VERSION ""

NS_ :

BS_:

BU_: PowertrainControlModule AtmosphericSensor SafetyRestraintSystem2 Aftertreatment_2_GasOutlet Aftertreatment_2_GasIntake DieselParticulateFilterControl Turbocharger SafetyRestraintSystem1 CabDisplay2 Aftertreatment_1_GasOutlet Aftertreatment_1_GasIntake OnBoardDataLogger OffBoardDiagnosticTool2 OffBoardDiagnosticTool1 FileServer ParkingBrakeController SeatController2 FanDriveController SteeringColumnUnit CommunicationUnitRadio CommunicationUnitSatellite CommunicationUnitCellular PropulsionBatteryCharger ChassisController2 ChassisController1 EngineValveControl AuxiliaryHeater2 AuxiliaryHeater1 ClutchUnit RampControl InformationSystem1 SuspensionSystemController2 OilSensor VehicleDynamicStability ExhaustEmissionController TransmissionDisplay2 TransmissionDisplay1 ClimateControl2 WaterPumpController RearAxleSteeringController LightingOperatorControl SeatController1 IgnitionController2 IgnitionController1 TirePressureController CabController2 CabController1 PneumaticSystemController SuspensionSystemController1 HydraulicPumpController EnduranceBrakingSystem RetarderExhaustEngine2 OnBoardDiagnosticUnit HeadwayController RetarderExhaustEngine1 CabDisplay1 ManagementComputer VirtualTerminal OffVehicleGateway PowerTakeOffFront HitchControl AuxiliaryValveControl BodyController TractorTrailerBridge1 StarterSystem ElectricalSystem VehicleSecurity VehicleNavigation AerodynamicControl ElectricalChargingSystem ClimateControl1 TripRecorder InstrumentCluster SuspensionDriveAxle2 SuspensionDriveAxle1 SuspensionSteerAxle SteeringController FuelSystem CruiseControl RetarderDriveline RetarderEngine BrakesDriveAxle2 BrakesDriveAxle1 BrakesSystemController BrakesSteerAxle AxleDrive2 AxleDrive1 AxleSteering PowerTakeOff ShiftConsoleSecondary ShiftConsolePrimary Transmission2 Transmission1 Engine2 Engine1

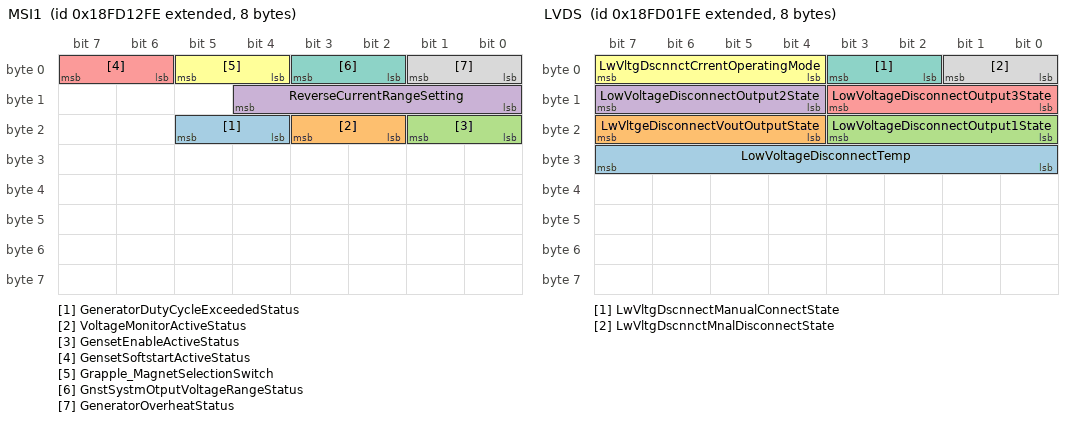
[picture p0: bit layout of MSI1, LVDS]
BO_ 2566722302 MSI1: 8 Vector__XXX
 SG_ GeneratorDutyCycleExceededStatus : 20|2@1+ (1,0) [0|3] "" Vector__XXX
 SG_ VoltageMonitorActiveStatus : 18|2@1+ (1,0) [0|3] "" Vector__XXX
 SG_ GensetEnableActiveStatus : 16|2@1+ (1,0) [0|3] "" Vector__XXX
 SG_ ReverseCurrentRangeSetting : 8|5@1+ (1,0) [0|31] "" Vector__XXX
 SG_ GensetSoftstartActiveStatus : 6|2@1+ (1,0) [0|3] "" Vector__XXX
 SG_ Grapple_MagnetSelectionSwitch : 4|2@1+ (1,0) [0|3] "" Vector__XXX
 SG_ GnstSystmOtputVoltageRangeStatus : 2|2@1+ (1,0) [0|3] "" Vector__XXX
 SG_ GeneratorOverheatStatus : 0|2@1+ (1,0) [0|3] "" Vector__XXX

BO_ 2566722558 MSCI: 8 Vector__XXX
 SG_ MagnetRatedPower : 8|16@1+ (0.5,0) [0|32127.5] "kW" Vector__XXX
 SG_ MagnetBoostTime : 0|8@1+ (0.25,0) [0|62.5] "s" Vector__XXX

BO_ 2560032510 LVDSOM: 8 Vector__XXX
 SG_ LwVltgDscnnctDsiredOperatingMode : 0|4@1+ (1,0) [0|15] "" Vector__XXX

BO_ 2566717950 LVDS: 8 Vector__XXX
 SG_ LowVoltageDisconnectTemp : 24|8@1+ (1,-40) [-40|210] "°C" Vector__XXX
 SG_ LwVltgeDisconnectVoutOutputState : 20|4@1+ (1,0) [0|15] "" Vector__XXX
 SG_ LowVoltageDisconnectOutput1State : 16|4@1+ (1,0) [0|15] "" Vector__XXX
 SG_ LowVoltageDisconnectOutput2State : 12|4@1+ (1,0) [0|15] "" Vector__XXX
 SG_ LowVoltageDisconnectOutput3State : 8|4@1+ (1,0) [0|15] "" Vector__XXX
 SG_ LwVltgDscnnctCrrentOperatingMode : 4|4@1+ (1,0) [0|15] "" Vector__XXX
 SG_ LwVltgDscnnectManualConnectState : 2|2@1+ (1,0) [0|3] "" Vector__XXX
 SG_ LwVltgDscnnctMnalDisconnectState : 0|2@1+ (1,0) [0|3] "" Vector__XXX

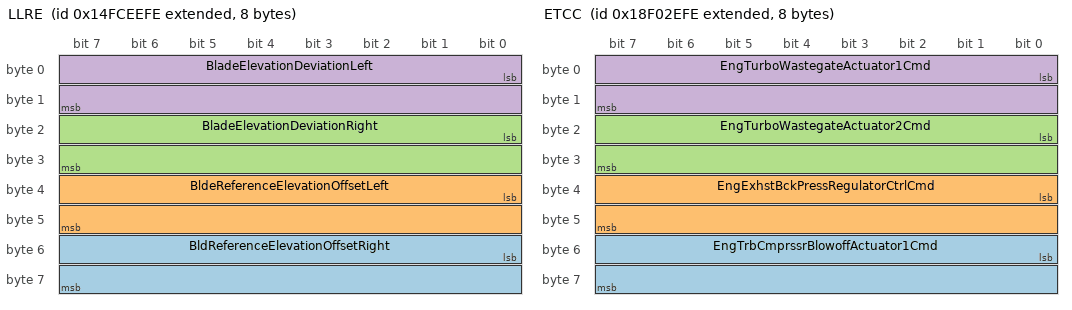
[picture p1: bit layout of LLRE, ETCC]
BO_ 2499604222 LLRE: 8 Vector__XXX
 SG_ BldReferenceElevationOffsetRight : 48|16@1+ (1,-32000) [-32000|32255] "mm" Vector__XXX
 SG_ BldeReferenceElevationOffsetLeft : 32|16@1+ (1,-32000) [-32000|32255] "mm" Vector__XXX
 SG_ BladeElevationDeviationRight : 16|16@1+ (1,-32000) [-32000|32255] "mm" Vector__XXX
 SG_ BladeElevationDeviationLeft : 0|16@1+ (1,-32000) [-32000|32255] "mm" Vector__XXX

BO_ 2358902526 JLCM: 8 Vector__XXX
 SG_ Joystick3Lamp10Cmd : 58|2@1+ (1,0) [0|3] "" Vector__XXX
 SG_ Joystick3Lamp9Cmd : 56|2@1+ (1,0) [0|3] "" Vector__XXX
 SG_ Joystick3Lamp8Cmd : 54|2@1+ (1,0) [0|3] "" Vector__XXX
 SG_ Joystick3Lamp7Cmd : 52|2@1+ (1,0) [0|3] "" Vector__XXX
 SG_ Joystick3Lamp6Cmd : 50|2@1+ (1,0) [0|3] "" Vector__XXX
 SG_ Joystick3Lamp5Cmd : 48|2@1+ (1,0) [0|3] "" Vector__XXX
 SG_ Joystick3Lamp4Cmd : 46|2@1+ (1,0) [0|3] "" Vector__XXX
 SG_ Joystick3Lamp3Cmd : 44|2@1+ (1,0) [0|3] "" Vector__XXX
 SG_ Joystick3Lamp2Cmd : 42|2@1+ (1,0) [0|3] "" Vector__XXX
 SG_ Joystick3Lamp1Cmd : 40|2@1+ (1,0) [0|3] "" Vector__XXX
 SG_ Joystick2Lamp10Cmd : 38|2@1+ (1,0) [0|3] "" Vector__XXX
 SG_ Joystick2Lamp9Cmd : 36|2@1+ (1,0) [0|3] "" Vector__XXX
 SG_ Joystick2Lamp8Cmd : 34|2@1+ (1,0) [0|3] "" Vector__XXX
 SG_ Joystick2Lamp7Cmd : 32|2@1+ (1,0) [0|3] "" Vector__XXX
 SG_ Joystick2Lamp6Cmd : 30|2@1+ (1,0) [0|3] "" Vector__XXX
 SG_ Joystick2Lamp5Cmd : 28|2@1+ (1,0) [0|3] "" Vector__XXX
 SG_ Joystick2Lamp4Cmd : 26|2@1+ (1,0) [0|3] "" Vector__XXX
 SG_ Joystick2Lamp3Cmd : 24|2@1+ (1,0) [0|3] "" Vector__XXX
 SG_ Joystick2Lamp2Cmd : 22|2@1+ (1,0) [0|3] "" Vector__XXX
 SG_ Joystick2Lamp1Cmd : 20|2@1+ (1,0) [0|3] "" Vector__XXX
 SG_ Joystick1Lamp10Cmd : 18|2@1+ (1,0) [0|3] "" Vector__XXX
 SG_ Joystick1Lamp9Cmd : 16|2@1+ (1,0) [0|3] "" Vector__XXX
 SG_ Joystick1Lamp8Cmd : 14|2@1+ (1,0) [0|3] "" Vector__XXX
 SG_ Joystick1Lamp7Cmd : 12|2@1+ (1,0) [0|3] "" Vector__XXX
 SG_ Joystick1Lamp6Cmd : 10|2@1+ (1,0) [0|3] "" Vector__XXX
 SG_ Joystick1Lamp5Cmd : 8|2@1+ (1,0) [0|3] "" Vector__XXX
 SG_ Joystick1Lamp4Cmd : 6|2@1+ (1,0) [0|3] "" Vector__XXX
 SG_ Joystick1Lamp3Cmd : 4|2@1+ (1,0) [0|3] "" Vector__XXX
 SG_ Joystick1Lamp2Cmd : 2|2@1+ (1,0) [0|3] "" Vector__XXX
 SG_ Joystick1Lamp1Cmd : 0|2@1+ (1,0) [0|3] "" Vector__XXX

BO_ 2566711550 IVAC: 8 Vector__XXX
 SG_ IntkVlvActtnSystmOlPrss2SlndCtrl : 2|2@1+ (1,0) [0|3] "" Vector__XXX
 SG_ IntkVlvActtnSystmOlPrss1SlndCtrl : 0|2@1+ (1,0) [0|3] "" Vector__XXX

BO_ 2566719998 HRLFC: 8 Vector__XXX
 SG_ HighResolutionEngTotalFuelUsed : 32|32@1+ (0.001,0) [0|4211081.215] "L" Vector__XXX
 SG_ HighResolutionEngTripFuel : 0|32@1+ (0.001,0) [0|4211081.215] "L" Vector__XXX

BO_ 2565877502 ETCC: 8 Vector__XXX
 SG_ EngTrbCmprssrBlowoffActuator1Cmd : 48|16@1+ (0.0025,0) [0|100] "%" Vector__XXX
 SG_ EngExhstBckPressRegulatorCtrlCmd : 32|16@1+ (0.0025,0) [0|100] "%" Vector__XXX
 SG_ EngTurboWastegateActuator2Cmd : 16|16@1+ (0.0025,0) [0|160.6375] "%" Vector__XXX
 SG_ EngTurboWastegateActuator1Cmd : 0|16@1+ (0.0025,0) [0|160.6375] "%" Vector__XXX

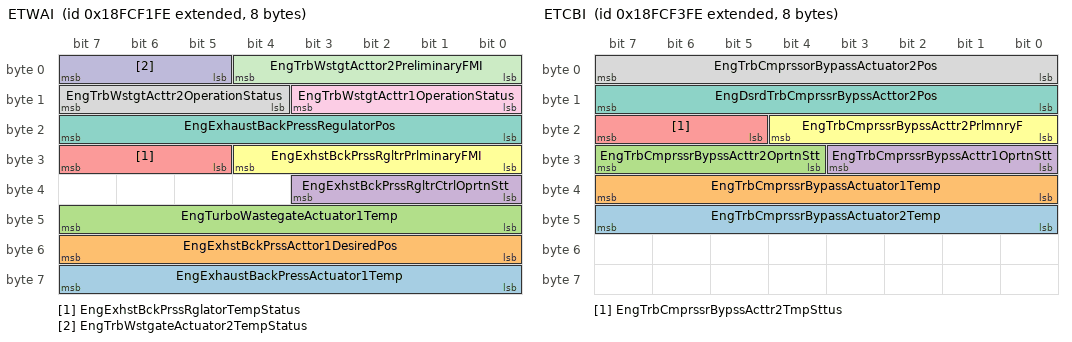
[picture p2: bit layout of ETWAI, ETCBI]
BO_ 2566713854 ETWAI: 8 Vector__XXX
 SG_ EngExhaustBackPressActuator1Temp : 56|8@1+ (1,-40) [-40|210] "°C" Vector__XXX
 SG_ EngExhstBckPrssActtor1DesiredPos : 48|8@1+ (0.4,0) [0|100] "%" Vector__XXX
 SG_ EngTurboWastegateActuator1Temp : 40|8@1+ (1,-40) [-40|210] "°C" Vector__XXX
 SG_ EngExhstBckPrssRgltrCtrlOprtnStt : 32|4@1+ (1,0) [0|15] "" Vector__XXX
 SG_ EngExhstBckPrssRglatorTempStatus : 29|3@1+ (1,0) [0|7] "" Vector__XXX
 SG_ EngExhstBckPrssRgltrPrlminaryFMI : 24|5@1+ (1,0) [0|31] "" Vector__XXX
 SG_ EngExhaustBackPressRegulatorPos : 16|8@1+ (0.4,0) [0|100] "%" Vector__XXX
 SG_ EngTrbWstgtActtr2OperationStatus : 12|4@1+ (1,0) [0|15] "" Vector__XXX
 SG_ EngTrbWstgtActtr1OperationStatus : 8|4@1+ (1,0) [0|15] "" Vector__XXX
 SG_ EngTrbWstgateActuator2TempStatus : 5|3@1+ (1,0) [0|7] "" Vector__XXX
 SG_ EngTrbWstgtActtor2PreliminaryFMI : 0|5@1+ (1,0) [0|31] "" Vector__XXX

BO_ 2566714366 ETCBI: 8 Vector__XXX
 SG_ EngTrbCmprssrBypassActuator2Temp : 40|8@1+ (1,-40) [-40|210] "°C" Vector__XXX
 SG_ EngTrbCmprssrBypassActuator1Temp : 32|8@1+ (1,-40) [-40|210] "°C" Vector__XXX
 SG_ EngTrbCmprssrBypssActtr2OprtnStt : 28|4@1+ (1,0) [0|15] "" Vector__XXX
 SG_ EngTrbCmprssrBypssActtr1OprtnStt : 24|4@1+ (1,0) [0|15] "" Vector__XXX
 SG_ EngTrbCmprssrBypssActtr2TmpSttus : 21|3@1+ (1,0) [0|7] "" Vector__XXX
 SG_ EngTrbCmprssrBypssActtr2PrlmnryF : 16|5@1+ (1,0) [0|31] "" Vector__XXX
 SG_ EngDsrdTrbCmprssrBypssActtor2Pos : 8|8@1+ (0.4,0) [0|100] "%" Vector__XXX
 SG_ EngTrbCmprssorBypassActuator2Pos : 0|8@1+ (0.4,0) [0|100] "%" Vector__XXX

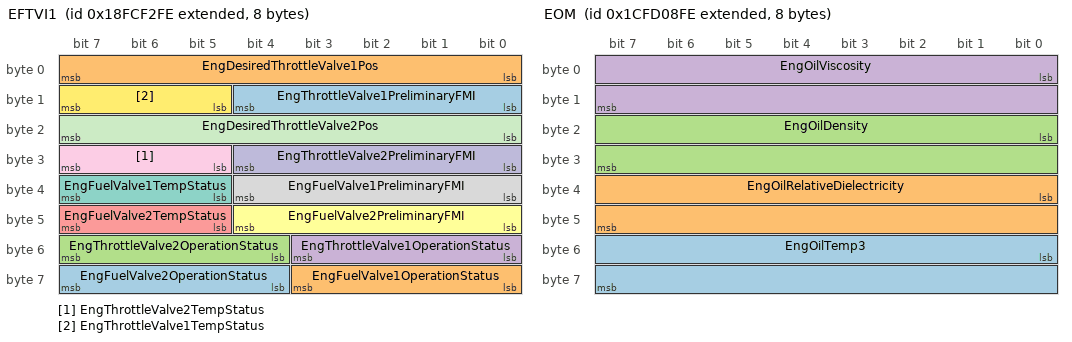
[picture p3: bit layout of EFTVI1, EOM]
BO_ 2566714110 EFTVI1: 8 Vector__XXX
 SG_ EngFuelValve2OperationStatus : 60|4@1+ (1,0) [0|15] "" Vector__XXX
 SG_ EngFuelValve1OperationStatus : 56|4@1+ (1,0) [0|15] "" Vector__XXX
 SG_ EngThrottleValve2OperationStatus : 52|4@1+ (1,0) [0|15] "" Vector__XXX
 SG_ EngThrottleValve1OperationStatus : 48|4@1+ (1,0) [0|15] "" Vector__XXX
 SG_ EngFuelValve2TempStatus : 45|3@1+ (1,0) [0|7] "" Vector__XXX
 SG_ EngFuelValve2PreliminaryFMI : 40|5@1+ (1,0) [0|31] "" Vector__XXX
 SG_ EngFuelValve1TempStatus : 37|3@1+ (1,0) [0|7] "" Vector__XXX
 SG_ EngFuelValve1PreliminaryFMI : 32|5@1+ (1,0) [0|31] "" Vector__XXX
 SG_ EngThrottleValve2TempStatus : 29|3@1+ (1,0) [0|7] "" Vector__XXX
 SG_ EngThrottleValve2PreliminaryFMI : 24|5@1+ (1,0) [0|31] "" Vector__XXX
 SG_ EngDesiredThrottleValve2Pos : 16|8@1+ (0.4,0) [0|100] "%" Vector__XXX
 SG_ EngThrottleValve1TempStatus : 13|3@1+ (1,0) [0|7] "" Vector__XXX
 SG_ EngThrottleValve1PreliminaryFMI : 8|5@1+ (1,0) [0|31] "" Vector__XXX
 SG_ EngDesiredThrottleValve1Pos : 0|8@1+ (0.4,0) [0|100] "%" Vector__XXX

BO_ 2566717438 ET5: 8 Vector__XXX
 SG_ EngExhstGsRcrcltn2MxerIntakeTemp : 16|16@1+ (0.03125,-273) [-273|1734.96875] "°C" Vector__XXX
 SG_ EngExhaustGasRecirculation2Temp : 0|16@1+ (0.03125,-273) [-273|1734.96875] "°C" Vector__XXX

BO_ 2633828606 EOM: 8 Vector__XXX
 SG_ EngOilTemp3 : 48|16@1+ (0.03125,-273) [-273|1734.96875] "°C" Vector__XXX
 SG_ EngOilRelativeDielectricity : 32|16@1+ (0.0001220703125,0) [0|7.844] "" Vector__XXX
 SG_ EngOilDensity : 16|16@1+ (3.052E-005,0) [0|1.961] "g/cc" Vector__XXX
 SG_ EngOilViscosity : 0|16@1+ (0.015625,0) [0|1003.984375] "Cp" Vector__XXX

BO_ 2499607550 EMAP: 8 Vector__XXX
 SG_ EngExhstMnfldBnk2FlwBlncVlvActtr : 16|16@1+ (0.0025,0) [0|160.6375] "%" Vector__XXX
 SG_ EngExhstMnfldBnk1FlwBlncVlvActtr : 0|16@1+ (0.0025,0) [0|160.6375] "%" Vector__XXX

BO_ 2633825534 EMAC: 8 Vector__XXX
 SG_ EngExhstMnfldBnk2FlwBlncVlvActtr : 16|16@1+ (0.0025,0) [0|160.6375] "%" Vector__XXX
 SG_ EngExhstMnfldBnk1FlwBlncVlvActtr : 0|16@1+ (0.0025,0) [0|160.6375] "%" Vector__XXX

BO_ 2365400574 EJM9: 8 Vector__XXX
 SG_ Joystick9Button13PressedStatus : 62|2@1+ (1,0) [0|3] "" Vector__XXX
 SG_ Joystick9Button14PressedStatus : 60|2@1+ (1,0) [0|3] "" Vector__XXX
 SG_ Joystick9Button15PressedStatus : 58|2@1+ (1,0) [0|3] "" Vector__XXX
 SG_ Joystick9Button16PressedStatus : 56|2@1+ (1,0) [0|3] "" Vector__XXX
 SG_ Jystick9GripXAxisDetentPosStatus : 54|2@1+ (1,0) [0|3] "" Vector__XXX
 SG_ Jystick9GripYAxisDetentPosStatus : 52|2@1+ (1,0) [0|3] "" Vector__XXX
 SG_ Jystick9ThetaAxisDetentPosStatus : 50|2@1+ (1,0) [0|3] "" Vector__XXX
 SG_ Joystick9ThetaAxisPos : 38|10@1+ (0.1,0) [0|102] "%" Vector__XXX
 SG_ Jystck9ThtAxsClckwsPstvPosStatus : 36|2@1+ (1,0) [0|3] "" Vector__XXX
 SG_ Jystck9ThtAxsCntrClckwsNgtvPsStt : 34|2@1+ (1,0) [0|3] "" Vector__XXX
 SG_ Jystck9ThetaAxisNeutralPosStatus : 32|2@1+ (1,0) [0|3] "" Vector__XXX
 SG_ Joystick9GripYAxisPos : 22|10@1+ (0.1,0) [0|102] "%" Vector__XXX
 SG_ Jystck9GrpYAxsLvrFrwrdPstvPsStts : 20|2@1+ (1,0) [0|3] "" Vector__XXX
 SG_ Jystck9GrpYAxsLvrBckNgtvPsStatus : 18|2@1+ (1,0) [0|3] "" Vector__XXX
 SG_ Jystck9GripYAxisNeutralPosStatus : 16|2@1+ (1,0) [0|3] "" Vector__XXX
 SG_ Joystick9GripXAxisPos : 6|10@1+ (0.1,0) [0|102] "%" Vector__XXX
 SG_ Jystck9GrpXAxsLvrRghtPstvPsSttus : 4|2@1+ (1,0) [0|3] "" Vector__XXX
 SG_ Jystck9GrpXAxsLvrLftNgtvPsStatus : 2|2@1+ (1,0) [0|3] "" Vector__XXX
 SG_ Jystck9GripXAxisNeutralPosStatus : 0|2@1+ (1,0) [0|3] "" Vector__XXX

BO_ 2365401086 EJM8: 8 Vector__XXX
 SG_ Joystick8Button13PressedStatus : 62|2@1+ (1,0) [0|3] "" Vector__XXX
 SG_ Joystick8Button14PressedStatus : 60|2@1+ (1,0) [0|3] "" Vector__XXX
 SG_ Joystick8Button15PressedStatus : 58|2@1+ (1,0) [0|3] "" Vector__XXX
 SG_ Joystick8Button16PressedStatus : 56|2@1+ (1,0) [0|3] "" Vector__XXX
 SG_ Jystick8GripXAxisDetentPosStatus : 54|2@1+ (1,0) [0|3] "" Vector__XXX
 SG_ Jystick8GripYAxisDetentPosStatus : 52|2@1+ (1,0) [0|3] "" Vector__XXX
 SG_ Jystick8ThetaAxisDetentPosStatus : 50|2@1+ (1,0) [0|3] "" Vector__XXX
 SG_ Joystick8ThetaAxisPos : 38|10@1+ (0.1,0) [0|102] "%" Vector__XXX
 SG_ Jystck8ThtAxsClckwsPstvPosStatus : 36|2@1+ (1,0) [0|3] "" Vector__XXX
 SG_ Jystck8ThtAxsCntrClckwsNgtvPsStt : 34|2@1+ (1,0) [0|3] "" Vector__XXX
 SG_ Jystck8ThetaAxisNeutralPosStatus : 32|2@1+ (1,0) [0|3] "" Vector__XXX
 SG_ Joystick8GripYAxisPos : 22|10@1+ (0.1,0) [0|102] "%" Vector__XXX
 SG_ Jystck8GrpYAxsLvrFrwrdPstvPsStts : 20|2@1+ (1,0) [0|3] "" Vector__XXX
 SG_ Jystck8GrpYAxsLvrBckNgtvPsStatus : 18|2@1+ (1,0) [0|3] "" Vector__XXX
 SG_ Jystck8GripYAxisNeutralPosStatus : 16|2@1+ (1,0) [0|3] "" Vector__XXX
 SG_ Joystick8GripXAxisPos : 6|10@1+ (0.1,0) [0|102] "%" Vector__XXX
 SG_ Jystck8GrpXAxsLvrRghtPstvPsSttus : 4|2@1+ (1,0) [0|3] "" Vector__XXX
 SG_ Jystck8GrpXAxsLvrLftNgtvPsStatus : 2|2@1+ (1,0) [0|3] "" Vector__XXX
 SG_ Jystck8GripXAxisNeutralPosStatus : 0|2@1+ (1,0) [0|3] "" Vector__XXX

BO_ 2365401598 EJM7: 8 Vector__XXX
 SG_ Joystick7Button13PressedStatus : 62|2@1+ (1,0) [0|3] "" Vector__XXX
 SG_ Joystick7Button14PressedStatus : 60|2@1+ (1,0) [0|3] "" Vector__XXX
 SG_ Joystick7Button15PressedStatus : 58|2@1+ (1,0) [0|3] "" Vector__XXX
 SG_ Joystick7Button16PressedStatus : 56|2@1+ (1,0) [0|3] "" Vector__XXX
 SG_ Jystick7GripXAxisDetentPosStatus : 54|2@1+ (1,0) [0|3] "" Vector__XXX
 SG_ Jystick7GripYAxisDetentPosStatus : 52|2@1+ (1,0) [0|3] "" Vector__XXX
 SG_ Jystick7ThetaAxisDetentPosStatus : 50|2@1+ (1,0) [0|3] "" Vector__XXX
 SG_ Joystick7ThetaAxisPos : 38|10@1+ (0.1,0) [0|102] "%" Vector__XXX
 SG_ Jystck7ThtAxsClckwsPstvPosStatus : 36|2@1+ (1,0) [0|3] "" Vector__XXX
 SG_ Jystck7ThtAxsCntrClckwsNgtvPsStt : 34|2@1+ (1,0) [0|3] "" Vector__XXX
 SG_ Jystck7ThetaAxisNeutralPosStatus : 32|2@1+ (1,0) [0|3] "" Vector__XXX
 SG_ Joystick7GripYAxisPos : 22|10@1+ (0.1,0) [0|102] "%" Vector__XXX
 SG_ Jystck7GrpYAxsLvrFrwrdPstvPsStts : 20|2@1+ (1,0) [0|3] "" Vector__XXX
 SG_ Jystck7GrpYAxsLvrBckNgtvPsStatus : 18|2@1+ (1,0) [0|3] "" Vector__XXX
 SG_ Jystck7GripYAxisNeutralPosStatus : 16|2@1+ (1,0) [0|3] "" Vector__XXX
 SG_ Joystick7GripXAxisPos : 6|10@1+ (0.1,0) [0|102] "%" Vector__XXX
 SG_ Jystck7GrpXAxsLvrRghtPstvPsSttus : 4|2@1+ (1,0) [0|3] "" Vector__XXX
 SG_ Jystck7GrpXAxsLvrLftNgtvPsStatus : 2|2@1+ (1,0) [0|3] "" Vector__XXX
 SG_ Jystck7GripXAxisNeutralPosStatus : 0|2@1+ (1,0) [0|3] "" Vector__XXX

BO_ 2365402110 EJM6: 8 Vector__XXX
 SG_ Joystick6Button13PressedStatus : 62|2@1+ (1,0) [0|3] "" Vector__XXX
 SG_ Joystick6Button14PressedStatus : 60|2@1+ (1,0) [0|3] "" Vector__XXX
 SG_ Joystick6Button15PressedStatus : 58|2@1+ (1,0) [0|3] "" Vector__XXX
 SG_ Joystick6Button16PressedStatus : 56|2@1+ (1,0) [0|3] "" Vector__XXX
 SG_ Jystick6GripXAxisDetentPosStatus : 54|2@1+ (1,0) [0|3] "" Vector__XXX
 SG_ Jystick6GripYAxisDetentPosStatus : 52|2@1+ (1,0) [0|3] "" Vector__XXX
 SG_ Jystick6ThetaAxisDetentPosStatus : 50|2@1+ (1,0) [0|3] "" Vector__XXX
 SG_ Joystick6ThetaAxisPos : 38|10@1+ (0.1,0) [0|102] "%" Vector__XXX
 SG_ Jystck6ThtAxsClckwsPstvPosStatus : 36|2@1+ (1,0) [0|3] "" Vector__XXX
 SG_ Jystck6ThtAxsCntrClckwsNgtvPsStt : 34|2@1+ (1,0) [0|3] "" Vector__XXX
 SG_ Jystck6ThetaAxisNeutralPosStatus : 32|2@1+ (1,0) [0|3] "" Vector__XXX
 SG_ Joystick6GripYAxisPos : 22|10@1+ (0.1,0) [0|102] "%" Vector__XXX
 SG_ Jystck6GrpYAxsLvrFrwrdPstvPsStts : 20|2@1+ (1,0) [0|3] "" Vector__XXX
 SG_ Jystck6GrpYAxsLvrBckNgtvPsStatus : 18|2@1+ (1,0) [0|3] "" Vector__XXX
 SG_ Jystck6GripYAxisNeutralPosStatus : 16|2@1+ (1,0) [0|3] "" Vector__XXX
 SG_ Joystick6GripXAxisPos : 6|10@1+ (0.1,0) [0|102] "%" Vector__XXX
 SG_ Jystck6GrpXAxsLvrRghtPstvPsSttus : 4|2@1+ (1,0) [0|3] "" Vector__XXX
 SG_ Jystck6GrpXAxsLvrLftNgtvPsStatus : 2|2@1+ (1,0) [0|3] "" Vector__XXX
 SG_ Jystck6GripXAxisNeutralPosStatus : 0|2@1+ (1,0) [0|3] "" Vector__XXX

BO_ 2365402622 EJM5: 8 Vector__XXX
 SG_ Joystick5Button13PressedStatus : 62|2@1+ (1,0) [0|3] "" Vector__XXX
 SG_ Joystick5Button14PressedStatus : 60|2@1+ (1,0) [0|3] "" Vector__XXX
 SG_ Joystick5Button15PressedStatus : 58|2@1+ (1,0) [0|3] "" Vector__XXX
 SG_ Joystick5Button16PressedStatus : 56|2@1+ (1,0) [0|3] "" Vector__XXX
 SG_ Jystick5GripXAxisDetentPosStatus : 54|2@1+ (1,0) [0|3] "" Vector__XXX
 SG_ Jystick5GripYAxisDetentPosStatus : 52|2@1+ (1,0) [0|3] "" Vector__XXX
 SG_ Jystick5ThetaAxisDetentPosStatus : 50|2@1+ (1,0) [0|3] "" Vector__XXX
 SG_ Joystick5ThetaAxisPos : 38|10@1+ (0.1,0) [0|102] "%" Vector__XXX
 SG_ Jystck5ThtAxsClckwsPstvPosStatus : 36|2@1+ (1,0) [0|3] "" Vector__XXX
 SG_ Jystck5ThtAxsCntrClckwsNgtvPsStt : 34|2@1+ (1,0) [0|3] "" Vector__XXX
 SG_ Jystck5ThetaAxisNeutralPosStatus : 32|2@1+ (1,0) [0|3] "" Vector__XXX
 SG_ Joystick5GripYAxisPos : 22|10@1+ (0.1,0) [0|102] "%" Vector__XXX
 SG_ Jystck5GrpYAxsLvrFrwrdPstvPsStts : 20|2@1+ (1,0) [0|3] "" Vector__XXX
 SG_ Jystck5GrpYAxsLvrBckNgtvPsStatus : 18|2@1+ (1,0) [0|3] "" Vector__XXX
 SG_ Jystck5GripYAxisNeutralPosStatus : 16|2@1+ (1,0) [0|3] "" Vector__XXX
 SG_ Joystick5GripXAxisPos : 6|10@1+ (0.1,0) [0|102] "%" Vector__XXX
 SG_ Jystck5GrpXAxsLvrRghtPstvPsSttus : 4|2@1+ (1,0) [0|3] "" Vector__XXX
 SG_ Jystck5GrpXAxsLvrLftNgtvPsStatus : 2|2@1+ (1,0) [0|3] "" Vector__XXX
 SG_ Jystck5GripXAxisNeutralPosStatus : 0|2@1+ (1,0) [0|3] "" Vector__XXX

BO_ 2365403134 EJM4: 8 Vector__XXX
 SG_ Joystick4Button13PressedStatus : 62|2@1+ (1,0) [0|3] "" Vector__XXX
 SG_ Joystick4Button14PressedStatus : 60|2@1+ (1,0) [0|3] "" Vector__XXX
 SG_ Joystick4Button15PressedStatus : 58|2@1+ (1,0) [0|3] "" Vector__XXX
 SG_ Joystick4Button16PressedStatus : 56|2@1+ (1,0) [0|3] "" Vector__XXX
 SG_ Jystick4GripXAxisDetentPosStatus : 54|2@1+ (1,0) [0|3] "" Vector__XXX
 SG_ Jystick4GripYAxisDetentPosStatus : 52|2@1+ (1,0) [0|3] "" Vector__XXX
 SG_ Jystick4ThetaAxisDetentPosStatus : 50|2@1+ (1,0) [0|3] "" Vector__XXX
 SG_ Joystick4ThetaAxisPos : 38|10@1+ (0.1,0) [0|102] "%" Vector__XXX
 SG_ Jystck4ThtAxsClckwsPstvPosStatus : 36|2@1+ (1,0) [0|3] "" Vector__XXX
 SG_ Jystck4ThtAxsCntrClckwsNgtvPsStt : 34|2@1+ (1,0) [0|3] "" Vector__XXX
 SG_ Jystck4ThetaAxisNeutralPosStatus : 32|2@1+ (1,0) [0|3] "" Vector__XXX
 SG_ Joystick4GripYAxisPos : 22|10@1+ (0.1,0) [0|102] "%" Vector__XXX
 SG_ Jystck4GrpYAxsLvrFrwrdPstvPsStts : 20|2@1+ (1,0) [0|3] "" Vector__XXX
 SG_ Jystck4GrpYAxsLvrBckNgtvPsStatus : 18|2@1+ (1,0) [0|3] "" Vector__XXX
 SG_ Jystck4GripYAxisNeutralPosStatus : 16|2@1+ (1,0) [0|3] "" Vector__XXX
 SG_ Joystick4GripXAxisPos : 6|10@1+ (0.1,0) [0|102] "%" Vector__XXX
 SG_ Jystck4GrpXAxsLvrRghtPstvPsSttus : 4|2@1+ (1,0) [0|3] "" Vector__XXX
 SG_ Jystck4GrpXAxsLvrLftNgtvPsStatus : 2|2@1+ (1,0) [0|3] "" Vector__XXX
 SG_ Jystck4GripXAxisNeutralPosStatus : 0|2@1+ (1,0) [0|3] "" Vector__XXX

BO_ 2365400062 EJM10: 8 Vector__XXX
 SG_ Joystick10Button13PressedStatus : 62|2@1+ (1,0) [0|3] "" Vector__XXX
 SG_ Joystick10Button14PressedStatus : 60|2@1+ (1,0) [0|3] "" Vector__XXX
 SG_ Joystick10Button15PressedStatus : 58|2@1+ (1,0) [0|3] "" Vector__XXX
 SG_ Joystick10Button16PressedStatus : 56|2@1+ (1,0) [0|3] "" Vector__XXX
 SG_ Jystck10GripXAxisDetentPosStatus : 54|2@1+ (1,0) [0|3] "" Vector__XXX
 SG_ Jystck10GripYAxisDetentPosStatus : 52|2@1+ (1,0) [0|3] "" Vector__XXX
 SG_ Jystck10ThetaAxisDetentPosStatus : 50|2@1+ (1,0) [0|3] "" Vector__XXX
 SG_ Joystick10ThetaAxisPos : 38|10@1+ (0.1,0) [0|102] "%" Vector__XXX
 SG_ Jystck10ThtAxsClckwsPstvPsStatus : 36|2@1+ (1,0) [0|3] "" Vector__XXX
 SG_ Jystck10ThtAxsCntrClckwsNgtvPsSt : 34|2@1+ (1,0) [0|3] "" Vector__XXX
 SG_ Jystck10ThtaAxisNeutralPosStatus : 32|2@1+ (1,0) [0|3] "" Vector__XXX
 SG_ Joystick10GripYAxisPos : 22|10@1+ (0.1,0) [0|102] "%" Vector__XXX
 SG_ Jystck10GrpYAxsLvrFrwrdPstvPsStt : 20|2@1+ (1,0) [0|3] "" Vector__XXX
 SG_ Jystck10GrpYAxsLvrBckNgtvPsSttus : 18|2@1+ (1,0) [0|3] "" Vector__XXX
 SG_ Jystck10GrpYAxisNeutralPosStatus : 16|2@1+ (1,0) [0|3] "" Vector__XXX
 SG_ Joystick10GripXAxisPos : 6|10@1+ (0.1,0) [0|102] "%" Vector__XXX
 SG_ Jystck10GrpXAxsLvrRghtPstvPsStts : 4|2@1+ (1,0) [0|3] "" Vector__XXX
 SG_ Jystck10GrpXAxsLvrLftNgtvPsSttus : 2|2@1+ (1,0) [0|3] "" Vector__XXX
 SG_ Jystck10GrpXAxisNeutralPosStatus : 0|2@1+ (1,0) [0|3] "" Vector__XXX

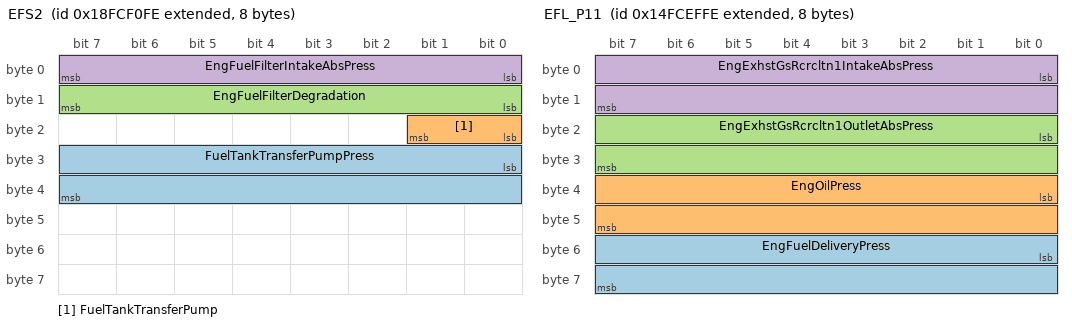
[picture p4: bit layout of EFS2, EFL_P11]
BO_ 2566713598 EFS2: 8 Vector__XXX
 SG_ FuelTankTransferPumpPress : 24|16@1+ (0.1,0) [0|6425.5] "kPa" Vector__XXX
 SG_ FuelTankTransferPump : 16|2@1+ (1,0) [0|3] "" Vector__XXX
 SG_ EngFuelFilterDegradation : 8|8@1+ (1,0) [0|250] "%" Vector__XXX
 SG_ EngFuelFilterIntakeAbsPress : 0|8@1+ (2,0) [0|500] "kPa" Vector__XXX

BO_ 2499604478 EFL_P11: 8 Vector__XXX
 SG_ EngFuelDeliveryPress : 48|16@1+ (0.1,0) [0|6425.5] "kPa" Vector__XXX
 SG_ EngOilPress : 32|16@1+ (0.1,0) [0|6425.5] "kPa" Vector__XXX
 SG_ EngExhstGsRcrcltn1OutletAbsPress : 16|16@1+ (0.1,0) [0|6425.5] "kPa" Vector__XXX
 SG_ EngExhstGsRcrcltn1IntakeAbsPress : 0|16@1+ (0.1,0) [0|6425.5] "kPa" Vector__XXX

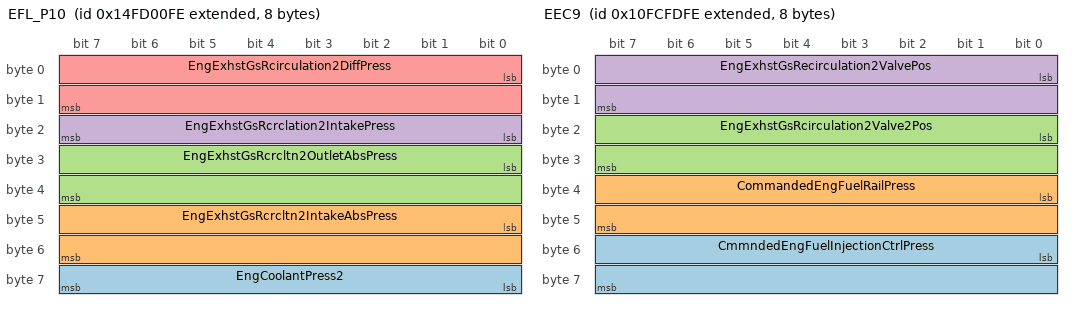
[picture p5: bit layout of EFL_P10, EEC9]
BO_ 2499608830 EFL_P10: 8 Vector__XXX
 SG_ EngCoolantPress2 : 56|8@1+ (2,0) [0|500] "kPa" Vector__XXX
 SG_ EngExhstGsRcrcltn2IntakeAbsPress : 40|16@1+ (0.1,0) [0|6425.5] "kPa" Vector__XXX
 SG_ EngExhstGsRcrcltn2OutletAbsPress : 24|16@1+ (0.1,0) [0|6425.5] "kPa" Vector__XXX
 SG_ EngExhstGsRcrclation2IntakePress : 16|8@1+ (2,0) [0|500] "kPa" Vector__XXX
 SG_ EngExhstGsRcirculation2DiffPress : 0|16@1+ (0.0078125,-250) [-250|251.99] "kPa" Vector__XXX

BO_ 2432499198 EEC9: 8 Vector__XXX
 SG_ CmmndedEngFuelInjectionCtrlPress : 48|16@1+ (0.00390625,0) [0|250.996] "MPa" Vector__XXX
 SG_ CommandedEngFuelRailPress : 32|16@1+ (0.00390625,0) [0|250.996] "MPa" Vector__XXX
 SG_ EngExhstGsRcirculation2Valve2Pos : 16|16@1+ (0.0025,0) [0|160.6375] "%" Vector__XXX
 SG_ EngExhstGsRecirculation2ValvePos : 0|16@1+ (0.0025,0) [0|160.6375] "%" Vector__XXX

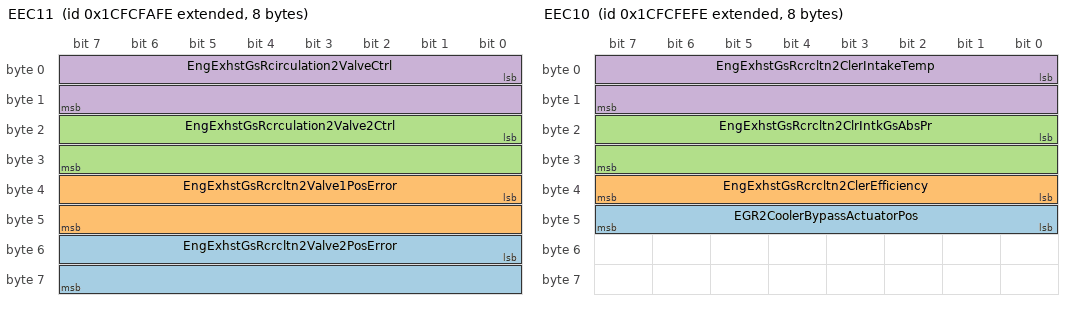
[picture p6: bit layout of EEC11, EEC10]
BO_ 2633825022 EEC11: 8 Vector__XXX
 SG_ EngExhstGsRcrcltn2Valve2PosError : 48|16@1+ (0.004,-125) [-125|132.02] "%" Vector__XXX
 SG_ EngExhstGsRcrcltn2Valve1PosError : 32|16@1+ (0.004,-125) [-125|132.02] "%" Vector__XXX
 SG_ EngExhstGsRcrculation2Valve2Ctrl : 16|16@1+ (0.0025,0) [0|160.6375] "%" Vector__XXX
 SG_ EngExhstGsRcirculation2ValveCtrl : 0|16@1+ (0.0025,0) [0|160.6375] "%" Vector__XXX

BO_ 2633826046 EEC10: 8 Vector__XXX
 SG_ EGR2CoolerBypassActuatorPos : 40|8@1+ (0.4,0) [0|100] "%" Vector__XXX
 SG_ EngExhstGsRcrcltn2ClerEfficiency : 32|8@1+ (0.4,0) [0|100] "%" Vector__XXX
 SG_ EngExhstGsRcrcltn2ClrIntkGsAbsPr : 16|16@1+ (0.5,0) [0|32127.5] "kPa" Vector__XXX
 SG_ EngExhstGsRcrcltn2ClerIntakeTemp : 0|16@1+ (0.03125,-273) [-273|1734.96875] "°C" Vector__XXX

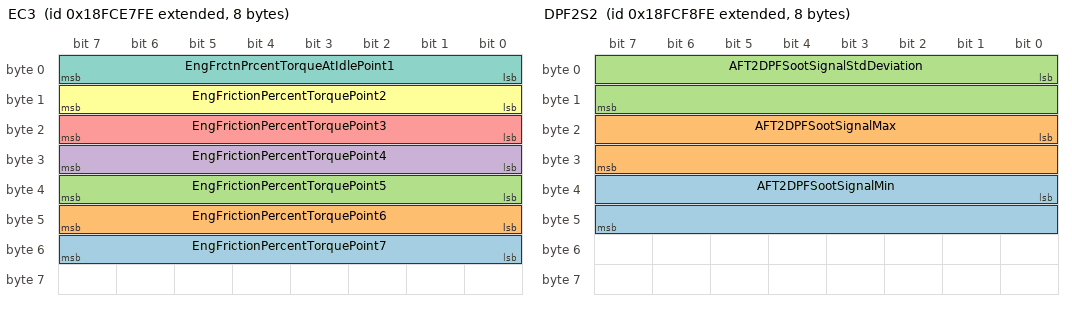
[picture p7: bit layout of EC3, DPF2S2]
BO_ 2566711294 EC3: 8 Vector__XXX
 SG_ EngFrictionPercentTorquePoint7 : 48|8@1+ (1,-125) [0|125] "%" Vector__XXX
 SG_ EngFrictionPercentTorquePoint6 : 40|8@1+ (1,-125) [0|125] "%" Vector__XXX
 SG_ EngFrictionPercentTorquePoint5 : 32|8@1+ (1,-125) [0|125] "%" Vector__XXX
 SG_ EngFrictionPercentTorquePoint4 : 24|8@1+ (1,-125) [0|125] "%" Vector__XXX
 SG_ EngFrictionPercentTorquePoint3 : 16|8@1+ (1,-125) [0|125] "%" Vector__XXX
 SG_ EngFrictionPercentTorquePoint2 : 8|8@1+ (1,-125) [0|125] "%" Vector__XXX
 SG_ EngFrctnPrcentTorqueAtIdlePoint1 : 0|8@1+ (1,-125) [0|125] "%" Vector__XXX

BO_ 2566749438 DPFC1: 8 Vector__XXX
 SG_ DslPrtcltFltrActvRgnrtnInhbt5629 : 58|2@1+ (1,0) [0|3] "" Vector__XXX
 SG_ AFT1DPFCondNotMetForActiveRegen : 60|2@1+ (1,0) [0|3] "" Vector__XXX
 SG_ HydrocarbonDoserPurgingEnable : 56|2@1+ (1,0) [0|3] "" Vector__XXX
 SG_ DslPrtcltFltrActvRgnrtnFrcdSttus : 53|3@1+ (1,0) [0|7] "" Vector__XXX
 SG_ ExhaustSystemHighTempLampCmd : 50|3@1+ (1,0) [0|7] "" Vector__XXX
 SG_ DslPrtcltFltrAtmtcActvRgnrtnIntt : 48|2@1+ (1,0) [0|3] "" Vector__XXX
 SG_ DslPrtcltFltrActvRgnrtnInhbt3717 : 46|2@1+ (1,0) [0|3] "" Vector__XXX
 SG_ DslPrtcltFltrActvRgnrtnInhbtdDTE : 44|2@1+ (1,0) [0|3] "" Vector__XXX
 SG_ DslPrtcltFltrActvRgnrtnInhbt3715 : 42|2@1+ (1,0) [0|3] "" Vector__XXX
 SG_ DslPrtcltFltrActvRgnrtnInhbtdDTT : 40|2@1+ (1,0) [0|3] "" Vector__XXX
 SG_ DslPrtcltFltrActvRgnrtnInhbt3713 : 38|2@1+ (1,0) [0|3] "" Vector__XXX
 SG_ DslPrtcltFltrActvRgnrtnInhbt3712 : 36|2@1+ (1,0) [0|3] "" Vector__XXX
 SG_ DslPrtcltFltrActvRgnrtnInhbtdDTL : 34|2@1+ (1,0) [0|3] "" Vector__XXX
 SG_ DslPrtcltFltrActvRgnrtnInhbt3710 : 32|2@1+ (1,0) [0|3] "" Vector__XXX
 SG_ DslPrtcltFltrActvRgnrtnInhbtdDTV : 30|2@1+ (1,0) [0|3] "" Vector__XXX
 SG_ DslPrtcltFltrActvRgnrtnInhbtdDTO : 28|2@1+ (1,0) [0|3] "" Vector__XXX
 SG_ DslPrtcltFltrActvRgnrtnInhbtdDTA : 26|2@1+ (1,0) [0|3] "" Vector__XXX
 SG_ DslPrtcltFltrActvRgnrtnInhbtdDTP : 24|2@1+ (1,0) [0|3] "" Vector__XXX
 SG_ DslPrtcltFltrActvRgnrtnInhbtdDTS : 22|2@1+ (1,0) [0|3] "" Vector__XXX
 SG_ DslPrtcltFltrActvRgnrtnInhbtdDTC : 20|2@1+ (1,0) [0|3] "" Vector__XXX
 SG_ DslPrtcltFltrActvRgnrtnInhbtdDTI : 18|2@1+ (1,0) [0|3] "" Vector__XXX
 SG_ DslPrtcltFltrActvRgnrtnInhbtdStt : 16|2@1+ (1,0) [0|3] "" Vector__XXX
 SG_ AFTDPFStatus : 12|3@1+ (1,0) [0|7] "" Vector__XXX
 SG_ AFTDPFActiveRegenStatus : 10|2@1+ (1,0) [0|3] "" Vector__XXX
 SG_ AFTDPFPassiveRegenStatus : 8|2@1+ (1,0) [0|3] "" Vector__XXX
 SG_ DieselParticulateFilterLampCmd : 0|3@1+ (1,0) [0|7] "" Vector__XXX

BO_ 2566715646 DPF2S2: 8 Vector__XXX
 SG_ AFT2DPFSootSignalMin : 32|16@1+ (0.0025,0) [0|160.6375] "%" Vector__XXX
 SG_ AFT2DPFSootSignalMax : 16|16@1+ (0.0025,0) [0|160.6375] "%" Vector__XXX
 SG_ AFT2DPFSootSignalStdDeviation : 0|16@1+ (0.0025,0) [0|160.6375] "%" Vector__XXX

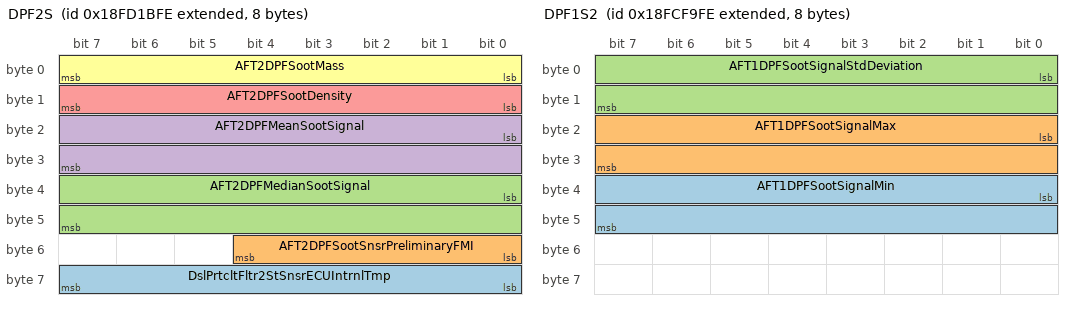
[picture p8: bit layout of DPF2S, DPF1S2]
BO_ 2566724606 DPF2S: 8 Vector__XXX
 SG_ DslPrtcltFltr2StSnsrECUIntrnlTmp : 56|8@1+ (1,-40) [-40|210] "°C" Vector__XXX
 SG_ AFT2DPFSootSnsrPreliminaryFMI : 48|5@1+ (1,0) [0|31] "" Vector__XXX
 SG_ AFT2DPFMedianSootSignal : 32|16@1+ (0.0025,0) [0|160.6375] "%" Vector__XXX
 SG_ AFT2DPFMeanSootSignal : 16|16@1+ (0.0025,0) [0|160.6375] "%" Vector__XXX
 SG_ AFT2DPFSootDensity : 8|8@1+ (0.08,0) [0|20] "g/L" Vector__XXX
 SG_ AFT2DPFSootMass : 0|8@1+ (4,0) [0|1000] "g" Vector__XXX

BO_ 2566715902 DPF1S2: 8 Vector__XXX
 SG_ AFT1DPFSootSignalMin : 32|16@1+ (0.0025,0) [0|160.6375] "%" Vector__XXX
 SG_ AFT1DPFSootSignalMax : 16|16@1+ (0.0025,0) [0|160.6375] "%" Vector__XXX
 SG_ AFT1DPFSootSignalStdDeviation : 0|16@1+ (0.0025,0) [0|160.6375] "%" Vector__XXX

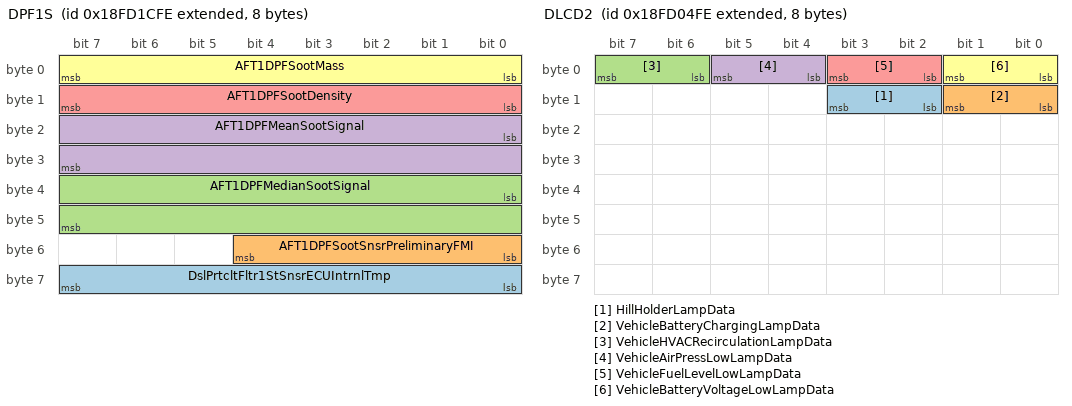
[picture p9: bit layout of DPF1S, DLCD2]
BO_ 2566724862 DPF1S: 8 Vector__XXX
 SG_ DslPrtcltFltr1StSnsrECUIntrnlTmp : 56|8@1+ (1,-40) [-40|210] "°C" Vector__XXX
 SG_ AFT1DPFSootSnsrPreliminaryFMI : 48|5@1+ (1,0) [0|31] "" Vector__XXX
 SG_ AFT1DPFMedianSootSignal : 32|16@1+ (0.0025,0) [0|160.6375] "%" Vector__XXX
 SG_ AFT1DPFMeanSootSignal : 16|16@1+ (0.0025,0) [0|160.6375] "%" Vector__XXX
 SG_ AFT1DPFSootDensity : 8|8@1+ (0.08,0) [0|20] "g/L" Vector__XXX
 SG_ AFT1DPFSootMass : 0|8@1+ (4,0) [0|1000] "g" Vector__XXX

BO_ 2566718718 DLCD2: 8 Vector__XXX
 SG_ HillHolderLampData : 10|2@1+ (1,0) [0|3] "" Vector__XXX
 SG_ VehicleBatteryChargingLampData : 8|2@1+ (1,0) [0|3] "" Vector__XXX
 SG_ VehicleHVACRecirculationLampData : 6|2@1+ (1,0) [0|3] "" Vector__XXX
 SG_ VehicleAirPressLowLampData : 4|2@1+ (1,0) [0|3] "" Vector__XXX
 SG_ VehicleFuelLevelLowLampData : 2|2@1+ (1,0) [0|3] "" Vector__XXX
 SG_ VehicleBatteryVoltageLowLampData : 0|2@1+ (1,0) [0|3] "" Vector__XXX

BO_ 2566718974 DLCD1: 8 Vector__XXX
 SG_ VhclAcclerationRateLimitLampData : 34|2@1+ (1,0) [0|3] "" Vector__XXX
 SG_ EngSpeedVeryHighLampData : 32|2@1+ (1,0) [0|3] "" Vector__XXX
 SG_ EngSpeedHighLampData : 30|2@1+ (1,0) [0|3] "" Vector__XXX
 SG_ EngCtrlMdule3ReadyForUseLampData : 28|2@1+ (1,0) [0|3] "" Vector__XXX
 SG_ EngCtrlMdule2ReadyForUseLampData : 26|2@1+ (1,0) [0|3] "" Vector__XXX
 SG_ EngCtrlMdule1ReadyForUseLampData : 24|2@1+ (1,0) [0|3] "" Vector__XXX
 SG_ EngWaitToStartLampData : 62|2@1+ (1,0) [0|3] "" Vector__XXX
 SG_ EngFuelFilterRestrictedLampData : 22|2@1+ (1,0) [0|3] "" Vector__XXX
 SG_ EngAirFilterRestrictionLampData : 20|2@1+ (1,0) [0|3] "" Vector__XXX
 SG_ EngIdleManagementActiveLampData : 18|2@1+ (1,0) [0|3] "" Vector__XXX
 SG_ EngCoolantLevelLowLampData : 16|2@1+ (1,0) [0|3] "" Vector__XXX
 SG_ EngCoolantTempHighLampData : 14|2@1+ (1,0) [0|3] "" Vector__XXX
 SG_ EngOilPressLowLampData : 12|2@1+ (1,0) [0|3] "" Vector__XXX
 SG_ CmprssnBrkEnblSwtchIndctrLmpData : 10|2@1+ (1,0) [0|3] "" Vector__XXX
 SG_ EngBrakeActiveLampData : 8|2@1+ (1,0) [0|3] "" Vector__XXX
 SG_ OBDMalfunctionIndicatorLampData : 6|2@1+ (1,0) [0|3] "" Vector__XXX
 SG_ EngRedStopLampData : 4|2@1+ (1,0) [0|3] "" Vector__XXX
 SG_ EngAmberWarningLampData : 2|2@1+ (1,0) [0|3] "" Vector__XXX
 SG_ EngProtectLampData : 0|2@1+ (1,0) [0|3] "" Vector__XXX

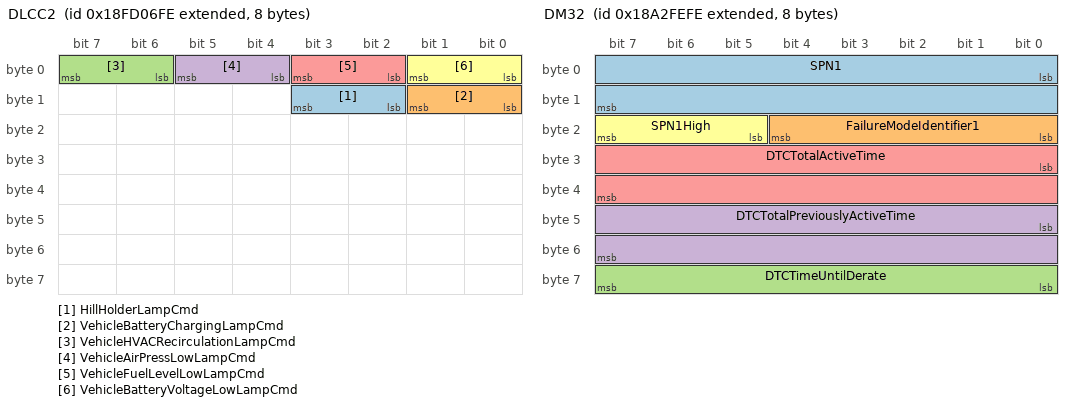
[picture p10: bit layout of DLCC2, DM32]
BO_ 2566719230 DLCC2: 8 Vector__XXX
 SG_ HillHolderLampCmd : 10|2@1+ (1,0) [0|3] "" Vector__XXX
 SG_ VehicleBatteryChargingLampCmd : 8|2@1+ (1,0) [0|3] "" Vector__XXX
 SG_ VehicleHVACRecirculationLampCmd : 6|2@1+ (1,0) [0|3] "" Vector__XXX
 SG_ VehicleAirPressLowLampCmd : 4|2@1+ (1,0) [0|3] "" Vector__XXX
 SG_ VehicleFuelLevelLowLampCmd : 2|2@1+ (1,0) [0|3] "" Vector__XXX
 SG_ VehicleBatteryVoltageLowLampCmd : 0|2@1+ (1,0) [0|3] "" Vector__XXX

BO_ 2560818942 DM32: 8 Vector__XXX
 SG_ SPN1 : 0|16@1+ (1,0) [0|65536] "" Vector__XXX
 SG_ FailureModeIdentifier1 : 16|5@1+ (1,0) [0|0] "" Vector__XXX
 SG_ DTCTimeUntilDerate : 56|8@1+ (0.25,0) [0|62.5] "hr" Vector__XXX
 SG_ DTCTotalPreviouslyActiveTime : 40|16@1+ (0.2,0) [0|12851] "hr" Vector__XXX
 SG_ DTCTotalActiveTime : 24|16@1+ (0.2,0) [0|12851] "hr" Vector__XXX
 SG_ SPN1High : 21|3@1+ (1,0) [0|7] "" Vector__XXX

CM_ BO_ 2566722302 "Magnet Status Information 1
This message carries data related to the status of the magnetic material handling system, possibly including the generator that provides power to the magnet.";
CM_ SG_ 2566722302 GeneratorDutyCycleExceededStatus "The status of the duty cycle of the generator usage, indicating if the generator has been on for too much time within a defined time window.  The duty cycle is the ratio of the time the generator is on and the time the generator is off within a time ...";
CM_ SG_ 2566722302 VoltageMonitorActiveStatus "Status of Voltage Monitor Relay. When it is activated, the Generator Voltage Monitor is connected to the generator output line so that the generator output voltage range could be monitored.
00 = Monitor is Off
01 = Monitor is On
10 = Error
11 = ...";
CM_ SG_ 2566722302 GensetEnableActiveStatus "Status of the Genset Enable Relay that enables or disables the Genset.

00 = Not Enabled
01 = Enabled
10 = Error
11 = Not Avaialble";
CM_ SG_ 2566722302 ReverseCurrentRangeSetting "The operator setting for the Reverse Current. The setting defines the maximum reverse current. The actual current limits are specific to the application.
00000 = 1
00001 = 2
00010 = 3
00011 = 4
00100 = 5
00101 = 6
00110 = 7
00111 = 8
01000 ...";
CM_ SG_ 2566722302 GensetSoftstartActiveStatus "The Genset Softstart Active Status refers to the status of the genset softstart relay. The moment the Genset System is started, this relay is activated. As a result, the hydraulic power is hold on for a short period of time, and this relay will be ...";
CM_ SG_ 2566722302 Grapple_MagnetSelectionSwitch "This is a switch that can be used to select either the Grapple or Magnet function of the material handler machine.

00 = Grapple Selected
01 = Magnet Selected
10 = Error
11 = Not Available";
CM_ SG_ 2566722302 GnstSystmOtputVoltageRangeStatus "Status of generator voltage in or out of desired operating range.

00 = Out of Range 
01 = In Range
10 = Error
11 = Not Available";
CM_ SG_ 2566722302 GeneratorOverheatStatus "The Status of Generator being Overheated.

00 = Not Overheat
01 = Overheat
10 = Error
11 = Not Available";
CM_ BO_ 2566722558 "Magnet System Configuration Information
This message carries data related to the configuration of the magnetic material handling system, possibly including the generator that provides power to the magnet.";
CM_ SG_ 2566722558 MagnetRatedPower "The rated power that the magnet can accept during material holding operations.  Note that the magnet may experience more power over short intervals, such as during initial activation of the magnet circuit to pick up material.";
CM_ SG_ 2566722558 MagnetBoostTime "The duration of time after the activation of the magnet circuit that a relatively high current is sent to the magnet for material pick up operations. This time is called boost time. After the boost time expires, a lower operation current is sent to ...";
CM_ BO_ 2560032510 "Low Voltage Disconnect Set Operating Mode
Low Voltage Disconnect (LVD) Set Operating Mode is sent to the LVD to either manuallly override the normal LVD function and force the outputs to be disconnected or connected, or to put the LVD back into ...";
CM_ SG_ 2560032510 LwVltgDscnnctDsiredOperatingMode "Desired Operating Mode of the LVD.  Used to issue a J1939 request to the LVD to change modes.

0000 - Automatic
0001-0011 - Reserved
0100 - Manual Disconnect
0101 - Manual Connect
0110-1110 - Reserved
1111 - No change";
CM_ BO_ 2566717950 "Low Voltage Disconnect  Status
Status of the Low-Voltage Disconnect (LVD) device.";
CM_ SG_ 2566717950 LowVoltageDisconnectTemp "Internal temperature of the LVD.";
CM_ SG_ 2566717950 LwVltgeDisconnectVoutOutputState "State of the Vout Output from the LVD.  Vout is the LVD's main internal, controllable, high-current output.  If the LVD supports prioritization, this circuit will be the last to disconnect and the first to reconnect.
0000 - Output off or ...";
CM_ SG_ 2566717950 LowVoltageDisconnectOutput1State "State of the Output #1 from the LVD.  Output #1 controls an external load or relay.  This external load could be independent of the main output, and may apply to an application specific circuit or zone.  If the LVD supports prioritization, this ...";
CM_ SG_ 2566717950 LowVoltageDisconnectOutput2State "State of the Output #2 from the LVD.  Output #2 controls an external load or relay.  This external load could be independent of the main output, and may apply to an application specific circuit or zone.  If the LVD supports prioritization, this ...";
CM_ SG_ 2566717950 LowVoltageDisconnectOutput3State "State of the Output #3 from the LVD.  Output #3 controls an external load or relay.  This external load could be independent of the main output, and may apply to an application specific circuit or zone.  If the LVD supports prioritization, this ...";
CM_ SG_ 2566717950 LwVltgDscnnctCrrentOperatingMode "Current operating mode of the LVD.  The current mode is dependent on the state of the Manual Disconnect/Connect hardwired inputs and on the most-recent received LVD Set Desired Operating Mode message.  The hardwired inputs have priority over the LVD ...";
CM_ SG_ 2566717950 LwVltgDscnnectManualConnectState "State of the Manual Connect hardwired input to the LVD.  Manual Connect is used to override the LVD's normal activlty and connect all of the LVD outputs.  Manual Connect has priority over the Manual Dicsonnect hardwired input and all LVD Set ...";
CM_ SG_ 2566717950 LwVltgDscnnctMnalDisconnectState "State of the Manual Disconnect hardwired input to the LVD.  Manual Disconnect is used to override the LVD's normal activlty and dicconnect all of the LVD outputs.  Manual Disconnect is lower in priority than the Manual Connect hardwired input, but ...";
CM_ BO_ 2499604222 "Land Leveling System Reference Elevation Data
This PGN will be used to communicate the reference elvation information for the land leveling system.  It will communicate the left and right blade offset data and left and right elevation deviation ...";
CM_ SG_ 2499604222 BldReferenceElevationOffsetRight "Indicates the blade's right elevation offset with respect to the reference elevation.  An offset of 0 m represents no offset from the reference elevation.  A positive number indicates that the offset elevation is above the original reference ...";
CM_ SG_ 2499604222 BldeReferenceElevationOffsetLeft "Indicates the blade's left elevation offset with respect to the reference elevation.  An offset of 0 m represents no offset from the reference elevation.  A positive number indicates that the offset elevation is above the original reference ...";
CM_ SG_ 2499604222 BladeElevationDeviationRight "Indicate the blade's right elevation deviation with respect to the reference elevation.  Serves as an indication of how far the left end of the blade is above or below grade.  A positive number indicates that the blade is above the desired grade.  A ...";
CM_ SG_ 2499604222 BladeElevationDeviationLeft "Indicate the blade's left elevation deviation with respect to the reference elevation.  Serves as an indication of how far the left end of the blade is above or below grade.  A positive number indicates that the blade is above the desired grade.  A ...";
CM_ BO_ 2358902526 "Joystick Lamp Command Message
Used to transfer joystick lamp command informations which are used to switch on/off/blinking joystick 1...3 lamps 1...10.";
CM_ SG_ 2358902526 Joystick3Lamp10Cmd "Tells joystick 3 to switch on/off/blinking lamp 10.

00 - Off
01 - On
10 - Blinking
11 - Don't care / Take no action";
CM_ SG_ 2358902526 Joystick3Lamp9Cmd "Tells joystick 3 to switch on/off/blinking lamp 9.

00 - Off
01 - On
10 - Blinking
11 - Don't care / Take no action";
CM_ SG_ 2358902526 Joystick3Lamp8Cmd "Tells joystick 3 to switch on/off/blinking lamp 8.

00 - Off
01 - On
10 - Blinking
11 - Don't care / Take no action";
CM_ SG_ 2358902526 Joystick3Lamp7Cmd "Tells joystick 3 to switch on/off/blinking lamp 7.

00 - Off
01 - On
10 - Blinking
11 - Don't care / Take no action";
CM_ SG_ 2358902526 Joystick3Lamp6Cmd "Tells joystick 3 to switch on/off/blinking lamp 6.

00 - Off
01 - On
10 - Blinking
11 - Don't care / Take no action";
CM_ SG_ 2358902526 Joystick3Lamp5Cmd "Tells joystick 3 to switch on/off/blinking lamp 5.

00 - Off
01 - On
10 - Blinking
11 - Don't care / Take no action";
CM_ SG_ 2358902526 Joystick3Lamp4Cmd "Tells joystick 3 to switch on/off/blinking lamp 4.

00 - Off
01 - On
10 - Blinking
11 - Don't care / Take no action";
CM_ SG_ 2358902526 Joystick3Lamp3Cmd "Tells joystick 3 to switch on/off/blinking lamp 3.

00 - Off
01 - On
10 - Blinking
11 - Don't care / Take no action";
CM_ SG_ 2358902526 Joystick3Lamp2Cmd "Tells joystick 3 to switch on/off/blinking lamp 2.

00 - Off
01 - On
10 - Blinking
11 - Don't care / Take no action";
CM_ SG_ 2358902526 Joystick3Lamp1Cmd "Tells joystick 3 to switch on/off/blinking lamp 1.

00 - Off
01 - On
10 - Blinking
11 - Don't care / Take no action";
CM_ SG_ 2358902526 Joystick2Lamp10Cmd "Tells joystick 2 to switch on/off/blinking lamp 10.

00 - Off
01 - On
10 - Blinking
11 - Don't care / Take no action";
CM_ SG_ 2358902526 Joystick2Lamp9Cmd "Tells joystick 2 to switch on/off/blinking lamp 9.

00 - Off
01 - On
10 - Blinking
11 - Don't care / Take no action";
CM_ SG_ 2358902526 Joystick2Lamp8Cmd "Tells joystick 2 to switch on/off/blinking lamp 8.

00 - Off
01 - On
10 - Blinking
11 - Don't care / Take no action";
CM_ SG_ 2358902526 Joystick2Lamp7Cmd "Tells joystick 2 to switch on/off/blinking lamp 7.

00 - Off
01 - On
10 - Blinking
11 - Don't care / Take no action";
CM_ SG_ 2358902526 Joystick2Lamp6Cmd "Tells joystick 2 to switch on/off/blinking lamp 6.

00 - Off
01 - On
10 - Blinking
11 - Don't care / Take no action";
CM_ SG_ 2358902526 Joystick2Lamp5Cmd "Tells joystick 2 to switch on/off/blinking lamp 5.

00 - Off
01 - On
10 - Blinking
11 - Don't care / Take no action";
CM_ SG_ 2358902526 Joystick2Lamp4Cmd "Tells joystick 2 to switch on/off/blinking lamp 4.

00 - Off
01 - On
10 - Blinking
11 - Don't care / Take no action";
CM_ SG_ 2358902526 Joystick2Lamp3Cmd "Tells joystick 2 to switch on/off/blinking lamp 3.

00 - Off
01 - On
10 - Blinking
11 - Don't care / Take no action";
CM_ SG_ 2358902526 Joystick2Lamp2Cmd "Tells joystick 2 to switch on/off/blinking lamp 2.

00 - Off
01 - On
10 - Blinking
11 - Don't care / Take no action";
CM_ SG_ 2358902526 Joystick2Lamp1Cmd "Tells joystick 2 to switch on/off/blinking lamp 1.

00 - Off
01 - On
10 - Blinking
11 - Don't care / Take no action";
CM_ SG_ 2358902526 Joystick1Lamp10Cmd "Tells joystick 1 to switch on/off/blinking lamp 10.

00 - Off
01 - On
10 - Blinking
11 - Don't care / Take no action";
CM_ SG_ 2358902526 Joystick1Lamp9Cmd "Tells joystick 1 to switch on/off/blinking lamp 9.

00 - Off
01 - On
10 - Blinking
11 - Don't care / Take no action";
CM_ SG_ 2358902526 Joystick1Lamp8Cmd "Tells joystick 1 to switch on/off/blinking lamp 8.

00 - Off
01 - On
10 - Blinking
11 - Don't care / Take no action";
CM_ SG_ 2358902526 Joystick1Lamp7Cmd "Tells joystick 1 to switch on/off/blinking lamp 7.

00 - Off
01 - On
10 - Blinking
11 - Don't care / Take no action";
CM_ SG_ 2358902526 Joystick1Lamp6Cmd "Tells joystick 1 to switch on/off/blinking lamp 6.

00 - Off
01 - On
10 - Blinking
11 - Don't care / Take no action";
CM_ SG_ 2358902526 Joystick1Lamp5Cmd "Tells joystick 1 to switch on/off/blinking lamp 5.

00 - Off
01 - On
10 - Blinking
11 - Don't care / Take no action";
CM_ SG_ 2358902526 Joystick1Lamp4Cmd "Tells joystick 1 to switch on/off/blinking lamp 4.

00 - Off
01 - On
10 - Blinking
11 - Don't care / Take no action";
CM_ SG_ 2358902526 Joystick1Lamp3Cmd "Tells joystick 1 to switch on/off/blinking lamp 3.

00 - Off
01 - On
10 - Blinking
11 - Don't care / Take no action";
CM_ SG_ 2358902526 Joystick1Lamp2Cmd "Tells joystick 1 to switch on/off/blinking lamp 2.

00 - Off
01 - On
10 - Blinking
11 - Don't care / Take no action";
CM_ SG_ 2358902526 Joystick1Lamp1Cmd "Tells joystick 1 to switch on/off/blinking lamp 1.

00 - Off
01 - On
10 - Blinking
11 - Don't care / Take no action";
CM_ BO_ 2566711550 "Intake Valve Actuation Control
Contains information about the intake valve actuation system control.";
CM_ SG_ 2566711550 IntkVlvActtnSystmOlPrss2SlndCtrl "Indicates the current command to the solenoid that controls the intake valve actuation system oil pressure 2 valve. This valve opens or closes a connection from the intake valve actuation oil rail to tank.
00 off
01 on
10 reserved for SAE ...";
CM_ SG_ 2566711550 IntkVlvActtnSystmOlPrss1SlndCtrl "Indicates the current command to the solenoid that controls the intake valve actuation system oil pressure 1 valve. This valve opens or closes a connection from the intake valve actuation oil rail to tank.
00 off
01 on
10 reserved for SAE ...";
CM_ BO_ 2566719998 "High Resolution Fuel Consumption (Liquid)
Engine fuel consumption accumulators.  See PGN 65257 for alternate resolution.";
CM_ SG_ 2566719998 HighResolutionEngTotalFuelUsed "Accumulated amount of fuel used during vehicle operation.  High resolution used for calculations and fleet management systems.  See SPN 250 for alternate resolution.";
CM_ SG_ 2566719998 HighResolutionEngTripFuel "Fuel consumed during all or part of a journey.   High resolution used for calculations and fleet management systems.  See SPN 182 for alternate resolution.";
CM_ BO_ 2565877502 "Engine Turbocharger Control
This PGN contains the Engine Turbocharger Wastegate Actuator 1 & 2 control, Exhaust Back Pressure Regulator and Blowoff Actuator commands.";
CM_ SG_ 2565877502 EngTrbCmprssrBlowoffActuator1Cmd "The command to blow off actuator 1, normalized to percent, where 0% nominally represents fully closed (No Flow) and 100% represents fully open (Max Flow). The purpose of Blow-off value is similar to that of Compressor bypass valve, however the ...";
CM_ SG_ 2565877502 EngExhstBckPressRegulatorCtrlCmd "The control command to the Engine Exhaust Pressure Regulator, normalized to percent.  100 percent means the regulator is fully closed, providing the maximum restriction to exhaust gas flow from the engine.  Zero percent means the regulator is fully ...";
CM_ SG_ 2565877502 EngTurboWastegateActuator2Cmd "The command to a Turbocharger Wastegate actuator 2, normalized to percent, where 0% nominally represents fully closed (No Flow) and 100% represents fully open (Max Flow).";
CM_ SG_ 2565877502 EngTurboWastegateActuator1Cmd "The command to a Turbocharger Wastegate actuator 1, normalized to percent, where 0% nominally represents fully closed (No Flow) and 100% represents fully open (Max Flow).
0xFB00 - 0xFB64 is sent to calibrate to a specific position.  The LSB ...";
CM_ BO_ 2566713854 "Engine Turbocharger Wastegate Actuator and Exhaust Back Pressure Regulator Information
This PGN will be used to transmit  the Engine Turbocharger Wastegate and Exhaust Back Pressure Regulator Information.";
CM_ SG_ 2566713854 EngExhaustBackPressActuator1Temp "Temperature of the Engine Exhaust Pressure Actuator 1 drive circuitry.  Temperature excursions may affect the torque output.";
CM_ SG_ 2566713854 EngExhstBckPrssActtor1DesiredPos "The requested position of the Engine Exhaust Pressure Actuator 1 by the engine ECU, where 0% represents fully closed and 100% represents fully open.

This is the position that the device is attempting to achieve.";
CM_ SG_ 2566713854 EngTurboWastegateActuator1Temp "Temperature of the Engine Turbocharger Wastegate Actuator 1 drive circuitry.  Temperature excursions may affect the torque output.";
CM_ SG_ 2566713854 EngExhstBckPrssRgltrCtrlOprtnStt "Used to identify the status of Engine Exhaust Pressure Regulator.
0000 - Normal
0001 - Alarm (fully operational but needs service)
0010 - Alarm High Severity (functional but transient performance may be reduced)
0011 - Derate Active (torque ...";
CM_ SG_ 2566713854 EngExhstBckPrssRglatorTempStatus "Used to identify the status of the Engine Exhaust Pressure Regulator (EPR) drive circuitry temperature. Temperature excursions may affect the torque output.
000 - High most severe
001 - High Least severe
010 - In Range
011 - Low Least severe
 ...";
CM_ SG_ 2566713854 EngExhstBckPrssRgltrPrlminaryFMI "Used to identify the applicable J1939-73 FMI detected in the Engine Exhaust Pressure Regulator (EPR) by the manufacturers software. When there is no failure, FMI 31 is transmitted. When there are multiple failures, the most severe is transmitted.";
CM_ SG_ 2566713854 EngExhaustBackPressRegulatorPos "The position of the Exhaust Pressure Regulator (EPR) expressed as a percentage of full travel.  One hundred percent means the regulator is fully closed, providing the maximum restriction to exhaust gas flow from the engine.  Zero percent means the ...";
CM_ SG_ 2566713854 EngTrbWstgtActtr2OperationStatus "Used to identify the status of Engine Turbocharger Wastegate Actuator 2.
0000 - Normal
0001 - Alarm (fully operational but needs service)
0010 - Alarm High Severity (functional but transient performance may be reduced)
0011 - Derate Active ...";
CM_ SG_ 2566713854 EngTrbWstgtActtr1OperationStatus "Used to identify the status of Engine Turbocharger Wastegate Actuator 1.
0000 - Normal
0001 - Alarm (fully operational but needs service)
0010 - Alarm High Severity (functional but transient performance may be reduced)
0011 - Derate Active ...";
CM_ SG_ 2566713854 EngTrbWstgateActuator2TempStatus "Used to identify the status of the Engine Turbocharger Wastegate Actuator 2 drive circuitry temperature.  Temperature excursions may affect the torque output.
000 - High most severe
001 - High Least severe
010 - In Range
011 - Low Least severe
 ...";
CM_ SG_ 2566713854 EngTrbWstgtActtor2PreliminaryFMI "Used to identify the applicable J1939-73 FMI detected in the Engine Turbocharger Wastegate Actuator 2 by the manufacturers software. When there is no failure FMI 31 is transmitted. When there is multiple failures, the most severe is transmitted";
CM_ BO_ 2566714366 "Engine Turbocharger Compressor Bypass Information
This PGN will contain the Engine Turbocharger Compressor Bypass information";
CM_ SG_ 2566714366 EngTrbCmprssrBypassActuator2Temp "Temperature of the Engine Turbocharger Compressor Bypass Actuator 2 drive circuitry.    Temperature excursions may affect the torque output.";
CM_ SG_ 2566714366 EngTrbCmprssrBypassActuator1Temp "Temperature of the Engine Turbocharger Compressor Bypass Actuator 1 drive circuitry.    Temperature excursions may affect the torque output.";
CM_ SG_ 2566714366 EngTrbCmprssrBypssActtr2OprtnStt "Used to identify the status of Engine Turbocharger Compressor Bypass Actuator 2.
0000 - Normal
0001 - Alarm (fully operational but needs service)
0010 - Alarm High Severity (functional but transient performance may be reduced)
0011 - Derate ...";
CM_ SG_ 2566714366 EngTrbCmprssrBypssActtr1OprtnStt "Used to identify the status of Engine Turbocharger Compressor Bypass Actuator 1.
0000 - Normal
0001 - Alarm (fully operational but needs service)
0010 - Alarm High Severity (functional but transient performance may be reduced)
0011 - Derate ...";
CM_ SG_ 2566714366 EngTrbCmprssrBypssActtr2TmpSttus "Used to identify the status of the Engine Turbocharger Compresssor Bypass Actuator 2 drive circuitry temperature.  Temperature excursions may affect the torque output.
000 - High most severe
001 - High Least severe
010 - In Range
011 - Low Least ...";
CM_ SG_ 2566714366 EngTrbCmprssrBypssActtr2PrlmnryF "Used to identify the applicable J1939-73 FMI detected in the Engine Turbocharger Compressor Bypass Actuator 1 by the manufacturers software. When there is no failure FMI 31 is transmitted. When there is multiple failures, the most severe is ...";
CM_ SG_ 2566714366 EngDsrdTrbCmprssrBypssActtor2Pos "The desired position of the Engine Turbocharger Compressor Bypass actuator 2 by the engine ECU, where 0% represents bypass fully closed and 100% represents bypass fully open.

This is the position that the device is attempting to achieve.";
CM_ SG_ 2566714366 EngTrbCmprssorBypassActuator2Pos "Measures the position of the turbocharger compressor bypass actuator 2, where 0% represents bypass fully closed and 100% represents bypass fully open. Typically, the compressor bypass is used to lower the compressor outlet pressure and/or intake ...";
CM_ BO_ 2566714110 "Engine Fuel/Throttle Valve Information 1
This PGN will be used to transmit the Feedback information from the Engine Throttle and Fuel Actuator.";
CM_ SG_ 2566714110 EngFuelValve2OperationStatus "Used to identify the status of Engine Fuel Valve 2.
0000 - Normal
0001 - Alarm (fully operational but needs service)
0010 - Alarm High Severity (functional but transient performance may be reduced)
0011 - Derate Active (torque output reduced due ...";
CM_ SG_ 2566714110 EngFuelValve1OperationStatus "Used to identify the status of Engine Fuel Valve 1.
0000 - Normal
0001 - Alarm (fully operational but needs service)
0010 - Alarm High Severity (functional but transient performance may be reduced)
0011 - Derate Active (torque output reduced due ...";
CM_ SG_ 2566714110 EngThrottleValve2OperationStatus "Used to identify the status of engine throttle valve 2 (SPN 3673).
0000 - Normal
0001 - Alarm (fully operational but needs service)
0010 - Alarm High Severity (functional but transient performance may be reduced)
0011 - Derate Active (torque ...";
CM_ SG_ 2566714110 EngThrottleValve1OperationStatus "Used to identify the status of engine throttle valve 1 (SPN 51).
0000 - Normal
0001 - Alarm (fully operational but needs service)
0010 - Alarm High Severity (functional but transient performance may be reduced)
0011 - Derate Active (torque ...";
CM_ SG_ 2566714110 EngFuelValve2TempStatus "Used to identify the status of the Engine Fuel valve 2 drive circuitry temperature.  Temperature excursions may affect the torque output.
000 - High most severe
001 - High Least severe
010 - In Range
011 - Low Least severe
100 - Low Most severe
 ...";
CM_ SG_ 2566714110 EngFuelValve2PreliminaryFMI "Used to identify the applicable J1939-73 FMI detected in the Engine Fuel Valve 2 by the manufacturers software. When there is no failure FMI 31 is transmitted. When there is multiple failures, the most severe is transmitted.";
CM_ SG_ 2566714110 EngFuelValve1TempStatus "Used to identify the status of the Engine Fuel valve 1 drive circuitry temperature.  Temperature excursions may affect the torque output.
000 - High Most severe
001 - High Least severe
010 - In Range
011 - Low Least severe
100 - Low Most severe
 ...";
CM_ SG_ 2566714110 EngFuelValve1PreliminaryFMI "Used to identify the applicable J1939-73 FMI detected in the Engine Fuel Valve 1 by the manufacturers software. When there is no failure FMI 31 is transmitted. When there is multiple failures, the most severe is transmitted.";
CM_ SG_ 2566714110 EngThrottleValve2TempStatus "Used to identify the status of the Engine throttle valve 2 (SPN 3673) drive circuitry temperature.  Temperature excursions may affect the torque output.
000 - High Most severe
001 - High Least severe
010 - In Range
011 - Low Least severe
100 - ...";
CM_ SG_ 2566714110 EngThrottleValve2PreliminaryFMI "Used to identify the applicable J1939-73 FMI detected in the engine throttle valve 2 (SPN 3673) by the manufacturers software. When there is no failure FMI 31 is transmitted. When there is multiple failures, the most severe is transmitted.";
CM_ SG_ 2566714110 EngDesiredThrottleValve2Pos "The desired position of the engine throttle valve 2 (SPN 3673) that is regulating the fluid, usually air/fuel mixture to the engine as commanded by the Engine Control Unit.  0% represents no supply and 100% is full supply.
This is the position that ...";
CM_ SG_ 2566714110 EngThrottleValve1TempStatus "Used to identify the status of the engine throttle valve 1 (SPN 51) drive circuitry temperature.  Temperature excursions may affect the torque output.
000 - High most severe
001 - High Least severe
010 - In Range
011 - Low Least severe
100 - ...";
CM_ SG_ 2566714110 EngThrottleValve1PreliminaryFMI "Used to identify the applicable J1939-73 FMI detected in the engine throttle valve 1 (SPN 51) by the manufacturers software. When there is no failure FMI 31 is transmitted. When there is multiple failures, the most severe is transmitted.";
CM_ SG_ 2566714110 EngDesiredThrottleValve1Pos "The desired position of the Throttle valve 1 (SPN 51) that is regulating the fluid, usually air/fuel mixture to the engine as commanded by the Engine Control unit.  0% represents no supply and 100% is full supply.
This is the position that the ...";
CM_ BO_ 2566717438 "Engine Temperature 5
Engine related parameters";
CM_ SG_ 2566717438 EngExhstGsRcrcltn2MxerIntakeTemp "The temperature of the EGR gas entering the intake of EGR2 system mixer.";
CM_ SG_ 2566717438 EngExhaustGasRecirculation2Temp "Temperature of Recirculated Exhaust Gas of EGR2";
CM_ BO_ 2633828606 "Engine oil message
Engine oil related parameters";
CM_ SG_ 2633828606 EngOilTemp3 "Temperature of the engine lubricant.

Note:  If there is only one engine oil temperature measurement, SPN 175 should be used. 

See also SPNs 175 and 1135 for additional engine oil temperature measurements.";
CM_ SG_ 2633828606 EngOilRelativeDielectricity "Engine oil relative dielectricity used to describe the engine oil quality.";
CM_ SG_ 2633828606 EngOilDensity "Density of the engine oil";
CM_ SG_ 2633828606 EngOilViscosity "Dynamic viscosity of the engine oil";
CM_ BO_ 2499607550 "Engine Manifold Actuator Position
Engine manifold actuator position parameters";
CM_ SG_ 2499607550 EngExhstMnfldBnk2FlwBlncVlvActtr "Actual percentage of maximum Engine Manifold Bank 2 Balance valve opening. 0% means valve is closed. 100% means maximum valve opening (full gas flow).";
CM_ SG_ 2499607550 EngExhstMnfldBnk1FlwBlncVlvActtr "Actual percentage of maximum Engine Exhaust Manifold Bank 1 Balance valve opening. 0% means valve is closed. 100% means maximum valve opening (full gas flow).";
CM_ BO_ 2633825534 "Engine Manifold Actuator Control
Engine manifold actuator control parameters.";
CM_ SG_ 2633825534 EngExhstMnfldBnk2FlwBlncVlvActtr "Commanded percentage of maximum Engine Ehaust Manifold Bank 2 Balance valve opening. 0% means valve is closed. 100% means maximum valve opening (full gas flow).";
CM_ SG_ 2633825534 EngExhstMnfldBnk1FlwBlncVlvActtr "Commanded percentage of maximum Engine Exhaust Manifold Bank 1 Balance valve opening. 0% means valve is closed. 100% means maximum valve opening (full gas flow).";
CM_ BO_ 2365400574 "Extended Joystick Message 9
Used to transfer information about the measured status of three additional axes of a joystick and switches of the joystick grip or handle.  The joystick axial motion information is available in the Basic Joystick ...";
CM_ SG_ 2365400574 Joystick9Button13PressedStatus "Reports when the joystick button has been pressed.

00 Button not pressed
01 Button pressed
10 Error Indicator
11 Not Available";
CM_ SG_ 2365400574 Joystick9Button14PressedStatus "Reports when the joystick button has been pressed.

00 Button not pressed
01 Button pressed
10 Error Indicator
11 Not Available";
CM_ SG_ 2365400574 Joystick9Button15PressedStatus "Reports when the joystick button has been pressed.

00 Button not pressed
01 Button pressed
10 Error Indicator
11 Not Available";
CM_ SG_ 2365400574 Joystick9Button16PressedStatus "Reports when the joystick button has been pressed.

00 Button not pressed
01 Button pressed
10 Error Indicator
11 Not Available";
CM_ SG_ 2365400574 Jystick9GripXAxisDetentPosStatus "Reports when the current joystick grip position is in the detent position for that axis of travel.

00 Not in the Detent Position
01 In the Detent Position
10 Error Indicator
11 Not Available";
CM_ SG_ 2365400574 Jystick9GripYAxisDetentPosStatus "Reports when the current joystick grip position is in the detent position for that axis of travel.

00 Not in the Detent Position
01 In the Detent Position
10 Error Indicator
11 Not Available";
CM_ SG_ 2365400574 Jystick9ThetaAxisDetentPosStatus "Reports when the current joystick position is in the detent position for that axis of travel.

00 Not in the Detent Position
01 In the Detent Position
10 Error Indicator
11 Not Available";
CM_ SG_ 2365400574 Joystick9ThetaAxisPos "The position of the joystick in the relative motion of travel from the neutral position.  Position value of 0 is Neutral and position value 1000 (100%) is the end of linear zone.  Value of 1022 indicates an error has occurred.";
CM_ SG_ 2365400574 Jystck9ThtAxsClckwsPstvPosStatus "Reports when the current joystick position is on the positive travel side (forward, right, clockwise, up) relative to the neutral position for that axis of travel.
00 Not on Positive side of Neutral
01 On positive side of Neutral
10 Error ...";
CM_ SG_ 2365400574 Jystck9ThtAxsCntrClckwsNgtvPsStt "Reports when the current joystick position is on the negative travel side (back, left, counterclockwise, down) relative to the neutral position for that axis of travel.
00 Not on negative side of Neutral
01 On negative side of Neutral
10 Error ...";
CM_ SG_ 2365400574 Jystck9ThetaAxisNeutralPosStatus "Reports when the current joystick position is in the neutral position for that axis of travel.  The neutral position measurement must be determined from some mechanism other than the axis position measurement device.
00 Not in Neutral Position
01 ...";
CM_ SG_ 2365400574 Joystick9GripYAxisPos "The position of the joystick grip in the relative motion of travel from the neutral position.  Position value of 0 is Neutral and position value 1000 (100%) is the end of linear zone.  Value of 1022 indicates an error has occurred.";
CM_ SG_ 2365400574 Jystck9GrpYAxsLvrFrwrdPstvPsStts "Reports when the current joystick grip position is on the positive travel side (forward, right, clockwise, up) relative to the neutral position for that axis of travel.
00 Not on Positive side of Neutral
01 On positive side of Neutral
10 Error ...";
CM_ SG_ 2365400574 Jystck9GrpYAxsLvrBckNgtvPsStatus "Reports when the current joystick grip position is on the negative travel side (back, left, counterclockwise, down) relative to the neutral position for that axis of travel.
00 Not on negative side of Neutral
01 On negative side of Neutral
10 ...";
CM_ SG_ 2365400574 Jystck9GripYAxisNeutralPosStatus "Reports when the current joystick grip position is in the neutral position for that axis of travel.  The neutral position measurement must be determined from some mechanism other than the axis position measurement device.
00 Not in Neutral Position
 ...";
CM_ SG_ 2365400574 Joystick9GripXAxisPos "The position of the joystick grip in the relative motion of travel from the neutral position.  Position value of 0 is Neutral and position value 1000 (100%) is the end of linear zone.  Value of 1022 indicates an error has occurred.";
CM_ SG_ 2365400574 Jystck9GrpXAxsLvrRghtPstvPsSttus "Reports when the current joystick grip position is on the positive travel side (forward, right, clockwise, up) relative to the neutral position for that axis of travel.
00 Not on Positive side of Neutral
01 On positive side of Neutral
10 Error ...";
CM_ SG_ 2365400574 Jystck9GrpXAxsLvrLftNgtvPsStatus "Reports when the current joystick grip position is on the negative travel side (back, left, counterclockwise, down) relative to the neutral position for that axis of travel.
00 Not on negative side of Neutral
01 On negative side of Neutral
10 ...";
CM_ SG_ 2365400574 Jystck9GripXAxisNeutralPosStatus "Reports when the current joystick grip position is in the neutral position for that axis of travel.  The neutral position measurement must be determined from some mechanism other than the axis position measurement device.
00 Not in Neutral Position
 ...";
CM_ BO_ 2365401086 "Extended Joystick Message 8
Used to transfer information about the measured status of three additional axes of a joystick and switches of the joystick grip or handle.  The joystick axial motion information is available in the Basic Joystick ...";
CM_ SG_ 2365401086 Joystick8Button13PressedStatus "Reports when the joystick button has been pressed.

00 Button not pressed
01 Button pressed
10 Error Indicator
11 Not Available";
CM_ SG_ 2365401086 Joystick8Button14PressedStatus "Reports when the joystick button has been pressed.

00 Button not pressed
01 Button pressed
10 Error Indicator
11 Not Available";
CM_ SG_ 2365401086 Joystick8Button15PressedStatus "Reports when the joystick button has been pressed.

00 Button not pressed
01 Button pressed
10 Error Indicator
11 Not Available";
CM_ SG_ 2365401086 Joystick8Button16PressedStatus "Reports when the joystick button has been pressed.

00 Button not pressed
01 Button pressed
10 Error Indicator
11 Not Available";
CM_ SG_ 2365401086 Jystick8GripXAxisDetentPosStatus "Reports when the current joystick grip position is in the detent position for that axis of travel.

00 Not in the Detent Position
01 In the Detent Position
10 Error Indicator
11 Not Available";
CM_ SG_ 2365401086 Jystick8GripYAxisDetentPosStatus "Reports when the current joystick grip position is in the detent position for that axis of travel.

00 Not in the Detent Position
01 In the Detent Position
10 Error Indicator
11 Not Available";
CM_ SG_ 2365401086 Jystick8ThetaAxisDetentPosStatus "Reports when the current joystick position is in the detent position for that axis of travel.

00 Not in the Detent Position
01 In the Detent Position
10 Error Indicator
11 Not Available";
CM_ SG_ 2365401086 Joystick8ThetaAxisPos "The position of the joystick in the relative motion of travel from the neutral position.  Position value of 0 is Neutral and position value 1000 (100%) is the end of linear zone.  Value of 1022 indicates an error has occurred.";
CM_ SG_ 2365401086 Jystck8ThtAxsClckwsPstvPosStatus "Reports when the current joystick position is on the positive travel side (forward, right, clockwise, up) relative to the neutral position for that axis of travel.
00 Not on Positive side of Neutral
01 On positive side of Neutral
10 Error ...";
CM_ SG_ 2365401086 Jystck8ThtAxsCntrClckwsNgtvPsStt "Reports when the current joystick position is on the negative travel side (back, left, counterclockwise, down) relative to the neutral position for that axis of travel.
00 Not on negative side of Neutral
01 On negative side of Neutral
10 Error ...";
CM_ SG_ 2365401086 Jystck8ThetaAxisNeutralPosStatus "Reports when the current joystick position is in the neutral position for that axis of travel.  The neutral position measurement must be determined from some mechanism other than the axis position measurement device.
00 Not in Neutral Position
01 ...";
CM_ SG_ 2365401086 Joystick8GripYAxisPos "The position of the joystick grip in the relative motion of travel from the neutral position.  Position value of 0 is Neutral and position value 1000 (100%) is the end of linear zone.  Value of 1022 indicates an error has occurred.";
CM_ SG_ 2365401086 Jystck8GrpYAxsLvrFrwrdPstvPsStts "Reports when the current joystick grip position is on the positive travel side (forward, right, clockwise, up) relative to the neutral position for that axis of travel.
00 Not on Positive side of Neutral
01 On positive side of Neutral
10 Error ...";
CM_ SG_ 2365401086 Jystck8GrpYAxsLvrBckNgtvPsStatus "Reports when the current joystick grip position is on the negative travel side (back, left, counterclockwise, down) relative to the neutral position for that axis of travel.
00 Not on negative side of Neutral
01 On negative side of Neutral
10 ...";
CM_ SG_ 2365401086 Jystck8GripYAxisNeutralPosStatus "Reports when the current joystick grip position is in the neutral position for that axis of travel.  The neutral position measurement must be determined from some mechanism other than the axis position measurement device.
00 Not in Neutral Position
 ...";
CM_ SG_ 2365401086 Joystick8GripXAxisPos "The position of the joystick grip in the relative motion of travel from the neutral position.  Position value of 0 is Neutral and position value 1000 (100%) is the end of linear zone.  Value of 1022 indicates an error has occurred.";
CM_ SG_ 2365401086 Jystck8GrpXAxsLvrRghtPstvPsSttus "Reports when the current joystick grip position is on the positive travel side (forward, right, clockwise, up) relative to the neutral position for that axis of travel.
00 Not on Positive side of Neutral
01 On positive side of Neutral
10 Error ...";
CM_ SG_ 2365401086 Jystck8GrpXAxsLvrLftNgtvPsStatus "Reports when the current joystick grip position is on the negative travel side (back, left, counterclockwise, down) relative to the neutral position for that axis of travel.
00 Not on negative side of Neutral
01 On negative side of Neutral
10 ...";
CM_ SG_ 2365401086 Jystck8GripXAxisNeutralPosStatus "Reports when the current joystick grip position is in the neutral position for that axis of travel.  The neutral position measurement must be determined from some mechanism other than the axis position measurement device.
00 Not in Neutral Position
 ...";
CM_ BO_ 2365401598 "Extended Joystick Message 7
Used to transfer information about the measured status of three additional axes of a joystick and switches of the joystick grip or handle.  The joystick axial motion information is available in the Basic Joystick ...";
CM_ SG_ 2365401598 Joystick7Button13PressedStatus "Reports when the joystick button has been pressed.

00 Button not pressed
01 Button pressed
10 Error Indicator
11 Not Available";
CM_ SG_ 2365401598 Joystick7Button14PressedStatus "Reports when the joystick button has been pressed.

00 Button not pressed
01 Button pressed
10 Error Indicator
11 Not Available";
CM_ SG_ 2365401598 Joystick7Button15PressedStatus "Reports when the joystick button has been pressed.

00 Button not pressed
01 Button pressed
10 Error Indicator
11 Not Available";
CM_ SG_ 2365401598 Joystick7Button16PressedStatus "Reports when the joystick button has been pressed.

00 Button not pressed
01 Button pressed
10 Error Indicator
11 Not Available";
CM_ SG_ 2365401598 Jystick7GripXAxisDetentPosStatus "Reports when the current joystick grip position is in the detent position for that axis of travel.

00 Not in the Detent Position
01 In the Detent Position
10 Error Indicator
11 Not Available";
CM_ SG_ 2365401598 Jystick7GripYAxisDetentPosStatus "Reports when the current joystick grip position is in the detent position for that axis of travel.

00 Not in the Detent Position
01 In the Detent Position
10 Error Indicator
11 Not Available";
CM_ SG_ 2365401598 Jystick7ThetaAxisDetentPosStatus "Reports when the current joystick position is in the detent position for that axis of travel.

00 Not in the Detent Position
01 In the Detent Position
10 Error Indicator
11 Not Available";
CM_ SG_ 2365401598 Joystick7ThetaAxisPos "The position of the joystick in the relative motion of travel from the neutral position.  Position value of 0 is Neutral and position value 1000 (100%) is the end of linear zone.  Value of 1022 indicates an error has occurred.";
CM_ SG_ 2365401598 Jystck7ThtAxsClckwsPstvPosStatus "Reports when the current joystick position is on the positive travel side (forward, right, clockwise, up) relative to the neutral position for that axis of travel.
00 Not on Positive side of Neutral
01 On positive side of Neutral
10 Error ...";
CM_ SG_ 2365401598 Jystck7ThtAxsCntrClckwsNgtvPsStt "Reports when the current joystick position is on the negative travel side (back, left, counterclockwise, down) relative to the neutral position for that axis of travel.
00 Not on negative side of Neutral
01 On negative side of Neutral
10 Error ...";
CM_ SG_ 2365401598 Jystck7ThetaAxisNeutralPosStatus "Reports when the current joystick position is in the neutral position for that axis of travel.  The neutral position measurement must be determined from some mechanism other than the axis position measurement device.
00 Not in Neutral Position
01 ...";
CM_ SG_ 2365401598 Joystick7GripYAxisPos "The position of the joystick grip in the relative motion of travel from the neutral position.  Position value of 0 is Neutral and position value 1000 (100%) is the end of linear zone.  Value of 1022 indicates an error has occurred.";
CM_ SG_ 2365401598 Jystck7GrpYAxsLvrFrwrdPstvPsStts "Reports when the current joystick grip position is on the positive travel side (forward, right, clockwise, up) relative to the neutral position for that axis of travel.
00 Not on Positive side of Neutral
01 On positive side of Neutral
10 Error ...";
CM_ SG_ 2365401598 Jystck7GrpYAxsLvrBckNgtvPsStatus "Reports when the current joystick grip position is on the negative travel side (back, left, counterclockwise, down) relative to the neutral position for that axis of travel.
00 Not on negative side of Neutral
01 On negative side of Neutral
10 ...";
CM_ SG_ 2365401598 Jystck7GripYAxisNeutralPosStatus "Reports when the current joystick grip position is in the neutral position for that axis of travel.  The neutral position measurement must be determined from some mechanism other than the axis position measurement device.
00 Not in Neutral Position
 ...";
CM_ SG_ 2365401598 Joystick7GripXAxisPos "The position of the joystick grip in the relative motion of travel from the neutral position.  Position value of 0 is Neutral and position value 1000 (100%) is the end of linear zone.  Value of 1022 indicates an error has occurred.";
CM_ SG_ 2365401598 Jystck7GrpXAxsLvrRghtPstvPsSttus "Reports when the current joystick grip position is on the positive travel side (forward, right, clockwise, up) relative to the neutral position for that axis of travel.
00 Not on Positive side of Neutral
01 On positive side of Neutral
10 Error ...";
CM_ SG_ 2365401598 Jystck7GrpXAxsLvrLftNgtvPsStatus "Reports when the current joystick grip position is on the negative travel side (back, left, counterclockwise, down) relative to the neutral position for that axis of travel.
00 Not on negative side of Neutral
01 On negative side of Neutral
10 ...";
CM_ SG_ 2365401598 Jystck7GripXAxisNeutralPosStatus "Reports when the current joystick grip position is in the neutral position for that axis of travel.  The neutral position measurement must be determined from some mechanism other than the axis position measurement device.
00 Not in Neutral Position
 ...";
CM_ BO_ 2365402110 "Extended Joystick Message 6
Used to transfer information about the measured status of three additional axes of a joystick and switches of the joystick grip or handle.  The joystick axial motion information is available in the Basic Joystick ...";
CM_ SG_ 2365402110 Joystick6Button13PressedStatus "Reports when the joystick button has been pressed.

00 Button not pressed
01 Button pressed
10 Error Indicator
11 Not Available";
CM_ SG_ 2365402110 Joystick6Button14PressedStatus "Reports when the joystick button has been pressed.

00 Button not pressed
01 Button pressed
10 Error Indicator
11 Not Available";
CM_ SG_ 2365402110 Joystick6Button15PressedStatus "Reports when the joystick button has been pressed.

00 Button not pressed
01 Button pressed
10 Error Indicator
11 Not Available";
CM_ SG_ 2365402110 Joystick6Button16PressedStatus "Reports when the joystick button has been pressed.

00 Button not pressed
01 Button pressed
10 Error Indicator
11 Not Available";
CM_ SG_ 2365402110 Jystick6GripXAxisDetentPosStatus "Reports when the current joystick grip position is in the detent position for that axis of travel.

00 Not in the Detent Position
01 In the Detent Position
10 Error Indicator
11 Not Available";
CM_ SG_ 2365402110 Jystick6GripYAxisDetentPosStatus "Reports when the current joystick grip position is in the detent position for that axis of travel.

00 Not in the Detent Position
01 In the Detent Position
10 Error Indicator
11 Not Available";
CM_ SG_ 2365402110 Jystick6ThetaAxisDetentPosStatus "Reports when the current joystick position is in the detent position for that axis of travel.

00 Not in the Detent Position
01 In the Detent Position
10 Error Indicator
11 Not Available";
CM_ SG_ 2365402110 Joystick6ThetaAxisPos "The position of the joystick in the relative motion of travel from the neutral position.  Position value of 0 is Neutral and position value 1000 (100%) is the end of linear zone.  Value of 1022 indicates an error has occurred.";
CM_ SG_ 2365402110 Jystck6ThtAxsClckwsPstvPosStatus "Reports when the current joystick position is on the positive travel side (forward, right, clockwise, up) relative to the neutral position for that axis of travel.
00 Not on Positive side of Neutral
01 On positive side of Neutral
10 Error ...";
CM_ SG_ 2365402110 Jystck6ThtAxsCntrClckwsNgtvPsStt "Reports when the current joystick position is on the negative travel side (back, left, counterclockwise, down) relative to the neutral position for that axis of travel.
00 Not on negative side of Neutral
01 On negative side of Neutral
10 Error ...";
CM_ SG_ 2365402110 Jystck6ThetaAxisNeutralPosStatus "Reports when the current joystick position is in the neutral position for that axis of travel.  The neutral position measurement must be determined from some mechanism other than the axis position measurement device.
00 Not in Neutral Position
01 ...";
CM_ SG_ 2365402110 Joystick6GripYAxisPos "The position of the joystick grip in the relative motion of travel from the neutral position.  Position value of 0 is Neutral and position value 1000 (100%) is the end of linear zone.  Value of 1022 indicates an error has occurred.";
CM_ SG_ 2365402110 Jystck6GrpYAxsLvrFrwrdPstvPsStts "Reports when the current joystick grip position is on the positive travel side (forward, right, clockwise, up) relative to the neutral position for that axis of travel.
00 Not on Positive side of Neutral
01 On positive side of Neutral
10 Error ...";
CM_ SG_ 2365402110 Jystck6GrpYAxsLvrBckNgtvPsStatus "Reports when the current joystick grip position is on the negative travel side (back, left, counterclockwise, down) relative to the neutral position for that axis of travel.
00 Not on negative side of Neutral
01 On negative side of Neutral
10 ...";
CM_ SG_ 2365402110 Jystck6GripYAxisNeutralPosStatus "Reports when the current joystick grip position is in the neutral position for that axis of travel.  The neutral position measurement must be determined from some mechanism other than the axis position measurement device.
00 Not in Neutral Position
 ...";
CM_ SG_ 2365402110 Joystick6GripXAxisPos "The position of the joystick grip in the relative motion of travel from the neutral position.  Position value of 0 is Neutral and position value 1000 (100%) is the end of linear zone.  Value of 1022 indicates an error has occurred.";
CM_ SG_ 2365402110 Jystck6GrpXAxsLvrRghtPstvPsSttus "Reports when the current joystick grip position is on the positive travel side (forward, right, clockwise, up) relative to the neutral position for that axis of travel.
00 Not on Positive side of Neutral
01 On positive side of Neutral
10 Error ...";
CM_ SG_ 2365402110 Jystck6GrpXAxsLvrLftNgtvPsStatus "Reports when the current joystick grip position is on the negative travel side (back, left, counterclockwise, down) relative to the neutral position for that axis of travel.
00 Not on negative side of Neutral
01 On negative side of Neutral
10 ...";
CM_ SG_ 2365402110 Jystck6GripXAxisNeutralPosStatus "Reports when the current joystick grip position is in the neutral position for that axis of travel.  The neutral position measurement must be determined from some mechanism other than the axis position measurement device.
00 Not in Neutral Position
 ...";
CM_ BO_ 2365402622 "Extended Joystick Message 5
Used to transfer information about the measured status of three additional axes of a joystick and switches of the joystick grip or handle.  The joystick axial motion information is available in the Basic Joystick ...";
CM_ SG_ 2365402622 Joystick5Button13PressedStatus "Reports when the joystick button has been pressed.

00 Button not pressed
01 Button pressed
10 Error Indicator
11 Not Available";
CM_ SG_ 2365402622 Joystick5Button14PressedStatus "Reports when the joystick button has been pressed.

00 Button not pressed
01 Button pressed
10 Error Indicator
11 Not Available";
CM_ SG_ 2365402622 Joystick5Button15PressedStatus "Reports when the joystick button has been pressed.

00 Button not pressed
01 Button pressed
10 Error Indicator
11 Not Available";
CM_ SG_ 2365402622 Joystick5Button16PressedStatus "Reports when the joystick button has been pressed.

00 Button not pressed
01 Button pressed
10 Error Indicator
11 Not Available";
CM_ SG_ 2365402622 Jystick5GripXAxisDetentPosStatus "Reports when the current joystick grip position is in the detent position for that axis of travel.

00 Not in the Detent Position
01 In the Detent Position
10 Error Indicator
11 Not Available";
CM_ SG_ 2365402622 Jystick5GripYAxisDetentPosStatus "Reports when the current joystick grip position is in the detent position for that axis of travel.

00 Not in the Detent Position
01 In the Detent Position
10 Error Indicator
11 Not Available";
CM_ SG_ 2365402622 Jystick5ThetaAxisDetentPosStatus "Reports when the current joystick position is in the detent position for that axis of travel.

00 Not in the Detent Position
01 In the Detent Position
10 Error Indicator
11 Not Available";
CM_ SG_ 2365402622 Joystick5ThetaAxisPos "The position of the joystick in the relative motion of travel from the neutral position.  Position value of 0 is Neutral and position value 1000 (100%) is the end of linear zone.  Value of 1022 indicates an error has occurred.";
CM_ SG_ 2365402622 Jystck5ThtAxsClckwsPstvPosStatus "Reports when the current joystick position is on the positive travel side (forward, right, clockwise, up) relative to the neutral position for that axis of travel.
00 Not on Positive side of Neutral
01 On positive side of Neutral
10 Error ...";
CM_ SG_ 2365402622 Jystck5ThtAxsCntrClckwsNgtvPsStt "Reports when the current joystick position is on the negative travel side (back, left, counterclockwise, down) relative to the neutral position for that axis of travel.
00 Not on negative side of Neutral
01 On negative side of Neutral
10 Error ...";
CM_ SG_ 2365402622 Jystck5ThetaAxisNeutralPosStatus "Reports when the current joystick position is in the neutral position for that axis of travel.  The neutral position measurement must be determined from some mechanism other than the axis position measurement device.
00 Not in Neutral Position
01 ...";
CM_ SG_ 2365402622 Joystick5GripYAxisPos "The position of the joystick grip in the relative motion of travel from the neutral position.  Position value of 0 is Neutral and position value 1000 (100%) is the end of linear zone.  Value of 1022 indicates an error has occurred.";
CM_ SG_ 2365402622 Jystck5GrpYAxsLvrFrwrdPstvPsStts "Reports when the current joystick grip position is on the positive travel side (forward, right, clockwise, up) relative to the neutral position for that axis of travel.
00 Not on Positive side of Neutral
01 On positive side of Neutral
10 Error ...";
CM_ SG_ 2365402622 Jystck5GrpYAxsLvrBckNgtvPsStatus "Reports when the current joystick grip position is on the negative travel side (back, left, counterclockwise, down) relative to the neutral position for that axis of travel.
00 Not on negative side of Neutral
01 On negative side of Neutral
10 ...";
CM_ SG_ 2365402622 Jystck5GripYAxisNeutralPosStatus "Reports when the current joystick grip position is in the neutral position for that axis of travel.  The neutral position measurement must be determined from some mechanism other than the axis position measurement device.
00 Not in Neutral Position
 ...";
CM_ SG_ 2365402622 Joystick5GripXAxisPos "The position of the joystick grip in the relative motion of travel from the neutral position.  Position value of 0 is Neutral and position value 1000 (100%) is the end of linear zone.  Value of 1022 indicates an error has occurred.";
CM_ SG_ 2365402622 Jystck5GrpXAxsLvrRghtPstvPsSttus "Reports when the current joystick grip position is on the positive travel side (forward, right, clockwise, up) relative to the neutral position for that axis of travel.
00 Not on Positive side of Neutral
01 On positive side of Neutral
10 Error ...";
CM_ SG_ 2365402622 Jystck5GrpXAxsLvrLftNgtvPsStatus "Reports when the current joystick grip position is on the negative travel side (back, left, counterclockwise, down) relative to the neutral position for that axis of travel.
00 Not on negative side of Neutral
01 On negative side of Neutral
10 ...";
CM_ SG_ 2365402622 Jystck5GripXAxisNeutralPosStatus "Reports when the current joystick grip position is in the neutral position for that axis of travel.  The neutral position measurement must be determined from some mechanism other than the axis position measurement device.
00 Not in Neutral Position
 ...";
CM_ BO_ 2365403134 "Extended Joystick Message 4
Used to transfer information about the measured status of three additional axes of a joystick and switches of the joystick grip or handle.  The joystick axial motion information is available in the Basic Joystick ...";
CM_ SG_ 2365403134 Joystick4Button13PressedStatus "Reports when the joystick button has been pressed.

00 Button not pressed
01 Button pressed
10 Error Indicator
11 Not Available";
CM_ SG_ 2365403134 Joystick4Button14PressedStatus "Reports when the joystick button has been pressed.

00 Button not pressed
01 Button pressed
10 Error Indicator
11 Not Available";
CM_ SG_ 2365403134 Joystick4Button15PressedStatus "Reports when the joystick button has been pressed.

00 Button not pressed
01 Button pressed
10 Error Indicator
11 Not Available";
CM_ SG_ 2365403134 Joystick4Button16PressedStatus "Reports when the joystick button has been pressed.

00 Button not pressed
01 Button pressed
10 Error Indicator
11 Not Available";
CM_ SG_ 2365403134 Jystick4GripXAxisDetentPosStatus "Reports when the current joystick grip position is in the detent position for that axis of travel.

00 Not in the Detent Position
01 In the Detent Position
10 Error Indicator
11 Not Available";
CM_ SG_ 2365403134 Jystick4GripYAxisDetentPosStatus "Reports when the current joystick grip position is in the detent position for that axis of travel.

00 Not in the Detent Position
01 In the Detent Position
10 Error Indicator
11 Not Available";
CM_ SG_ 2365403134 Jystick4ThetaAxisDetentPosStatus "Reports when the current joystick position is in the detent position for that axis of travel.

00 Not in the Detent Position
01 In the Detent Position
10 Error Indicator
11 Not Available";
CM_ SG_ 2365403134 Joystick4ThetaAxisPos "The position of the joystick in the relative motion of travel from the neutral position.  Position value of 0 is Neutral and position value 1000 (100%) is the end of linear zone.  Value of 1022 indicates an error has occurred.";
CM_ SG_ 2365403134 Jystck4ThtAxsClckwsPstvPosStatus "Reports when the current joystick position is on the positive travel side (forward, right, clockwise, up) relative to the neutral position for that axis of travel.
00 Not on Positive side of Neutral
01 On positive side of Neutral
10 Error ...";
CM_ SG_ 2365403134 Jystck4ThtAxsCntrClckwsNgtvPsStt "Reports when the current joystick position is on the negative travel side (back, left, counterclockwise, down) relative to the neutral position for that axis of travel.
00 Not on negative side of Neutral
01 On negative side of Neutral
10 Error ...";
CM_ SG_ 2365403134 Jystck4ThetaAxisNeutralPosStatus "Reports when the current joystick position is in the neutral position for that axis of travel.  The neutral position measurement must be determined from some mechanism other than the axis position measurement device.
00 Not in Neutral Position
01 ...";
CM_ SG_ 2365403134 Joystick4GripYAxisPos "The position of the joystick grip in the relative motion of travel from the neutral position.  Position value of 0 is Neutral and position value 1000 (100%) is the end of linear zone.  Value of 1022 indicates an error has occurred.";
CM_ SG_ 2365403134 Jystck4GrpYAxsLvrFrwrdPstvPsStts "Reports when the current joystick grip position is on the positive travel side (forward, right, clockwise, up) relative to the neutral position for that axis of travel.
00 Not on Positive side of Neutral
01 On positive side of Neutral
10 Error ...";
CM_ SG_ 2365403134 Jystck4GrpYAxsLvrBckNgtvPsStatus "Reports when the current joystick grip position is on the negative travel side (back, left, counterclockwise, down) relative to the neutral position for that axis of travel.
00 Not on negative side of Neutral
01 On negative side of Neutral
10 ...";
CM_ SG_ 2365403134 Jystck4GripYAxisNeutralPosStatus "Reports when the current joystick grip position is in the neutral position for that axis of travel.  The neutral position measurement must be determined from some mechanism other than the axis position measurement device.
00 Not in Neutral Position
 ...";
CM_ SG_ 2365403134 Joystick4GripXAxisPos "The position of the joystick grip in the relative motion of travel from the neutral position.  Position value of 0 is Neutral and position value 1000 (100%) is the end of linear zone.  Value of 1022 indicates an error has occurred.";
CM_ SG_ 2365403134 Jystck4GrpXAxsLvrRghtPstvPsSttus "Reports when the current joystick grip position is on the positive travel side (forward, right, clockwise, up) relative to the neutral position for that axis of travel.
00 Not on Positive side of Neutral
01 On positive side of Neutral
10 Error ...";
CM_ SG_ 2365403134 Jystck4GrpXAxsLvrLftNgtvPsStatus "Reports when the current joystick grip position is on the negative travel side (back, left, counterclockwise, down) relative to the neutral position for that axis of travel.
00 Not on negative side of Neutral
01 On negative side of Neutral
10 ...";
CM_ SG_ 2365403134 Jystck4GripXAxisNeutralPosStatus "Reports when the current joystick grip position is in the neutral position for that axis of travel.  The neutral position measurement must be determined from some mechanism other than the axis position measurement device.
00 Not in Neutral Position
 ...";
CM_ BO_ 2365400062 "Extended Joystick Message 10
Used to transfer information about the measured status of three additional axes of a joystick and switches of the joystick grip or handle.  The joystick axial motion information is available in the Basic Joystick ...";
CM_ SG_ 2365400062 Joystick10Button13PressedStatus "Reports when the joystick button has been pressed.

00 Button not pressed
01 Button pressed
10 Error Indicator
11 Not Available";
CM_ SG_ 2365400062 Joystick10Button14PressedStatus "Reports when the joystick button has been pressed.

00 Button not pressed
01 Button pressed
10 Error Indicator
11 Not Available";
CM_ SG_ 2365400062 Joystick10Button15PressedStatus "Reports when the joystick button has been pressed.

00 Button not pressed
01 Button pressed
10 Error Indicator
11 Not Available";
CM_ SG_ 2365400062 Joystick10Button16PressedStatus "Reports when the joystick button has been pressed.

00 Button not pressed
01 Button pressed
10 Error Indicator
11 Not Available";
CM_ SG_ 2365400062 Jystck10GripXAxisDetentPosStatus "Reports when the current joystick grip position is in the detent position for that axis of travel.

00 Not in the Detent Position
01 In the Detent Position
10 Error Indicator
11 Not Available";
CM_ SG_ 2365400062 Jystck10GripYAxisDetentPosStatus "Reports when the current joystick grip position is in the detent position for that axis of travel.

00 Not in the Detent Position
01 In the Detent Position
10 Error Indicator
11 Not Available";
CM_ SG_ 2365400062 Jystck10ThetaAxisDetentPosStatus "Reports when the current joystick position is in the detent position for that axis of travel.

00 Not in the Detent Position
01 In the Detent Position
10 Error Indicator
11 Not Available";
CM_ SG_ 2365400062 Joystick10ThetaAxisPos "The position of the joystick in the relative motion of travel from the neutral position.  Position value of 0 is Neutral and position value 1000 (100%) is the end of linear zone.  Value of 1022 indicates an error has occurred.";
CM_ SG_ 2365400062 Jystck10ThtAxsClckwsPstvPsStatus "Reports when the current joystick position is on the positive travel side (forward, right, clockwise, up) relative to the neutral position for that axis of travel.
00 Not on Positive side of Neutral
01 On positive side of Neutral
10 Error ...";
CM_ SG_ 2365400062 Jystck10ThtAxsCntrClckwsNgtvPsSt "Reports when the current joystick position is on the negative travel side (back, left, counterclockwise, down) relative to the neutral position for that axis of travel.
00 Not on negative side of Neutral
01 On negative side of Neutral
10 Error ...";
CM_ SG_ 2365400062 Jystck10ThtaAxisNeutralPosStatus "Reports when the current joystick position is in the neutral position for that axis of travel.  The neutral position measurement must be determined from some mechanism other than the axis position measurement device.
00 Not in Neutral Position
01 ...";
CM_ SG_ 2365400062 Joystick10GripYAxisPos "The position of the joystick grip in the relative motion of travel from the neutral position.  Position value of 0 is Neutral and position value 1000 (100%) is the end of linear zone.  Value of 1022 indicates an error has occurred.";
CM_ SG_ 2365400062 Jystck10GrpYAxsLvrFrwrdPstvPsStt "Reports when the current joystick grip position is on the positive travel side (forward, right, clockwise, up) relative to the neutral position for that axis of travel.
00 Not on Positive side of Neutral
01 On positive side of Neutral
10 Error ...";
CM_ SG_ 2365400062 Jystck10GrpYAxsLvrBckNgtvPsSttus "Reports when the current joystick grip position is on the negative travel side (back, left, counterclockwise, down) relative to the neutral position for that axis of travel.
00 Not on negative side of Neutral
01 On negative side of Neutral
10 ...";
CM_ SG_ 2365400062 Jystck10GrpYAxisNeutralPosStatus "Reports when the current joystick grip position is in the neutral position for that axis of travel.  The neutral position measurement must be determined from some mechanism other than the axis position measurement device.
00 Not in Neutral Position
 ...";
CM_ SG_ 2365400062 Joystick10GripXAxisPos "The position of the joystick grip in the relative motion of travel from the neutral position.  Position value of 0 is Neutral and position value 1000 (100%) is the end of linear zone.  Value of 1022 indicates an error has occurred.";
CM_ SG_ 2365400062 Jystck10GrpXAxsLvrRghtPstvPsStts "Reports when the current joystick grip position is on the positive travel side (forward, right, clockwise, up) relative to the neutral position for that axis of travel.
00 Not on Positive side of Neutral
01 On positive side of Neutral
10 Error ...";
CM_ SG_ 2365400062 Jystck10GrpXAxsLvrLftNgtvPsSttus "Reports when the current joystick grip position is on the negative travel side (back, left, counterclockwise, down) relative to the neutral position for that axis of travel.
00 Not on negative side of Neutral
01 On negative side of Neutral
10 ...";
CM_ SG_ 2365400062 Jystck10GrpXAxisNeutralPosStatus "Reports when the current joystick grip position is in the neutral position for that axis of travel.  The neutral position measurement must be determined from some mechanism other than the axis position measurement device.
00 Not in Neutral Position
 ...";
CM_ BO_ 2566713598 "Engine Fuel/lube systems 2
Contains information on the engine fuel and lube system";
CM_ SG_ 2566713598 FuelTankTransferPumpPress "Gage pressure of the fuel in the system as delivered by the transfer pump.";
CM_ SG_ 2566713598 FuelTankTransferPump "Operating state of the fuel tank transfer pump. The fuel tank transfer pump transfers fuel from the secondary fuel tank to the primary fuel tank.

00 = Off
01 = On
10 = Error
11 = Not available";
CM_ SG_ 2566713598 EngFuelFilterDegradation "The estimated percentage relative to the useful life of the engine fuel filter on the suction side which is located betwee the fuel tank and the fuel supply pump.
Note:  This is not a calculation of the physical restriction of the filter. 0% is ...";
CM_ SG_ 2566713598 EngFuelFilterIntakeAbsPress "Absolute pressure of fuel at the intake of the fuel filter (suction side) located between the fuel tank and the fuel supply pump.  See Figures SPN16_A & SPN16_B.";
CM_ BO_ 2499604478 "Engine Fluid Level/Pressure 11
Engine related parameters.";
CM_ SG_ 2499604478 EngFuelDeliveryPress "Gage pressure of fuel in system as delivered from supply pump to the injection pump. See SPN 94 for alternate resolution.

See also SPN 5578 for Engine Fuel Delivery Absolute Pressure.";
CM_ SG_ 2499604478 EngOilPress "Gage pressure of oil in engine lubrication system as provided by oil pump. See SPN 100 for alternate resolution.";
CM_ SG_ 2499604478 EngExhstGsRcrcltn1OutletAbsPress "EGR outlet absolute pressure is measured after the EGR 1 valve. See SPN 5019 for 1 byte resolution.";
CM_ SG_ 2499604478 EngExhstGsRcrcltn1IntakeAbsPress "EGR intake absolute pressure measured before the EGR 1 valve.";
CM_ BO_ 2499608830 "Engine Fluid Level/Pressure 10
Engine related parameters";
CM_ SG_ 2499608830 EngCoolantPress2 "Gage pressure of liquid found in the engine coolant system - second instance.

See SPN 7313 for alternate range and resolution.";
CM_ SG_ 2499608830 EngExhstGsRcrcltn2IntakeAbsPress "EGR intake absolute pressure measured before the EGR 2 valve.";
CM_ SG_ 2499608830 EngExhstGsRcrcltn2OutletAbsPress "Absolute Pressure immediately after the EGR2 valve";
CM_ SG_ 2499608830 EngExhstGsRcrclation2IntakePress "EGR2 intake gauge pressure is measured after EGR2 cooler and before EGR2 valve";
CM_ SG_ 2499608830 EngExhstGsRcirculation2DiffPress "Differential Pressure across the Exhaust Gas Recirculation 2 (EGR2) system.";
CM_ BO_ 2432499198 "Electronic Engine Controller 9
Engine related parameters";
CM_ SG_ 2432499198 CmmndedEngFuelInjectionCtrlPress "Provides the commanded set point value for the engine fuel injection control pressure.";
CM_ SG_ 2432499198 CommandedEngFuelRailPress "Provides the commanded set point value for the engine fuel rail gage pressure";
CM_ SG_ 2432499198 EngExhstGsRcirculation2Valve2Pos "The position of the second exhaust gas recirculation valve of EGR 2 expressed as a percentage of full travel. 0% means the valve is closed and no exhaust gas is flowing into the air stream. 100% means the valve is fully opened.";
CM_ SG_ 2432499198 EngExhstGsRecirculation2ValvePos "Position of EGR2 valve expressed as a percentage of full travel. 0% means the valve is closed and no exhaust gas is flowing into the air stream. 100% means the valve is fully opened.";
CM_ BO_ 2633825022 "Electronic Engine Controller 11
Engine related parameters";
CM_ SG_ 2633825022 EngExhstGsRcrcltn2Valve2PosError "The position error of the Exhaust Gas Recirculation 2 valve 2, determined as the actual position (SPN 5265) minus the commanded position (SPN 5263).";
CM_ SG_ 2633825022 EngExhstGsRcrcltn2Valve1PosError "The position error of the Exhaust Gas Recirculation 2 valve, determined as the actual position (SPN 5264) minus the commanded position (SPN 5262).";
CM_ SG_ 2633825022 EngExhstGsRcrculation2Valve2Ctrl "Desired percentage of maximum Exhaust Gas Recirculation 2 (EGR2) valve 2 opening. 0% means the valve is closed. 100% means maximum opening (full gas flow).";
CM_ SG_ 2633825022 EngExhstGsRcirculation2ValveCtrl "Desired percentage of maximum Exhaust Gas Recirculation 2 (EGR2) valve opening. 0% means the valve is closed. 100% means maximum opening (full gas flow).";
CM_ BO_ 2633826046 "Electronic Engine Controller 10
Engine related parameters";
CM_ SG_ 2633826046 EGR2CoolerBypassActuatorPos "EGR2 Cooler Bypass Actuator position, where 0% = Fully Closed (no gas flowing through the bypass), and 100% = Fully Open..";
CM_ SG_ 2633826046 EngExhstGsRcrcltn2ClerEfficiency "Exhaust Gas Recirculation 2 cooler efficiency is an indication of the cooler’s ability to reduce the temperature of the exhaust gas that is being recirculated back to the intake. 0% = no reduction in temperature, 100% = maximum cooling. The EGR 2 ...";
CM_ SG_ 2633826046 EngExhstGsRcrcltn2ClrIntkGsAbsPr "Exhaust Gas Recirculation 2 gas absolute pressure is measured at EGR2 cooler intake. See SPN 5253 for EGR2 pressure measured at the EGR2 cooler outlet before the valve.";
CM_ SG_ 2633826046 EngExhstGsRcrcltn2ClerIntakeTemp "Exhaust Gas Recirculation 2 (EGR2) Temperature measured at EGR2 cooler intake. See SPN 5255 for Engine EGR2 temperature.";
CM_ BO_ 2566711294 "Engine Configuration 3
The EC3 message contains a static engine friction torque map consisting of torque points that correspond to the speed points in the EC1 message.  A net brake torque map for the engine can be calculated by subtracting the ...";
CM_ SG_ 2566711294 EngFrictionPercentTorquePoint7 "The static portion of the friction torque at speed point 7 (SPN 533) of the engine torque map in the engine configuration message.  This parameter does not include Estimated Pumping - Percent Torque (SPN 5398) and is expected to change with ...";
CM_ SG_ 2566711294 EngFrictionPercentTorquePoint6 "For engine configuration map modes 1 and 2, this is the static portion of the friction torque at speed point 6 (SPN 532) of the engine torque map.  For engine configuration map mode 3, this parameter is the static portion of the friction torque at ...";
CM_ SG_ 2566711294 EngFrictionPercentTorquePoint5 "The static portion of the friction torque at speed point 5 (SPN 531) of the engine torque map in the engine configuration message.  This parameter does not include Estimated Pumping - Percent Torque (SPN 5398) and is expected to change with ...";
CM_ SG_ 2566711294 EngFrictionPercentTorquePoint4 "The static portion of the friction torque at speed point 4 (SPN 530) of the engine torque map in the engine configuration message.  This parameter does not include Estimated Pumping - Percent Torque (SPN 5398) and is expected to change with ...";
CM_ SG_ 2566711294 EngFrictionPercentTorquePoint3 "The static portion of the friction torque at speed point 3 (SPN 529) of the engine torque map in the engine configuration message.  This parameter does not include Estimated Pumping - Percent Torque (SPN 5398) and is expected to change with ...";
CM_ SG_ 2566711294 EngFrictionPercentTorquePoint2 "The static portion of the friction torque at speed point 2 (SPN 528) of the engine torque map in the engine configuration message.  This parameter does not include Estimated Pumping - Percent Torque (SPN 5398) and is expected to change with ...";
CM_ SG_ 2566711294 EngFrctnPrcentTorqueAtIdlePoint1 "The static portion of the friction torque at speed point 1 (SPN 188) of the engine torque map in the engine configuration message.  This parameter does not include Estimated Pumping - Percent Torque (SPN 5398) and is expected to change with ...";
CM_ BO_ 2566749438 "Diesel Particulate Filter Control 1
This PGN contains information about the diesel particulate filter regeneration control.
If there are aftertreatment systems on two banks, this PGN represents the composite information from both banks.
NOTE ...";
CM_ SG_ 2566749438 DslPrtcltFltrActvRgnrtnInhbt5629 "Indicates the state of diesel particulate filter active regeneration inhibition due to low exhaust pressure.
00 not inhibited
01 inhibited
10 reserved for SAE assignment
11 not available
This SPN indicates the reason for the diesel particulate ...";
CM_ SG_ 2566749438 AFT1DPFCondNotMetForActiveRegen "Indicates that diesel particulate filter 1 is not able to begin or continue an active regenerate event at the current engine operating conditions.
00 active DPF regeneration not inhibited
01 active DPF regeneration inhibited
10 reserved for SAE ...";
CM_ SG_ 2566749438 HydrocarbonDoserPurgingEnable "Purging enable of the Hydrocarbon Doser (HCD).

00 Purging not enabled
01 Purging enabled - less urgent
10 Purging enabled - urgent
11 Not available";
CM_ SG_ 2566749438 DslPrtcltFltrActvRgnrtnFrcdSttus "Indicates the forced execution status of diesel particulate filter regeneration.
000 Not Active
001 Active - Forced by Switch (See SPN 3696)
010 Active - Forced by Service Tool
011 Reserved for SAE Assignment
100 Reserved for SAE Assignment
 ...";
CM_ SG_ 2566749438 ExhaustSystemHighTempLampCmd "Command to control the exhaust system high temperature lamp.  This lamp indicates that the exhaust system temperature is high.
000 Off
001 On - solid
010 reserved for SAE assignment
011 reserved for SAE assignment
100 reserved for SAE ...";
CM_ SG_ 2566749438 DslPrtcltFltrAtmtcActvRgnrtnIntt "Indicates the configuration of diesel particulate filter active regeneration automatic initiation.

00 not enabled
01 enabled
10 reserved for SAE assignment
11 not available";
CM_ SG_ 2566749438 DslPrtcltFltrActvRgnrtnInhbt3717 "Indicates the state of diesel particulate filter active regeneration inhibition due to vehicle speed being less than the allowed vehicle speed.
00 not inhibited
01 inhibited
10 reserved for SAE assignment
11 not available
This SPN indicates the ...";
CM_ SG_ 2566749438 DslPrtcltFltrActvRgnrtnInhbtdDTE "Indicates the state of diesel particulate filter active regeneration inhibition due to the engine not being warmed up.
00 not inhibited
01 inhibited
10 reserved for SAE assignment
11 not available
This SPN indicates the reason for the diesel ...";
CM_ SG_ 2566749438 DslPrtcltFltrActvRgnrtnInhbt3715 "Indicates the state of diesel particulate filter active regeneration inhibition due to a permanent system lockout.
00 not inhibited
01 inhibited
10 reserved for SAE assignment
11 not available
This SPN indicates the reason for the diesel ...";
CM_ SG_ 2566749438 DslPrtcltFltrActvRgnrtnInhbtdDTT "Indicates the state of diesel particulate filter active regeneration inhibition due to a temporary system lockout.
00 not inhibited
01 inhibited
10 reserved for SAE assignment
11 not available
This SPN indicates the reason for the diesel ...";
CM_ SG_ 2566749438 DslPrtcltFltrActvRgnrtnInhbt3713 "Indicates the state of diesel particulate filter active regeneration inhibition due to a system timeout.
00 not inhibited
01 inhibited
10 reserved for SAE assignment
11 not available
This SPN indicates the reason for the diesel particulate ...";
CM_ SG_ 2566749438 DslPrtcltFltrActvRgnrtnInhbt3712 "Indicates the state of diesel particulate filter active regeneration inhibition due to a system fault being active.
00 not inhibited
01 inhibited
10 reserved for SAE assignment
11 not available
This SPN indicates the reason for the diesel ...";
CM_ SG_ 2566749438 DslPrtcltFltrActvRgnrtnInhbtdDTL "Indicates the state of diesel particulate filter active regeneration inhibition due to the exhaust temperature being too low.  This implies that the diesel particulate filter and/or oxidation catalyst are likewise too cold for active regeneration.
 ...";
CM_ SG_ 2566749438 DslPrtcltFltrActvRgnrtnInhbt3710 "Indicates the state of diesel particulate filter active regeneration inhibition due to the parking brake being not set.
00 not inhibited
01 inhibited
10 reserved for SAE assignment
11 not available
This SPN indicates the reason for the diesel ...";
CM_ SG_ 2566749438 DslPrtcltFltrActvRgnrtnInhbtdDTV "Indicates the state of diesel particulate filter active regeneration inhibition due to the vehicle speed being above an allowed limit.
00 not inhibited
01 inhibited
10 reserved for SAE assignment
11 not available
This SPN indicates the reason ...";
CM_ SG_ 2566749438 DslPrtcltFltrActvRgnrtnInhbtdDTO "Indicates the state of diesel particulate filter active regeneration inhibition due to the transmission being out of neutral.
00 not inhibited
01 inhibited
10 reserved for SAE assignment
11 not available
This SPN indicates the reason for the ...";
CM_ SG_ 2566749438 DslPrtcltFltrActvRgnrtnInhbtdDTA "Indicates the state of diesel particulate filter active regeneration inhibition due to the accelerator pedal being off idle.
00 not inhibited
01 inhibited
10 reserved for SAE assignment
11 not available
This SPN indicates the reason for the ...";
CM_ SG_ 2566749438 DslPrtcltFltrActvRgnrtnInhbtdDTP "Indicates the state of diesel particulate filter active regeneration inhibition due to the PTO being active.
00 not inhibited
01 inhibited
10 reserved for SAE assignment
11 not available
This SPN indicates the reason for the diesel particulate ...";
CM_ SG_ 2566749438 DslPrtcltFltrActvRgnrtnInhbtdDTS "Indicates the state of diesel particulate filter active regeneration inhibition due to the service brake being active.
00 not inhibited
01 inhibited
10 reserved for SAE assignment
11 not available
This SPN indicates the reason for the diesel ...";
CM_ SG_ 2566749438 DslPrtcltFltrActvRgnrtnInhbtdDTC "Indicates the state of diesel particulate filter active regeneration inhibition due to the clutch being disengaged.
00 not inhibited
01 inhibited
10 reserved for SAE assignment
11 not available
This SPN indicates the reason for the diesel ...";
CM_ SG_ 2566749438 DslPrtcltFltrActvRgnrtnInhbtdDTI "Indicates the state of diesel particulate filter active regeneration inhibition due to the Diesel Particulate Filter Regeneration Inhibit Switch.
00 not inhibited
01 inhibited
10 reserved for SAE assignment
11 not available
This SPN indicates ...";
CM_ SG_ 2566749438 DslPrtcltFltrActvRgnrtnInhbtdStt "Indicates the state of diesel particulate filter active regeneration inhibition.
00 not inhibited
01 inhibited
10 reserved for SAE assignment
11 not available
This SPN indicates the reason for the diesel particulate filter regeneration not ...";
CM_ SG_ 2566749438 AFTDPFStatus "Indicates the state of the diesel particulate filter regeneration need and urgency.  This is an aggregate of bank 1 and bank 2.  It is a system status and not individual bank status.
000 Regeneration not needed
001 Regeneration needed - lowest ...";
CM_ SG_ 2566749438 AFTDPFActiveRegenStatus "Indicates the state of diesel particulate filter active regeneration.  This is an aggregate of bank 1 and bank 2.  It is a system status and not individual bank status.
00 not active
01 active
10 regeneration needed - automatically initiated ...";
CM_ SG_ 2566749438 AFTDPFPassiveRegenStatus "Indicates the state of diesel particulate filter passive regeneration.  This is an aggregate of bank 1 and bank 2.  It is a system status and not individual bank status.


00 not active
01 active
10 reserved for SAE assignment
11 not available";
CM_ SG_ 2566749438 DieselParticulateFilterLampCmd "Command to control the diesel particulate filter lamp.
000 Off
001 On - solid
010 reserved for SAE assignment
011 reserved for SAE assignment
100 On - fast blink (1 HZ)
101 reserved for SAE assignment
110 reserved for SAE assignment
111 not ...";
CM_ BO_ 2566715646 "Diesel Particulate Filter 2 Soot 2
Additional diesel particulate filter soot parameters for diesel particulate filter 2.";
CM_ SG_ 2566715646 AFT2DPFSootSignalMin "Minimum output signal level of the current soot measurement from diesel particulate filter 2 soot sensor.  This is a statistical value, not the minimum sensing capability of the sensor.";
CM_ SG_ 2566715646 AFT2DPFSootSignalMax "Maximum output signal level of the current soot measurement from diesel particulate filter 2 soot sensor.  This is a statistical value, not the maximum sensing capability of the sensor.";
CM_ SG_ 2566715646 AFT2DPFSootSignalStdDeviation "Standard deviation of the soot measurement from diesel particulate filter 2 soot sensor.";
CM_ BO_ 2566724606 "Diesel Particulate Filter 2 Soot
Diesel particulate filter soot parameters for diesel particulate filter 2.";
CM_ SG_ 2566724606 DslPrtcltFltr2StSnsrECUIntrnlTmp "Internal temperature of the diesel particulate filter 2 soot sensor ECU.";
CM_ SG_ 2566724606 AFT2DPFSootSnsrPreliminaryFMI "Used to identify the applicable J1939-73 FMI detected in the soot sensor signal by the manufacturer’s sensor control software in diesel particulate filter 2. When there is no failure FMI 31 is sent. In the case of multiple failures the most severe ...";
CM_ SG_ 2566724606 AFT2DPFMedianSootSignal "Median output signal level from diesel particulate filter 2 soot sensor.";
CM_ SG_ 2566724606 AFT2DPFMeanSootSignal "Mean output signal level from diesel particulate filter 2 soot sensor.";
CM_ SG_ 2566724606 AFT2DPFSootDensity "Soot density in diesel particulate filter 2.";
CM_ SG_ 2566724606 AFT2DPFSootMass "Soot mass in diesel particulate filter 2.";
CM_ BO_ 2566715902 "Diesel Particulate Filter 1 Soot 2
Additional diesel particulate filter soot parameters for diesel particulate filter 1.";
CM_ SG_ 2566715902 AFT1DPFSootSignalMin "Minimum output signal level of the current soot measurement from diesel particulate filter 1 soot sensor.  This is a statistical value, not the minimum sensing capability of the sensor.";
CM_ SG_ 2566715902 AFT1DPFSootSignalMax "Maximum output signal level of the current soot measurement from diesel particulate filter 1 soot sensor.  This is a statistical value, not the maximum sensing capability of the sensor.";
CM_ SG_ 2566715902 AFT1DPFSootSignalStdDeviation "Standard deviation of the soot measurement from diesel particulate filter 1 soot sensor.";
CM_ BO_ 2566724862 "Diesel Particulate Filter 1 Soot
Diesel particulate filter soot parameters for diesel particulate filter 1.";
CM_ SG_ 2566724862 DslPrtcltFltr1StSnsrECUIntrnlTmp "Internal temperature of the diesel particulate filter 1 soot sensor ECU.";
CM_ SG_ 2566724862 AFT1DPFSootSnsrPreliminaryFMI "Used to identify the applicable J1939-73 FMI detected in the soot sensor signal by the manufacturer’s sensor control software in diesel particulate filter 1. When there is no failure FMI 31 is sent. In the case of multiple failures the most severe ...";
CM_ SG_ 2566724862 AFT1DPFMedianSootSignal "Median output signal level from diesel particulate filter 1 soot sensor.";
CM_ SG_ 2566724862 AFT1DPFMeanSootSignal "Mean output signal level from diesel particulate filter 1 soot sensor.";
CM_ SG_ 2566724862 AFT1DPFSootDensity "Soot density in diesel particulate filter 1.";
CM_ SG_ 2566724862 AFT1DPFSootMass "Soot mass in diesel particulate filter 1.";
CM_ BO_ 2566718718 "Direct Lamp Control Data 2
This message will be transmitted by the controller that is illuminating the lamps.

It is not required to be used with PGN 64774.";
CM_ SG_ 2566718718 HillHolderLampData "This message will be transmitted by the controller that is illuminating the lamps.

00 - Lamp deactivated (Off)
01 - Lamp activated (On)
10 - Error
11 - Not Available";
CM_ SG_ 2566718718 VehicleBatteryChargingLampData "This parameter provides measured data from the Vehicle Battery Charging Lamp.

00 - Lamp deactivated (Off)
01 - Lamp activated (On)
10 - Error
11 - Not available";
CM_ SG_ 2566718718 VehicleHVACRecirculationLampData "This parameter provides measured data from the Vehicle HVAC Recirculation Lamp.

00 - Lamp deactivated (Off)
01 - Lamp activated (On)
10 - Error
11 - Not available";
CM_ SG_ 2566718718 VehicleAirPressLowLampData "This parameter provides measured data from the Vehicle Air Pressure Low Lamp.

00 - Lamp deactivated (Off)
01 - Lamp activated (On)
10 - Error
11 - Not available";
CM_ SG_ 2566718718 VehicleFuelLevelLowLampData "This parameter provides measured data from the Vehicle Fuel Level Low Lamp.

00 - Lamp deactivated (Off)
01 - Lamp activated (On)
10 - Error
11 - Not available";
CM_ SG_ 2566718718 VehicleBatteryVoltageLowLampData "This parameter provides measured data from the Vehicle Battery Voltage Low Lamp.

00 - Lamp deactivated (Off)
01 - Lamp activated (On)
10 - Error
11 - Not available";
CM_ BO_ 2566718974 "Direct Lamp Control Data 1
This message will be transmitted by the controller that is illuminating the lamps.

It is not required to be used with PGN 64775.";
CM_ SG_ 2566718974 VhclAcclerationRateLimitLampData "This parameter provides measured data from the Vehicle Acceleration Rate Limit Lamp.

00 - Lamp deactivated (Off)
01 - Lamp activated (On)
10 - Error
11 - Not available";
CM_ SG_ 2566718974 EngSpeedVeryHighLampData "This parameter provides measured data from the Engine Speed Very High Warning Lamp.

00 - Lamp Deactivated (Off)
01 - Lamp Activated (On)
10 - Error
11 - Not available";
CM_ SG_ 2566718974 EngSpeedHighLampData "This parameter provides measured data from the Engine Speed High Warning Lamp.

00 - Lamp Deactivated (Off)
01 - Lamp Activated (On)
10 - Error
11 - Not available";
CM_ SG_ 2566718974 EngCtrlMdule3ReadyForUseLampData "This parameter provides measured data from the Engine Control Module 3 Ready for Use Lamp.

00 - Lamp deactivated (Off)
01 - Lamp activated (On)
10 - Error
11 - Not Available";
CM_ SG_ 2566718974 EngCtrlMdule2ReadyForUseLampData "This parameter provides measured data from the Engine Control Module 2 Ready for Use Lamp.

00 - Lamp deactivated (Off)
01 - Lamp activated (On)
10 - Error
11 - Not Available";
CM_ SG_ 2566718974 EngCtrlMdule1ReadyForUseLampData "This parameter provides measured data from the Engine Control Module 1 Ready for Use Lamp.

00 - Lamp deactivated (Off)
01 - Lamp activated (On)
10 - Error
11 - Not Available";
CM_ SG_ 2566718974 EngWaitToStartLampData "This parameter provides measured data from the Engine Wait To Start Lamp.  See SPN 1081 for the command.

00 - Lamp deactived (off)
01 - Lamp actived (on)
10 - Error
11 - Not available";
CM_ SG_ 2566718974 EngFuelFilterRestrictedLampData "This parameter provides measured data from the Engine Fuel Filter Restricted Lamp.

00 - Lamp deactivated (Off)
01 - Lamp activated (On)
10 - Error
11 - Not available";
CM_ SG_ 2566718974 EngAirFilterRestrictionLampData "This parameter provides measured data from the Engine Air Filter Restriction Lamp.

00 - Lamp deactivated (Off)
01 - Lamp activated (On)
10 - Error
11 - Not available";
CM_ SG_ 2566718974 EngIdleManagementActiveLampData "This parameter provides measured data from the Engine Idle Management Active Lamp.

00 - Lamp deactivated (Off)
01 - Lamp activated (On)
10 - Error
11 - Not available";
CM_ SG_ 2566718974 EngCoolantLevelLowLampData "This parameter provides measured data from the Engine Coolant Level Low Lamp.

00 - Lamp deactivated (Off)
01 - Lamp activated (On)
10 - Error
11 - Not available";
CM_ SG_ 2566718974 EngCoolantTempHighLampData "This parameter provides measured data from the Engine Coolant Temperature High Lamp.

00 - Lamp deactivated (Off)
01 - Lamp activated (On)
10 - Error
11 - Not available";
CM_ SG_ 2566718974 EngOilPressLowLampData "This parameter provides measured data from the Engine Oil Pressure Low Lamp.

00 - Lamp deactivated (Off)
01 - Lamp activated (On)
10 - Error
11 - Not available";
CM_ SG_ 2566718974 CmprssnBrkEnblSwtchIndctrLmpData "This parameter provides measured data from the Compression Brake Enable Switch Indicator Lamp.

00 - Lamp deactivated (Off)
01 - Lamp activated (On)
10 - Error
11 - Not available";
CM_ SG_ 2566718974 EngBrakeActiveLampData "This parameter provides measured data from the Engine Brake Active Lamp.

00 - Lamp deactivated (Off)
01 - Lamp activated (On)
10 - Error
11 - Not available";
CM_ SG_ 2566718974 OBDMalfunctionIndicatorLampData "This parameter provides measured data from the OBD Malfunction Indicator Lamp.

00 - Lamp deactivated (Off)
01 - Lamp activated (On)
10 - Error
11 - Not available";
CM_ SG_ 2566718974 EngRedStopLampData "This parameter provides measured data from the Engine Red Stop Lamp.

00 - Lamp deactivated (Off)
01 - Lamp activated (On)
10 - Error
11 - Not available";
CM_ SG_ 2566718974 EngAmberWarningLampData "This parameter provides measured data from the Engine Amber Warning Lamp.

00 - Lamp deactivated (Off)
01 - Lamp activated (On)
10 - Error
11 - Not available";
CM_ SG_ 2566718974 EngProtectLampData "This parameter provides measured data from the Engine Protect Lamp.

00 - Lamp deactivated (Off)
01 - Lamp activated (On)
10 - Error
11 - Not available";
CM_ BO_ 2566719230 "Direct Lamp Control Command 2
Message that directly controls the driver indicator lamps.   See also PGN 64775 for additional lamps and PGN 64772 for the feedback information about these lamps.
Note: Since this message is direct lamp control, it is ...";
CM_ SG_ 2566719230 HillHolderLampCmd "Command signal directly controlling Hill Holder Lamp.

00 - Lamp Off
01 - Lamp On
10 - Lamp Flash (1 Hz)
11 - Not available";
CM_ SG_ 2566719230 VehicleBatteryChargingLampCmd "Command signal directly controlling the Vehicle Battery Charging Lamp.

00 - Lamp Off
01 - Lamp On
10 - Reserved
11 - Not available";
CM_ SG_ 2566719230 VehicleHVACRecirculationLampCmd "Command signal directly controlling the Vehicle HVAC Recirculation Lamp.

00 - Lamp Off
01 - Lamp On
10 - Reserved
11 - Not available";
CM_ SG_ 2566719230 VehicleAirPressLowLampCmd "Command signal directly controlling the Vehicle Air Pressure Low Lamp.

00 - Lamp Off
01 - Lamp On
10 - Reserved
11 - Not available";
CM_ SG_ 2566719230 VehicleFuelLevelLowLampCmd "Command signal directly controlling the Vehicle Fuel Level Low Lamp.

00 - Lamp Off
01 - Lamp On
10 - Reserved
11 - Not available";
CM_ SG_ 2566719230 VehicleBatteryVoltageLowLampCmd "Command signal directly controlling the Vehicle Battery Voltage Low Lamp.

00 - Lamp Off
01 - Lamp On
10 - Reserved
11 - Not available";
CM_ BO_ 2560818942 "Regulated Exhaust Emission Level Exceedance
Provides the DTCs and associated timers related to a regulated exhaust emission level exceedance due to an emission control system malfunction.";
CM_ SG_ 2560818942 SPN1 "This 19-bit number is used to identify the item for which diagnostics are being reported.";
CM_ SG_ 2560818942 FailureModeIdentifier1 "The FMI defines the type of failure detected in the subsystem identified by an SPN.";
CM_ SG_ 2560818942 DTCTimeUntilDerate "This timer provides the number of hours the malfunction has until the OBD required derate will occur";
CM_ SG_ 2560818942 DTCTotalPreviouslyActiveTime "This timer provides the number of hours the NOx malfunction has been confirmed and previously active";
CM_ SG_ 2560818942 DTCTotalActiveTime "This timer provides the total number of hours the DTC has been confirmed and active";
CM_ SG_ 2560818942 SPN1High "SPN #1 (Conversion Version 4)";
BA_DEF_ SG_  "SigType" ENUM  "Default","Range","RangeSigned","ASCII","Discrete","Control","ReferencePGN","DTC","StringDelimiter","StringLength","StringLengthControl","MessageCounter","MessageChecksum";
BA_DEF_ SG_  "GenSigStartValue" INT 0 2147483647;
BA_DEF_ SG_  "GenSigSendType" ENUM  "Cyclic","OnWrite","OnWriteWithRepetition","OnChange","OnChangeWithRepetition","IfActive","IfActiveWithRepetition","NoSigSendType";
BA_DEF_ SG_  "GenSigILSupport" ENUM  "No","Yes";
BA_DEF_ SG_  "GenSigEVName" STRING ;
BA_DEF_ SG_  "SPN" INT 0 524287;
BA_DEF_ BO_  "TpJ1939VarDlc" ENUM  "No","Yes";
BA_DEF_ BO_  "GenMsgStartDelayTime" INT 0 100000;
BA_DEF_ BO_  "GenMsgILSupport" ENUM  "No","Yes";
BA_DEF_ BO_  "GenMsgDelayTime" INT 0 1000;
BA_DEF_ BO_  "GenMsgRequestable" INT 0 1;
BA_DEF_ BO_  "GenMsgSendType" ENUM  "cyclic","NotUsed","NotUsed","NotUsed","NotUsed","NotUsed","NotUsed","IfActive","noMsgSendType";
BA_DEF_ BO_  "VFrameFormat" ENUM  "StandardCAN","ExtendedCAN","reserved","J1939PG";
BA_DEF_ BO_  "GenMsgCycleTime" INT 0 3600000;
BA_DEF_ SG_  "SystemSignalLongSymbol" STRING ;
BA_DEF_DEF_  "SigType" "Default";
BA_DEF_DEF_  "GenSigStartValue" 0;
BA_DEF_DEF_  "GenSigSendType" "NoSigSendType";
BA_DEF_DEF_  "GenSigILSupport" "Yes";
BA_DEF_DEF_  "GenSigEVName" "Env@Nodename_@Signame";
BA_DEF_DEF_  "SPN" 0;
BA_DEF_DEF_  "TpJ1939VarDlc" "No";
BA_DEF_DEF_  "GenMsgStartDelayTime" 0;
BA_DEF_DEF_  "GenMsgILSupport" "Yes";
BA_DEF_DEF_  "GenMsgDelayTime" 0;
BA_DEF_DEF_  "GenMsgRequestable" 1;
BA_DEF_DEF_  "GenMsgSendType" "noMsgSendType";
BA_DEF_DEF_  "VFrameFormat" "J1939PG";
BA_DEF_DEF_  "GenMsgCycleTime" 0;
BA_DEF_DEF_  "SystemSignalLongSymbol" "";
BA_ "GenMsgSendType" BO_ 2566722302 0;
BA_ "GenMsgCycleTime" BO_ 2566722302 500;
BA_ "GenMsgDelayTime" BO_ 2560032510 500;
BA_ "GenMsgSendType" BO_ 2566717950 0;
BA_ "GenMsgCycleTime" BO_ 2566717950 500;
BA_ "GenMsgSendType" BO_ 2499604222 0;
BA_ "GenMsgCycleTime" BO_ 2499604222 200;
BA_ "GenMsgSendType" BO_ 2358902526 0;
BA_ "GenMsgCycleTime" BO_ 2358902526 100;
BA_ "GenMsgSendType" BO_ 2566711550 0;
BA_ "GenMsgCycleTime" BO_ 2566711550 500;
BA_ "GenMsgSendType" BO_ 2566719998 0;
BA_ "GenMsgCycleTime" BO_ 2566719998 1000;
BA_ "GenMsgSendType" BO_ 2566713854 0;
BA_ "GenMsgCycleTime" BO_ 2566713854 100;
BA_ "GenMsgSendType" BO_ 2566714366 0;
BA_ "GenMsgCycleTime" BO_ 2566714366 100;
BA_ "GenMsgSendType" BO_ 2566714110 0;
BA_ "GenMsgCycleTime" BO_ 2566714110 100;
BA_ "GenMsgSendType" BO_ 2566717438 0;
BA_ "GenMsgCycleTime" BO_ 2566717438 1000;
BA_ "GenMsgSendType" BO_ 2633828606 0;
BA_ "GenMsgCycleTime" BO_ 2633828606 30000;
BA_ "GenMsgDelayTime" BO_ 2365400574 20;
BA_ "GenMsgSendType" BO_ 2365400574 0;
BA_ "GenMsgCycleTime" BO_ 2365400574 100;
BA_ "GenMsgDelayTime" BO_ 2365401086 20;
BA_ "GenMsgSendType" BO_ 2365401086 0;
BA_ "GenMsgCycleTime" BO_ 2365401086 100;
BA_ "GenMsgDelayTime" BO_ 2365401598 20;
BA_ "GenMsgSendType" BO_ 2365401598 0;
BA_ "GenMsgCycleTime" BO_ 2365401598 100;
BA_ "GenMsgDelayTime" BO_ 2365402110 20;
BA_ "GenMsgSendType" BO_ 2365402110 0;
BA_ "GenMsgCycleTime" BO_ 2365402110 100;
BA_ "GenMsgDelayTime" BO_ 2365402622 20;
BA_ "GenMsgSendType" BO_ 2365402622 0;
BA_ "GenMsgCycleTime" BO_ 2365402622 100;
BA_ "GenMsgDelayTime" BO_ 2365403134 20;
BA_ "GenMsgSendType" BO_ 2365403134 0;
BA_ "GenMsgCycleTime" BO_ 2365403134 100;
BA_ "GenMsgDelayTime" BO_ 2365400062 20;
BA_ "GenMsgSendType" BO_ 2365400062 0;
BA_ "GenMsgCycleTime" BO_ 2365400062 100;
BA_ "GenMsgSendType" BO_ 2566713598 0;
BA_ "GenMsgCycleTime" BO_ 2566713598 500;
BA_ "GenMsgSendType" BO_ 2499604478 0;
BA_ "GenMsgCycleTime" BO_ 2499604478 500;
BA_ "GenMsgSendType" BO_ 2499608830 0;
BA_ "GenMsgCycleTime" BO_ 2499608830 500;
BA_ "GenMsgSendType" BO_ 2432499198 0;
BA_ "GenMsgCycleTime" BO_ 2432499198 100;
BA_ "GenMsgDelayTime" BO_ 2566711294 500;
BA_ "GenMsgSendType" BO_ 2566711294 0;
BA_ "GenMsgCycleTime" BO_ 2566711294 5000;
BA_ "GenMsgDelayTime" BO_ 2566749438 100;
BA_ "GenMsgSendType" BO_ 2566749438 0;
BA_ "GenMsgCycleTime" BO_ 2566749438 1000;
BA_ "GenMsgSendType" BO_ 2566715646 0;
BA_ "GenMsgCycleTime" BO_ 2566715646 1000;
BA_ "GenMsgSendType" BO_ 2566724606 0;
BA_ "GenMsgCycleTime" BO_ 2566724606 1000;
BA_ "GenMsgSendType" BO_ 2566715902 0;
BA_ "GenMsgCycleTime" BO_ 2566715902 1000;
BA_ "GenMsgSendType" BO_ 2566724862 0;
BA_ "GenMsgCycleTime" BO_ 2566724862 1000;
BA_ "GenMsgSendType" BO_ 2566718718 0;
BA_ "GenMsgCycleTime" BO_ 2566718718 1000;
BA_ "GenMsgSendType" BO_ 2566718974 0;
BA_ "GenMsgCycleTime" BO_ 2566718974 1000;
BA_ "GenMsgDelayTime" BO_ 2566719230 100;
BA_ "GenMsgSendType" BO_ 2566719230 0;
BA_ "GenMsgCycleTime" BO_ 2566719230 1000;
BA_ "TpJ1939VarDlc" BO_ 2560818942 1;
BA_ "SigType" SG_ 2566722302 GeneratorDutyCycleExceededStatus 5;
BA_ "SPN" SG_ 2566722302 GeneratorDutyCycleExceededStatus 5007;
BA_ "SigType" SG_ 2566722302 VoltageMonitorActiveStatus 5;
BA_ "SPN" SG_ 2566722302 VoltageMonitorActiveStatus 5006;
BA_ "SigType" SG_ 2566722302 GensetEnableActiveStatus 5;
BA_ "SPN" SG_ 2566722302 GensetEnableActiveStatus 5005;
BA_ "SPN" SG_ 2566722302 ReverseCurrentRangeSetting 5002;
BA_ "SigType" SG_ 2566722302 GensetSoftstartActiveStatus 5;
BA_ "SPN" SG_ 2566722302 GensetSoftstartActiveStatus 5004;
BA_ "SigType" SG_ 2566722302 Grapple_MagnetSelectionSwitch 5;
BA_ "SPN" SG_ 2566722302 Grapple_MagnetSelectionSwitch 5003;
BA_ "SigType" SG_ 2566722302 GnstSystmOtputVoltageRangeStatus 5;
BA_ "SPN" SG_ 2566722302 GnstSystmOtputVoltageRangeStatus 5001;
BA_ "SigType" SG_ 2566722302 GeneratorOverheatStatus 5;
BA_ "SPN" SG_ 2566722302 GeneratorOverheatStatus 5000;
BA_ "SigType" SG_ 2566722558 MagnetRatedPower 1;
BA_ "SPN" SG_ 2566722558 MagnetRatedPower 4999;
BA_ "SigType" SG_ 2566722558 MagnetBoostTime 1;
BA_ "SPN" SG_ 2566722558 MagnetBoostTime 4998;
BA_ "SPN" SG_ 2560032510 LwVltgDscnnctDsiredOperatingMode 5149;
BA_ "SigType" SG_ 2566717950 LowVoltageDisconnectTemp 1;
BA_ "SPN" SG_ 2566717950 LowVoltageDisconnectTemp 5148;
BA_ "SPN" SG_ 2566717950 LwVltgeDisconnectVoutOutputState 5147;
BA_ "SPN" SG_ 2566717950 LowVoltageDisconnectOutput1State 5146;
BA_ "SPN" SG_ 2566717950 LowVoltageDisconnectOutput2State 5145;
BA_ "SPN" SG_ 2566717950 LowVoltageDisconnectOutput3State 5144;
BA_ "SPN" SG_ 2566717950 LwVltgDscnnctCrrentOperatingMode 5143;
BA_ "SigType" SG_ 2566717950 LwVltgDscnnectManualConnectState 4;
BA_ "SPN" SG_ 2566717950 LwVltgDscnnectManualConnectState 5142;
BA_ "SigType" SG_ 2566717950 LwVltgDscnnctMnalDisconnectState 4;
BA_ "SPN" SG_ 2566717950 LwVltgDscnnctMnalDisconnectState 5141;
BA_ "SigType" SG_ 2499604222 BldReferenceElevationOffsetRight 1;
BA_ "SPN" SG_ 2499604222 BldReferenceElevationOffsetRight 5413;
BA_ "SigType" SG_ 2499604222 BldeReferenceElevationOffsetLeft 1;
BA_ "SPN" SG_ 2499604222 BldeReferenceElevationOffsetLeft 5412;
BA_ "SigType" SG_ 2499604222 BladeElevationDeviationRight 1;
BA_ "SPN" SG_ 2499604222 BladeElevationDeviationRight 5411;
BA_ "SigType" SG_ 2499604222 BladeElevationDeviationLeft 1;
BA_ "SPN" SG_ 2499604222 BladeElevationDeviationLeft 5410;
BA_ "SigType" SG_ 2358902526 Joystick3Lamp10Cmd 5;
BA_ "SPN" SG_ 2358902526 Joystick3Lamp10Cmd 4489;
BA_ "SigType" SG_ 2358902526 Joystick3Lamp9Cmd 5;
BA_ "SPN" SG_ 2358902526 Joystick3Lamp9Cmd 4488;
BA_ "SigType" SG_ 2358902526 Joystick3Lamp8Cmd 5;
BA_ "SPN" SG_ 2358902526 Joystick3Lamp8Cmd 4487;
BA_ "SigType" SG_ 2358902526 Joystick3Lamp7Cmd 5;
BA_ "SPN" SG_ 2358902526 Joystick3Lamp7Cmd 4486;
BA_ "SigType" SG_ 2358902526 Joystick3Lamp6Cmd 5;
BA_ "SPN" SG_ 2358902526 Joystick3Lamp6Cmd 4485;
BA_ "SigType" SG_ 2358902526 Joystick3Lamp5Cmd 5;
BA_ "SPN" SG_ 2358902526 Joystick3Lamp5Cmd 4484;
BA_ "SigType" SG_ 2358902526 Joystick3Lamp4Cmd 5;
BA_ "SPN" SG_ 2358902526 Joystick3Lamp4Cmd 4483;
BA_ "SigType" SG_ 2358902526 Joystick3Lamp3Cmd 5;
BA_ "SPN" SG_ 2358902526 Joystick3Lamp3Cmd 4482;
BA_ "SigType" SG_ 2358902526 Joystick3Lamp2Cmd 5;
BA_ "SPN" SG_ 2358902526 Joystick3Lamp2Cmd 4481;
BA_ "SigType" SG_ 2358902526 Joystick3Lamp1Cmd 5;
BA_ "SPN" SG_ 2358902526 Joystick3Lamp1Cmd 4480;
BA_ "SigType" SG_ 2358902526 Joystick2Lamp10Cmd 5;
BA_ "SPN" SG_ 2358902526 Joystick2Lamp10Cmd 4479;
BA_ "SigType" SG_ 2358902526 Joystick2Lamp9Cmd 5;
BA_ "SPN" SG_ 2358902526 Joystick2Lamp9Cmd 4478;
BA_ "SigType" SG_ 2358902526 Joystick2Lamp8Cmd 5;
BA_ "SPN" SG_ 2358902526 Joystick2Lamp8Cmd 4477;
BA_ "SigType" SG_ 2358902526 Joystick2Lamp7Cmd 5;
BA_ "SPN" SG_ 2358902526 Joystick2Lamp7Cmd 4476;
BA_ "SigType" SG_ 2358902526 Joystick2Lamp6Cmd 5;
BA_ "SPN" SG_ 2358902526 Joystick2Lamp6Cmd 4475;
BA_ "SigType" SG_ 2358902526 Joystick2Lamp5Cmd 5;
BA_ "SPN" SG_ 2358902526 Joystick2Lamp5Cmd 4474;
BA_ "SigType" SG_ 2358902526 Joystick2Lamp4Cmd 5;
BA_ "SPN" SG_ 2358902526 Joystick2Lamp4Cmd 4473;
BA_ "SigType" SG_ 2358902526 Joystick2Lamp3Cmd 5;
BA_ "SPN" SG_ 2358902526 Joystick2Lamp3Cmd 4472;
BA_ "SigType" SG_ 2358902526 Joystick2Lamp2Cmd 5;
BA_ "SPN" SG_ 2358902526 Joystick2Lamp2Cmd 4471;
BA_ "SigType" SG_ 2358902526 Joystick2Lamp1Cmd 5;
BA_ "SPN" SG_ 2358902526 Joystick2Lamp1Cmd 4470;
BA_ "SigType" SG_ 2358902526 Joystick1Lamp10Cmd 5;
BA_ "SPN" SG_ 2358902526 Joystick1Lamp10Cmd 4469;
BA_ "SigType" SG_ 2358902526 Joystick1Lamp9Cmd 5;
BA_ "SPN" SG_ 2358902526 Joystick1Lamp9Cmd 4468;
BA_ "SigType" SG_ 2358902526 Joystick1Lamp8Cmd 5;
BA_ "SPN" SG_ 2358902526 Joystick1Lamp8Cmd 4467;
BA_ "SigType" SG_ 2358902526 Joystick1Lamp7Cmd 5;
BA_ "SPN" SG_ 2358902526 Joystick1Lamp7Cmd 4466;
BA_ "SigType" SG_ 2358902526 Joystick1Lamp6Cmd 5;
BA_ "SPN" SG_ 2358902526 Joystick1Lamp6Cmd 4465;
BA_ "SigType" SG_ 2358902526 Joystick1Lamp5Cmd 5;
BA_ "SPN" SG_ 2358902526 Joystick1Lamp5Cmd 4464;
BA_ "SigType" SG_ 2358902526 Joystick1Lamp4Cmd 5;
BA_ "SPN" SG_ 2358902526 Joystick1Lamp4Cmd 4463;
BA_ "SigType" SG_ 2358902526 Joystick1Lamp3Cmd 5;
BA_ "SPN" SG_ 2358902526 Joystick1Lamp3Cmd 4462;
BA_ "SigType" SG_ 2358902526 Joystick1Lamp2Cmd 5;
BA_ "SPN" SG_ 2358902526 Joystick1Lamp2Cmd 4461;
BA_ "SigType" SG_ 2358902526 Joystick1Lamp1Cmd 5;
BA_ "SPN" SG_ 2358902526 Joystick1Lamp1Cmd 4460;
BA_ "SigType" SG_ 2566711550 IntkVlvActtnSystmOlPrss2SlndCtrl 5;
BA_ "SPN" SG_ 2566711550 IntkVlvActtnSystmOlPrss2SlndCtrl 5500;
BA_ "SigType" SG_ 2566711550 IntkVlvActtnSystmOlPrss1SlndCtrl 5;
BA_ "SPN" SG_ 2566711550 IntkVlvActtnSystmOlPrss1SlndCtrl 5499;
BA_ "SigType" SG_ 2566719998 HighResolutionEngTotalFuelUsed 1;
BA_ "SPN" SG_ 2566719998 HighResolutionEngTotalFuelUsed 5054;
BA_ "SigType" SG_ 2566719998 HighResolutionEngTripFuel 1;
BA_ "SPN" SG_ 2566719998 HighResolutionEngTripFuel 5053;
BA_ "SigType" SG_ 2565877502 EngTrbCmprssrBlowoffActuator1Cmd 1;
BA_ "SPN" SG_ 2565877502 EngTrbCmprssrBlowoffActuator1Cmd 6201;
BA_ "SigType" SG_ 2565877502 EngExhstBckPressRegulatorCtrlCmd 1;
BA_ "SPN" SG_ 2565877502 EngExhstBckPressRegulatorCtrlCmd 649;
BA_ "SigType" SG_ 2565877502 EngTurboWastegateActuator2Cmd 1;
BA_ "SPN" SG_ 2565877502 EngTurboWastegateActuator2Cmd 5387;
BA_ "SigType" SG_ 2565877502 EngTurboWastegateActuator1Cmd 1;
BA_ "SPN" SG_ 2565877502 EngTurboWastegateActuator1Cmd 5386;
BA_ "SigType" SG_ 2566713854 EngExhaustBackPressActuator1Temp 1;
BA_ "SPN" SG_ 2566713854 EngExhaustBackPressActuator1Temp 5790;
BA_ "SigType" SG_ 2566713854 EngExhstBckPrssActtor1DesiredPos 1;
BA_ "SPN" SG_ 2566713854 EngExhstBckPrssActtor1DesiredPos 5789;
BA_ "SigType" SG_ 2566713854 EngTurboWastegateActuator1Temp 1;
BA_ "SPN" SG_ 2566713854 EngTurboWastegateActuator1Temp 5788;
BA_ "SPN" SG_ 2566713854 EngExhstBckPrssRgltrCtrlOprtnStt 5628;
BA_ "SPN" SG_ 2566713854 EngExhstBckPrssRglatorTempStatus 5627;
BA_ "SPN" SG_ 2566713854 EngExhstBckPrssRgltrPrlminaryFMI 5626;
BA_ "SigType" SG_ 2566713854 EngExhaustBackPressRegulatorPos 1;
BA_ "SPN" SG_ 2566713854 EngExhaustBackPressRegulatorPos 5625;
BA_ "SPN" SG_ 2566713854 EngTrbWstgtActtr2OperationStatus 5452;
BA_ "SPN" SG_ 2566713854 EngTrbWstgtActtr1OperationStatus 5451;
BA_ "SPN" SG_ 2566713854 EngTrbWstgateActuator2TempStatus 5385;
BA_ "SPN" SG_ 2566713854 EngTrbWstgtActtor2PreliminaryFMI 5384;
BA_ "SigType" SG_ 2566714366 EngTrbCmprssrBypassActuator2Temp 1;
BA_ "SPN" SG_ 2566714366 EngTrbCmprssrBypassActuator2Temp 5792;
BA_ "SigType" SG_ 2566714366 EngTrbCmprssrBypassActuator1Temp 1;
BA_ "SPN" SG_ 2566714366 EngTrbCmprssrBypassActuator1Temp 5791;
BA_ "SPN" SG_ 2566714366 EngTrbCmprssrBypssActtr2OprtnStt 5450;
BA_ "SPN" SG_ 2566714366 EngTrbCmprssrBypssActtr1OprtnStt 5449;
BA_ "SPN" SG_ 2566714366 EngTrbCmprssrBypssActtr2TmpSttus 5391;
BA_ "SPN" SG_ 2566714366 EngTrbCmprssrBypssActtr2PrlmnryF 5390;
BA_ "SigType" SG_ 2566714366 EngDsrdTrbCmprssrBypssActtor2Pos 1;
BA_ "SPN" SG_ 2566714366 EngDsrdTrbCmprssrBypssActtor2Pos 5389;
BA_ "SigType" SG_ 2566714366 EngTrbCmprssorBypassActuator2Pos 1;
BA_ "SPN" SG_ 2566714366 EngTrbCmprssorBypassActuator2Pos 5388;
BA_ "SPN" SG_ 2566714110 EngFuelValve2OperationStatus 5448;
BA_ "SPN" SG_ 2566714110 EngFuelValve1OperationStatus 5447;
BA_ "SPN" SG_ 2566714110 EngThrottleValve2OperationStatus 5446;
BA_ "SPN" SG_ 2566714110 EngThrottleValve1OperationStatus 5445;
BA_ "SPN" SG_ 2566714110 EngFuelValve2TempStatus 5383;
BA_ "SPN" SG_ 2566714110 EngFuelValve2PreliminaryFMI 5382;
BA_ "SPN" SG_ 2566714110 EngFuelValve1TempStatus 5381;
BA_ "SPN" SG_ 2566714110 EngFuelValve1PreliminaryFMI 5380;
BA_ "SPN" SG_ 2566714110 EngThrottleValve2TempStatus 5379;
BA_ "SPN" SG_ 2566714110 EngThrottleValve2PreliminaryFMI 5378;
BA_ "SigType" SG_ 2566714110 EngDesiredThrottleValve2Pos 1;
BA_ "SPN" SG_ 2566714110 EngDesiredThrottleValve2Pos 5377;
BA_ "SPN" SG_ 2566714110 EngThrottleValve1TempStatus 5376;
BA_ "SPN" SG_ 2566714110 EngThrottleValve1PreliminaryFMI 5375;
BA_ "SigType" SG_ 2566714110 EngDesiredThrottleValve1Pos 1;
BA_ "SPN" SG_ 2566714110 EngDesiredThrottleValve1Pos 5374;
BA_ "SigType" SG_ 2566717438 EngExhstGsRcrcltn2MxerIntakeTemp 1;
BA_ "SPN" SG_ 2566717438 EngExhstGsRcrcltn2MxerIntakeTemp 5256;
BA_ "SigType" SG_ 2566717438 EngExhaustGasRecirculation2Temp 1;
BA_ "SPN" SG_ 2566717438 EngExhaustGasRecirculation2Temp 5255;
BA_ "SigType" SG_ 2633828606 EngOilTemp3 1;
BA_ "SPN" SG_ 2633828606 EngOilTemp3 5925;
BA_ "SigType" SG_ 2633828606 EngOilRelativeDielectricity 1;
BA_ "SPN" SG_ 2633828606 EngOilRelativeDielectricity 5468;
BA_ "SigType" SG_ 2633828606 EngOilDensity 1;
BA_ "SPN" SG_ 2633828606 EngOilDensity 5056;
BA_ "SigType" SG_ 2633828606 EngOilViscosity 1;
BA_ "SPN" SG_ 2633828606 EngOilViscosity 5055;
BA_ "SigType" SG_ 2499607550 EngExhstMnfldBnk2FlwBlncVlvActtr 1;
BA_ "SPN" SG_ 2499607550 EngExhstMnfldBnk2FlwBlncVlvActtr 5279;
BA_ "SigType" SG_ 2499607550 EngExhstMnfldBnk1FlwBlncVlvActtr 1;
BA_ "SPN" SG_ 2499607550 EngExhstMnfldBnk1FlwBlncVlvActtr 5277;
BA_ "SigType" SG_ 2633825534 EngExhstMnfldBnk2FlwBlncVlvActtr 1;
BA_ "SPN" SG_ 2633825534 EngExhstMnfldBnk2FlwBlncVlvActtr 5278;
BA_ "SigType" SG_ 2633825534 EngExhstMnfldBnk1FlwBlncVlvActtr 1;
BA_ "SPN" SG_ 2633825534 EngExhstMnfldBnk1FlwBlncVlvActtr 5276;
BA_ "SigType" SG_ 2365400574 Joystick9Button13PressedStatus 4;
BA_ "SPN" SG_ 2365400574 Joystick9Button13PressedStatus 6763;
BA_ "SigType" SG_ 2365400574 Joystick9Button14PressedStatus 4;
BA_ "SPN" SG_ 2365400574 Joystick9Button14PressedStatus 6764;
BA_ "SigType" SG_ 2365400574 Joystick9Button15PressedStatus 4;
BA_ "SPN" SG_ 2365400574 Joystick9Button15PressedStatus 6765;
BA_ "SigType" SG_ 2365400574 Joystick9Button16PressedStatus 4;
BA_ "SPN" SG_ 2365400574 Joystick9Button16PressedStatus 6766;
BA_ "SigType" SG_ 2365400574 Jystick9GripXAxisDetentPosStatus 4;
BA_ "SPN" SG_ 2365400574 Jystick9GripXAxisDetentPosStatus 4712;
BA_ "SigType" SG_ 2365400574 Jystick9GripYAxisDetentPosStatus 4;
BA_ "SPN" SG_ 2365400574 Jystick9GripYAxisDetentPosStatus 4711;
BA_ "SigType" SG_ 2365400574 Jystick9ThetaAxisDetentPosStatus 4;
BA_ "SPN" SG_ 2365400574 Jystick9ThetaAxisDetentPosStatus 4710;
BA_ "SPN" SG_ 2365400574 Joystick9ThetaAxisPos 4709;
BA_ "SigType" SG_ 2365400574 Jystck9ThtAxsClckwsPstvPosStatus 4;
BA_ "SPN" SG_ 2365400574 Jystck9ThtAxsClckwsPstvPosStatus 4708;
BA_ "SigType" SG_ 2365400574 Jystck9ThtAxsCntrClckwsNgtvPsStt 4;
BA_ "SPN" SG_ 2365400574 Jystck9ThtAxsCntrClckwsNgtvPsStt 4707;
BA_ "SigType" SG_ 2365400574 Jystck9ThetaAxisNeutralPosStatus 4;
BA_ "SPN" SG_ 2365400574 Jystck9ThetaAxisNeutralPosStatus 4706;
BA_ "SPN" SG_ 2365400574 Joystick9GripYAxisPos 4705;
BA_ "SigType" SG_ 2365400574 Jystck9GrpYAxsLvrFrwrdPstvPsStts 4;
BA_ "SPN" SG_ 2365400574 Jystck9GrpYAxsLvrFrwrdPstvPsStts 4704;
BA_ "SigType" SG_ 2365400574 Jystck9GrpYAxsLvrBckNgtvPsStatus 4;
BA_ "SPN" SG_ 2365400574 Jystck9GrpYAxsLvrBckNgtvPsStatus 4703;
BA_ "SigType" SG_ 2365400574 Jystck9GripYAxisNeutralPosStatus 4;
BA_ "SPN" SG_ 2365400574 Jystck9GripYAxisNeutralPosStatus 4702;
BA_ "SPN" SG_ 2365400574 Joystick9GripXAxisPos 4701;
BA_ "SigType" SG_ 2365400574 Jystck9GrpXAxsLvrRghtPstvPsSttus 4;
BA_ "SPN" SG_ 2365400574 Jystck9GrpXAxsLvrRghtPstvPsSttus 4700;
BA_ "SigType" SG_ 2365400574 Jystck9GrpXAxsLvrLftNgtvPsStatus 4;
BA_ "SPN" SG_ 2365400574 Jystck9GrpXAxsLvrLftNgtvPsStatus 4699;
BA_ "SigType" SG_ 2365400574 Jystck9GripXAxisNeutralPosStatus 4;
BA_ "SPN" SG_ 2365400574 Jystck9GripXAxisNeutralPosStatus 4698;
BA_ "SigType" SG_ 2365401086 Joystick8Button13PressedStatus 4;
BA_ "SPN" SG_ 2365401086 Joystick8Button13PressedStatus 6759;
BA_ "SigType" SG_ 2365401086 Joystick8Button14PressedStatus 4;
BA_ "SPN" SG_ 2365401086 Joystick8Button14PressedStatus 6760;
BA_ "SigType" SG_ 2365401086 Joystick8Button15PressedStatus 4;
BA_ "SPN" SG_ 2365401086 Joystick8Button15PressedStatus 6761;
BA_ "SigType" SG_ 2365401086 Joystick8Button16PressedStatus 4;
BA_ "SPN" SG_ 2365401086 Joystick8Button16PressedStatus 6762;
BA_ "SigType" SG_ 2365401086 Jystick8GripXAxisDetentPosStatus 4;
BA_ "SPN" SG_ 2365401086 Jystick8GripXAxisDetentPosStatus 4675;
BA_ "SigType" SG_ 2365401086 Jystick8GripYAxisDetentPosStatus 4;
BA_ "SPN" SG_ 2365401086 Jystick8GripYAxisDetentPosStatus 4674;
BA_ "SigType" SG_ 2365401086 Jystick8ThetaAxisDetentPosStatus 4;
BA_ "SPN" SG_ 2365401086 Jystick8ThetaAxisDetentPosStatus 4673;
BA_ "SPN" SG_ 2365401086 Joystick8ThetaAxisPos 4672;
BA_ "SigType" SG_ 2365401086 Jystck8ThtAxsClckwsPstvPosStatus 4;
BA_ "SPN" SG_ 2365401086 Jystck8ThtAxsClckwsPstvPosStatus 4671;
BA_ "SigType" SG_ 2365401086 Jystck8ThtAxsCntrClckwsNgtvPsStt 4;
BA_ "SPN" SG_ 2365401086 Jystck8ThtAxsCntrClckwsNgtvPsStt 4670;
BA_ "SigType" SG_ 2365401086 Jystck8ThetaAxisNeutralPosStatus 4;
BA_ "SPN" SG_ 2365401086 Jystck8ThetaAxisNeutralPosStatus 4669;
BA_ "SPN" SG_ 2365401086 Joystick8GripYAxisPos 4668;
BA_ "SigType" SG_ 2365401086 Jystck8GrpYAxsLvrFrwrdPstvPsStts 4;
BA_ "SPN" SG_ 2365401086 Jystck8GrpYAxsLvrFrwrdPstvPsStts 4667;
BA_ "SigType" SG_ 2365401086 Jystck8GrpYAxsLvrBckNgtvPsStatus 4;
BA_ "SPN" SG_ 2365401086 Jystck8GrpYAxsLvrBckNgtvPsStatus 4666;
BA_ "SigType" SG_ 2365401086 Jystck8GripYAxisNeutralPosStatus 4;
BA_ "SPN" SG_ 2365401086 Jystck8GripYAxisNeutralPosStatus 4665;
BA_ "SPN" SG_ 2365401086 Joystick8GripXAxisPos 4664;
BA_ "SigType" SG_ 2365401086 Jystck8GrpXAxsLvrRghtPstvPsSttus 4;
BA_ "SPN" SG_ 2365401086 Jystck8GrpXAxsLvrRghtPstvPsSttus 4663;
BA_ "SigType" SG_ 2365401086 Jystck8GrpXAxsLvrLftNgtvPsStatus 4;
BA_ "SPN" SG_ 2365401086 Jystck8GrpXAxsLvrLftNgtvPsStatus 4662;
BA_ "SigType" SG_ 2365401086 Jystck8GripXAxisNeutralPosStatus 4;
BA_ "SPN" SG_ 2365401086 Jystck8GripXAxisNeutralPosStatus 4661;
BA_ "SigType" SG_ 2365401598 Joystick7Button13PressedStatus 4;
BA_ "SPN" SG_ 2365401598 Joystick7Button13PressedStatus 6755;
BA_ "SigType" SG_ 2365401598 Joystick7Button14PressedStatus 4;
BA_ "SPN" SG_ 2365401598 Joystick7Button14PressedStatus 6756;
BA_ "SigType" SG_ 2365401598 Joystick7Button15PressedStatus 4;
BA_ "SPN" SG_ 2365401598 Joystick7Button15PressedStatus 6757;
BA_ "SigType" SG_ 2365401598 Joystick7Button16PressedStatus 4;
BA_ "SPN" SG_ 2365401598 Joystick7Button16PressedStatus 6758;
BA_ "SigType" SG_ 2365401598 Jystick7GripXAxisDetentPosStatus 4;
BA_ "SPN" SG_ 2365401598 Jystick7GripXAxisDetentPosStatus 4638;
BA_ "SigType" SG_ 2365401598 Jystick7GripYAxisDetentPosStatus 4;
BA_ "SPN" SG_ 2365401598 Jystick7GripYAxisDetentPosStatus 4637;
BA_ "SigType" SG_ 2365401598 Jystick7ThetaAxisDetentPosStatus 4;
BA_ "SPN" SG_ 2365401598 Jystick7ThetaAxisDetentPosStatus 4636;
BA_ "SPN" SG_ 2365401598 Joystick7ThetaAxisPos 4635;
BA_ "SigType" SG_ 2365401598 Jystck7ThtAxsClckwsPstvPosStatus 4;
BA_ "SPN" SG_ 2365401598 Jystck7ThtAxsClckwsPstvPosStatus 4634;
BA_ "SigType" SG_ 2365401598 Jystck7ThtAxsCntrClckwsNgtvPsStt 4;
BA_ "SPN" SG_ 2365401598 Jystck7ThtAxsCntrClckwsNgtvPsStt 4633;
BA_ "SigType" SG_ 2365401598 Jystck7ThetaAxisNeutralPosStatus 4;
BA_ "SPN" SG_ 2365401598 Jystck7ThetaAxisNeutralPosStatus 4632;
BA_ "SPN" SG_ 2365401598 Joystick7GripYAxisPos 4631;
BA_ "SigType" SG_ 2365401598 Jystck7GrpYAxsLvrFrwrdPstvPsStts 4;
BA_ "SPN" SG_ 2365401598 Jystck7GrpYAxsLvrFrwrdPstvPsStts 4630;
BA_ "SigType" SG_ 2365401598 Jystck7GrpYAxsLvrBckNgtvPsStatus 4;
BA_ "SPN" SG_ 2365401598 Jystck7GrpYAxsLvrBckNgtvPsStatus 4629;
BA_ "SigType" SG_ 2365401598 Jystck7GripYAxisNeutralPosStatus 4;
BA_ "SPN" SG_ 2365401598 Jystck7GripYAxisNeutralPosStatus 4628;
BA_ "SPN" SG_ 2365401598 Joystick7GripXAxisPos 4627;
BA_ "SigType" SG_ 2365401598 Jystck7GrpXAxsLvrRghtPstvPsSttus 4;
BA_ "SPN" SG_ 2365401598 Jystck7GrpXAxsLvrRghtPstvPsSttus 4626;
BA_ "SigType" SG_ 2365401598 Jystck7GrpXAxsLvrLftNgtvPsStatus 4;
BA_ "SPN" SG_ 2365401598 Jystck7GrpXAxsLvrLftNgtvPsStatus 4625;
BA_ "SigType" SG_ 2365401598 Jystck7GripXAxisNeutralPosStatus 4;
BA_ "SPN" SG_ 2365401598 Jystck7GripXAxisNeutralPosStatus 4624;
BA_ "SigType" SG_ 2365402110 Joystick6Button13PressedStatus 4;
BA_ "SPN" SG_ 2365402110 Joystick6Button13PressedStatus 6751;
BA_ "SigType" SG_ 2365402110 Joystick6Button14PressedStatus 4;
BA_ "SPN" SG_ 2365402110 Joystick6Button14PressedStatus 6752;
BA_ "SigType" SG_ 2365402110 Joystick6Button15PressedStatus 4;
BA_ "SPN" SG_ 2365402110 Joystick6Button15PressedStatus 6753;
BA_ "SigType" SG_ 2365402110 Joystick6Button16PressedStatus 4;
BA_ "SPN" SG_ 2365402110 Joystick6Button16PressedStatus 6754;
BA_ "SigType" SG_ 2365402110 Jystick6GripXAxisDetentPosStatus 4;
BA_ "SPN" SG_ 2365402110 Jystick6GripXAxisDetentPosStatus 4601;
BA_ "SigType" SG_ 2365402110 Jystick6GripYAxisDetentPosStatus 4;
BA_ "SPN" SG_ 2365402110 Jystick6GripYAxisDetentPosStatus 4600;
BA_ "SigType" SG_ 2365402110 Jystick6ThetaAxisDetentPosStatus 4;
BA_ "SPN" SG_ 2365402110 Jystick6ThetaAxisDetentPosStatus 4599;
BA_ "SPN" SG_ 2365402110 Joystick6ThetaAxisPos 4598;
BA_ "SigType" SG_ 2365402110 Jystck6ThtAxsClckwsPstvPosStatus 4;
BA_ "SPN" SG_ 2365402110 Jystck6ThtAxsClckwsPstvPosStatus 4597;
BA_ "SigType" SG_ 2365402110 Jystck6ThtAxsCntrClckwsNgtvPsStt 4;
BA_ "SPN" SG_ 2365402110 Jystck6ThtAxsCntrClckwsNgtvPsStt 4596;
BA_ "SigType" SG_ 2365402110 Jystck6ThetaAxisNeutralPosStatus 4;
BA_ "SPN" SG_ 2365402110 Jystck6ThetaAxisNeutralPosStatus 4595;
BA_ "SPN" SG_ 2365402110 Joystick6GripYAxisPos 4594;
BA_ "SigType" SG_ 2365402110 Jystck6GrpYAxsLvrFrwrdPstvPsStts 4;
BA_ "SPN" SG_ 2365402110 Jystck6GrpYAxsLvrFrwrdPstvPsStts 4593;
BA_ "SigType" SG_ 2365402110 Jystck6GrpYAxsLvrBckNgtvPsStatus 4;
BA_ "SPN" SG_ 2365402110 Jystck6GrpYAxsLvrBckNgtvPsStatus 4592;
BA_ "SigType" SG_ 2365402110 Jystck6GripYAxisNeutralPosStatus 4;
BA_ "SPN" SG_ 2365402110 Jystck6GripYAxisNeutralPosStatus 4591;
BA_ "SPN" SG_ 2365402110 Joystick6GripXAxisPos 4590;
BA_ "SigType" SG_ 2365402110 Jystck6GrpXAxsLvrRghtPstvPsSttus 4;
BA_ "SPN" SG_ 2365402110 Jystck6GrpXAxsLvrRghtPstvPsSttus 4589;
BA_ "SigType" SG_ 2365402110 Jystck6GrpXAxsLvrLftNgtvPsStatus 4;
BA_ "SPN" SG_ 2365402110 Jystck6GrpXAxsLvrLftNgtvPsStatus 4588;
BA_ "SigType" SG_ 2365402110 Jystck6GripXAxisNeutralPosStatus 4;
BA_ "SPN" SG_ 2365402110 Jystck6GripXAxisNeutralPosStatus 4587;
BA_ "SigType" SG_ 2365402622 Joystick5Button13PressedStatus 4;
BA_ "SPN" SG_ 2365402622 Joystick5Button13PressedStatus 6747;
BA_ "SigType" SG_ 2365402622 Joystick5Button14PressedStatus 4;
BA_ "SPN" SG_ 2365402622 Joystick5Button14PressedStatus 6748;
BA_ "SigType" SG_ 2365402622 Joystick5Button15PressedStatus 4;
BA_ "SPN" SG_ 2365402622 Joystick5Button15PressedStatus 6749;
BA_ "SigType" SG_ 2365402622 Joystick5Button16PressedStatus 4;
BA_ "SPN" SG_ 2365402622 Joystick5Button16PressedStatus 6750;
BA_ "SigType" SG_ 2365402622 Jystick5GripXAxisDetentPosStatus 4;
BA_ "SPN" SG_ 2365402622 Jystick5GripXAxisDetentPosStatus 4564;
BA_ "SigType" SG_ 2365402622 Jystick5GripYAxisDetentPosStatus 4;
BA_ "SPN" SG_ 2365402622 Jystick5GripYAxisDetentPosStatus 4563;
BA_ "SigType" SG_ 2365402622 Jystick5ThetaAxisDetentPosStatus 4;
BA_ "SPN" SG_ 2365402622 Jystick5ThetaAxisDetentPosStatus 4562;
BA_ "SPN" SG_ 2365402622 Joystick5ThetaAxisPos 4561;
BA_ "SigType" SG_ 2365402622 Jystck5ThtAxsClckwsPstvPosStatus 4;
BA_ "SPN" SG_ 2365402622 Jystck5ThtAxsClckwsPstvPosStatus 4560;
BA_ "SigType" SG_ 2365402622 Jystck5ThtAxsCntrClckwsNgtvPsStt 4;
BA_ "SPN" SG_ 2365402622 Jystck5ThtAxsCntrClckwsNgtvPsStt 4559;
BA_ "SigType" SG_ 2365402622 Jystck5ThetaAxisNeutralPosStatus 4;
BA_ "SPN" SG_ 2365402622 Jystck5ThetaAxisNeutralPosStatus 4558;
BA_ "SPN" SG_ 2365402622 Joystick5GripYAxisPos 4557;
BA_ "SigType" SG_ 2365402622 Jystck5GrpYAxsLvrFrwrdPstvPsStts 4;
BA_ "SPN" SG_ 2365402622 Jystck5GrpYAxsLvrFrwrdPstvPsStts 4556;
BA_ "SigType" SG_ 2365402622 Jystck5GrpYAxsLvrBckNgtvPsStatus 4;
BA_ "SPN" SG_ 2365402622 Jystck5GrpYAxsLvrBckNgtvPsStatus 4555;
BA_ "SigType" SG_ 2365402622 Jystck5GripYAxisNeutralPosStatus 4;
BA_ "SPN" SG_ 2365402622 Jystck5GripYAxisNeutralPosStatus 4554;
BA_ "SPN" SG_ 2365402622 Joystick5GripXAxisPos 4553;
BA_ "SigType" SG_ 2365402622 Jystck5GrpXAxsLvrRghtPstvPsSttus 4;
BA_ "SPN" SG_ 2365402622 Jystck5GrpXAxsLvrRghtPstvPsSttus 4552;
BA_ "SigType" SG_ 2365402622 Jystck5GrpXAxsLvrLftNgtvPsStatus 4;
BA_ "SPN" SG_ 2365402622 Jystck5GrpXAxsLvrLftNgtvPsStatus 4551;
BA_ "SigType" SG_ 2365402622 Jystck5GripXAxisNeutralPosStatus 4;
BA_ "SPN" SG_ 2365402622 Jystck5GripXAxisNeutralPosStatus 4550;
BA_ "SigType" SG_ 2365403134 Joystick4Button13PressedStatus 4;
BA_ "SPN" SG_ 2365403134 Joystick4Button13PressedStatus 6743;
BA_ "SigType" SG_ 2365403134 Joystick4Button14PressedStatus 4;
BA_ "SPN" SG_ 2365403134 Joystick4Button14PressedStatus 6744;
BA_ "SigType" SG_ 2365403134 Joystick4Button15PressedStatus 4;
BA_ "SPN" SG_ 2365403134 Joystick4Button15PressedStatus 6745;
BA_ "SigType" SG_ 2365403134 Joystick4Button16PressedStatus 4;
BA_ "SPN" SG_ 2365403134 Joystick4Button16PressedStatus 6746;
BA_ "SigType" SG_ 2365403134 Jystick4GripXAxisDetentPosStatus 4;
BA_ "SPN" SG_ 2365403134 Jystick4GripXAxisDetentPosStatus 4527;
BA_ "SigType" SG_ 2365403134 Jystick4GripYAxisDetentPosStatus 4;
BA_ "SPN" SG_ 2365403134 Jystick4GripYAxisDetentPosStatus 4526;
BA_ "SigType" SG_ 2365403134 Jystick4ThetaAxisDetentPosStatus 4;
BA_ "SPN" SG_ 2365403134 Jystick4ThetaAxisDetentPosStatus 4525;
BA_ "SPN" SG_ 2365403134 Joystick4ThetaAxisPos 4524;
BA_ "SigType" SG_ 2365403134 Jystck4ThtAxsClckwsPstvPosStatus 4;
BA_ "SPN" SG_ 2365403134 Jystck4ThtAxsClckwsPstvPosStatus 4523;
BA_ "SigType" SG_ 2365403134 Jystck4ThtAxsCntrClckwsNgtvPsStt 4;
BA_ "SPN" SG_ 2365403134 Jystck4ThtAxsCntrClckwsNgtvPsStt 4522;
BA_ "SigType" SG_ 2365403134 Jystck4ThetaAxisNeutralPosStatus 4;
BA_ "SPN" SG_ 2365403134 Jystck4ThetaAxisNeutralPosStatus 4521;
BA_ "SPN" SG_ 2365403134 Joystick4GripYAxisPos 4520;
BA_ "SigType" SG_ 2365403134 Jystck4GrpYAxsLvrFrwrdPstvPsStts 4;
BA_ "SPN" SG_ 2365403134 Jystck4GrpYAxsLvrFrwrdPstvPsStts 4519;
BA_ "SigType" SG_ 2365403134 Jystck4GrpYAxsLvrBckNgtvPsStatus 4;
BA_ "SPN" SG_ 2365403134 Jystck4GrpYAxsLvrBckNgtvPsStatus 4518;
BA_ "SigType" SG_ 2365403134 Jystck4GripYAxisNeutralPosStatus 4;
BA_ "SPN" SG_ 2365403134 Jystck4GripYAxisNeutralPosStatus 4517;
BA_ "SPN" SG_ 2365403134 Joystick4GripXAxisPos 4516;
BA_ "SigType" SG_ 2365403134 Jystck4GrpXAxsLvrRghtPstvPsSttus 4;
BA_ "SPN" SG_ 2365403134 Jystck4GrpXAxsLvrRghtPstvPsSttus 4515;
BA_ "SigType" SG_ 2365403134 Jystck4GrpXAxsLvrLftNgtvPsStatus 4;
BA_ "SPN" SG_ 2365403134 Jystck4GrpXAxsLvrLftNgtvPsStatus 4514;
BA_ "SigType" SG_ 2365403134 Jystck4GripXAxisNeutralPosStatus 4;
BA_ "SPN" SG_ 2365403134 Jystck4GripXAxisNeutralPosStatus 4513;
BA_ "SigType" SG_ 2365400062 Joystick10Button13PressedStatus 4;
BA_ "SPN" SG_ 2365400062 Joystick10Button13PressedStatus 6767;
BA_ "SigType" SG_ 2365400062 Joystick10Button14PressedStatus 4;
BA_ "SPN" SG_ 2365400062 Joystick10Button14PressedStatus 6768;
BA_ "SigType" SG_ 2365400062 Joystick10Button15PressedStatus 4;
BA_ "SPN" SG_ 2365400062 Joystick10Button15PressedStatus 6769;
BA_ "SigType" SG_ 2365400062 Joystick10Button16PressedStatus 4;
BA_ "SPN" SG_ 2365400062 Joystick10Button16PressedStatus 6770;
BA_ "SigType" SG_ 2365400062 Jystck10GripXAxisDetentPosStatus 4;
BA_ "SPN" SG_ 2365400062 Jystck10GripXAxisDetentPosStatus 4749;
BA_ "SigType" SG_ 2365400062 Jystck10GripYAxisDetentPosStatus 4;
BA_ "SPN" SG_ 2365400062 Jystck10GripYAxisDetentPosStatus 4748;
BA_ "SigType" SG_ 2365400062 Jystck10ThetaAxisDetentPosStatus 4;
BA_ "SPN" SG_ 2365400062 Jystck10ThetaAxisDetentPosStatus 4747;
BA_ "SPN" SG_ 2365400062 Joystick10ThetaAxisPos 4746;
BA_ "SigType" SG_ 2365400062 Jystck10ThtAxsClckwsPstvPsStatus 4;
BA_ "SPN" SG_ 2365400062 Jystck10ThtAxsClckwsPstvPsStatus 4745;
BA_ "SigType" SG_ 2365400062 Jystck10ThtAxsCntrClckwsNgtvPsSt 4;
BA_ "SPN" SG_ 2365400062 Jystck10ThtAxsCntrClckwsNgtvPsSt 4744;
BA_ "SigType" SG_ 2365400062 Jystck10ThtaAxisNeutralPosStatus 4;
BA_ "SPN" SG_ 2365400062 Jystck10ThtaAxisNeutralPosStatus 4743;
BA_ "SPN" SG_ 2365400062 Joystick10GripYAxisPos 4742;
BA_ "SigType" SG_ 2365400062 Jystck10GrpYAxsLvrFrwrdPstvPsStt 4;
BA_ "SPN" SG_ 2365400062 Jystck10GrpYAxsLvrFrwrdPstvPsStt 4741;
BA_ "SigType" SG_ 2365400062 Jystck10GrpYAxsLvrBckNgtvPsSttus 4;
BA_ "SPN" SG_ 2365400062 Jystck10GrpYAxsLvrBckNgtvPsSttus 4740;
BA_ "SigType" SG_ 2365400062 Jystck10GrpYAxisNeutralPosStatus 4;
BA_ "SPN" SG_ 2365400062 Jystck10GrpYAxisNeutralPosStatus 4739;
BA_ "SPN" SG_ 2365400062 Joystick10GripXAxisPos 4738;
BA_ "SigType" SG_ 2365400062 Jystck10GrpXAxsLvrRghtPstvPsStts 4;
BA_ "SPN" SG_ 2365400062 Jystck10GrpXAxsLvrRghtPstvPsStts 4737;
BA_ "SigType" SG_ 2365400062 Jystck10GrpXAxsLvrLftNgtvPsSttus 4;
BA_ "SPN" SG_ 2365400062 Jystck10GrpXAxsLvrLftNgtvPsSttus 4736;
BA_ "SigType" SG_ 2365400062 Jystck10GrpXAxisNeutralPosStatus 4;
BA_ "SPN" SG_ 2365400062 Jystck10GrpXAxisNeutralPosStatus 4735;
BA_ "SigType" SG_ 2566713598 FuelTankTransferPumpPress 1;
BA_ "SPN" SG_ 2566713598 FuelTankTransferPumpPress 7395;
BA_ "SigType" SG_ 2566713598 FuelTankTransferPump 4;
BA_ "SPN" SG_ 2566713598 FuelTankTransferPump 4010;
BA_ "SigType" SG_ 2566713598 EngFuelFilterDegradation 1;
BA_ "SPN" SG_ 2566713598 EngFuelFilterDegradation 6716;
BA_ "SigType" SG_ 2566713598 EngFuelFilterIntakeAbsPress 1;
BA_ "SPN" SG_ 2566713598 EngFuelFilterIntakeAbsPress 5417;
BA_ "SigType" SG_ 2499604478 EngFuelDeliveryPress 1;
BA_ "SPN" SG_ 2499604478 EngFuelDeliveryPress 7469;
BA_ "SigType" SG_ 2499604478 EngOilPress 1;
BA_ "SPN" SG_ 2499604478 EngOilPress 7468;
BA_ "SigType" SG_ 2499604478 EngExhstGsRcrcltn1OutletAbsPress 1;
BA_ "SPN" SG_ 2499604478 EngExhstGsRcrcltn1OutletAbsPress 5431;
BA_ "SigType" SG_ 2499604478 EngExhstGsRcrcltn1IntakeAbsPress 1;
BA_ "SPN" SG_ 2499604478 EngExhstGsRcrcltn1IntakeAbsPress 5430;
BA_ "SigType" SG_ 2499608830 EngCoolantPress2 1;
BA_ "SPN" SG_ 2499608830 EngCoolantPress2 5708;
BA_ "SigType" SG_ 2499608830 EngExhstGsRcrcltn2IntakeAbsPress 1;
BA_ "SPN" SG_ 2499608830 EngExhstGsRcrcltn2IntakeAbsPress 5429;
BA_ "SigType" SG_ 2499608830 EngExhstGsRcrcltn2OutletAbsPress 1;
BA_ "SPN" SG_ 2499608830 EngExhstGsRcrcltn2OutletAbsPress 5254;
BA_ "SigType" SG_ 2499608830 EngExhstGsRcrclation2IntakePress 1;
BA_ "SPN" SG_ 2499608830 EngExhstGsRcrclation2IntakePress 5253;
BA_ "SigType" SG_ 2499608830 EngExhstGsRcirculation2DiffPress 1;
BA_ "SPN" SG_ 2499608830 EngExhstGsRcirculation2DiffPress 5252;
BA_ "SigType" SG_ 2432499198 CmmndedEngFuelInjectionCtrlPress 1;
BA_ "SPN" SG_ 2432499198 CmmndedEngFuelInjectionCtrlPress 5314;
BA_ "SigType" SG_ 2432499198 CommandedEngFuelRailPress 1;
BA_ "SPN" SG_ 2432499198 CommandedEngFuelRailPress 5313;
BA_ "SigType" SG_ 2432499198 EngExhstGsRcirculation2Valve2Pos 1;
BA_ "SPN" SG_ 2432499198 EngExhstGsRcirculation2Valve2Pos 5263;
BA_ "SigType" SG_ 2432499198 EngExhstGsRecirculation2ValvePos 1;
BA_ "SPN" SG_ 2432499198 EngExhstGsRecirculation2ValvePos 5262;
BA_ "SigType" SG_ 2633825022 EngExhstGsRcrcltn2Valve2PosError 1;
BA_ "SPN" SG_ 2633825022 EngExhstGsRcrcltn2Valve2PosError 5832;
BA_ "SigType" SG_ 2633825022 EngExhstGsRcrcltn2Valve1PosError 1;
BA_ "SPN" SG_ 2633825022 EngExhstGsRcrcltn2Valve1PosError 5831;
BA_ "SigType" SG_ 2633825022 EngExhstGsRcrculation2Valve2Ctrl 1;
BA_ "SPN" SG_ 2633825022 EngExhstGsRcrculation2Valve2Ctrl 5265;
BA_ "SigType" SG_ 2633825022 EngExhstGsRcirculation2ValveCtrl 1;
BA_ "SPN" SG_ 2633825022 EngExhstGsRcirculation2ValveCtrl 5264;
BA_ "SigType" SG_ 2633826046 EGR2CoolerBypassActuatorPos 1;
BA_ "SPN" SG_ 2633826046 EGR2CoolerBypassActuatorPos 5261;
BA_ "SigType" SG_ 2633826046 EngExhstGsRcrcltn2ClerEfficiency 1;
BA_ "SPN" SG_ 2633826046 EngExhstGsRcrcltn2ClerEfficiency 5260;
BA_ "SigType" SG_ 2633826046 EngExhstGsRcrcltn2ClrIntkGsAbsPr 1;
BA_ "SPN" SG_ 2633826046 EngExhstGsRcrcltn2ClrIntkGsAbsPr 5259;
BA_ "SigType" SG_ 2633826046 EngExhstGsRcrcltn2ClerIntakeTemp 1;
BA_ "SPN" SG_ 2633826046 EngExhstGsRcrcltn2ClerIntakeTemp 5258;
BA_ "SigType" SG_ 2566711294 EngFrictionPercentTorquePoint7 1;
BA_ "GenSigStartValue" SG_ 2566711294 EngFrictionPercentTorquePoint7 125;
BA_ "SPN" SG_ 2566711294 EngFrictionPercentTorquePoint7 5477;
BA_ "SigType" SG_ 2566711294 EngFrictionPercentTorquePoint6 1;
BA_ "GenSigStartValue" SG_ 2566711294 EngFrictionPercentTorquePoint6 125;
BA_ "SPN" SG_ 2566711294 EngFrictionPercentTorquePoint6 5476;
BA_ "SigType" SG_ 2566711294 EngFrictionPercentTorquePoint5 1;
BA_ "GenSigStartValue" SG_ 2566711294 EngFrictionPercentTorquePoint5 125;
BA_ "SPN" SG_ 2566711294 EngFrictionPercentTorquePoint5 5475;
BA_ "SigType" SG_ 2566711294 EngFrictionPercentTorquePoint4 1;
BA_ "GenSigStartValue" SG_ 2566711294 EngFrictionPercentTorquePoint4 125;
BA_ "SPN" SG_ 2566711294 EngFrictionPercentTorquePoint4 5474;
BA_ "SigType" SG_ 2566711294 EngFrictionPercentTorquePoint3 1;
BA_ "GenSigStartValue" SG_ 2566711294 EngFrictionPercentTorquePoint3 125;
BA_ "SPN" SG_ 2566711294 EngFrictionPercentTorquePoint3 5473;
BA_ "SigType" SG_ 2566711294 EngFrictionPercentTorquePoint2 1;
BA_ "GenSigStartValue" SG_ 2566711294 EngFrictionPercentTorquePoint2 125;
BA_ "SPN" SG_ 2566711294 EngFrictionPercentTorquePoint2 5472;
BA_ "SigType" SG_ 2566711294 EngFrctnPrcentTorqueAtIdlePoint1 1;
BA_ "GenSigStartValue" SG_ 2566711294 EngFrctnPrcentTorqueAtIdlePoint1 125;
BA_ "SPN" SG_ 2566711294 EngFrctnPrcentTorqueAtIdlePoint1 5471;
BA_ "SigType" SG_ 2566749438 DslPrtcltFltrActvRgnrtnInhbt5629 5;
BA_ "SPN" SG_ 2566749438 DslPrtcltFltrActvRgnrtnInhbt5629 5629;
BA_ "SigType" SG_ 2566749438 AFT1DPFCondNotMetForActiveRegen 5;
BA_ "SPN" SG_ 2566749438 AFT1DPFCondNotMetForActiveRegen 3750;
BA_ "SigType" SG_ 2566749438 HydrocarbonDoserPurgingEnable 5;
BA_ "SPN" SG_ 2566749438 HydrocarbonDoserPurgingEnable 5504;
BA_ "SPN" SG_ 2566749438 DslPrtcltFltrActvRgnrtnFrcdSttus 4175;
BA_ "SPN" SG_ 2566749438 ExhaustSystemHighTempLampCmd 3698;
BA_ "SigType" SG_ 2566749438 DslPrtcltFltrAtmtcActvRgnrtnIntt 5;
BA_ "SPN" SG_ 2566749438 DslPrtcltFltrAtmtcActvRgnrtnIntt 3718;
BA_ "SigType" SG_ 2566749438 DslPrtcltFltrActvRgnrtnInhbt3717 5;
BA_ "SPN" SG_ 2566749438 DslPrtcltFltrActvRgnrtnInhbt3717 3717;
BA_ "SigType" SG_ 2566749438 DslPrtcltFltrActvRgnrtnInhbtdDTE 5;
BA_ "SPN" SG_ 2566749438 DslPrtcltFltrActvRgnrtnInhbtdDTE 3716;
BA_ "SigType" SG_ 2566749438 DslPrtcltFltrActvRgnrtnInhbt3715 4;
BA_ "SPN" SG_ 2566749438 DslPrtcltFltrActvRgnrtnInhbt3715 3715;
BA_ "SigType" SG_ 2566749438 DslPrtcltFltrActvRgnrtnInhbtdDTT 5;
BA_ "SPN" SG_ 2566749438 DslPrtcltFltrActvRgnrtnInhbtdDTT 3714;
BA_ "SigType" SG_ 2566749438 DslPrtcltFltrActvRgnrtnInhbt3713 5;
BA_ "SPN" SG_ 2566749438 DslPrtcltFltrActvRgnrtnInhbt3713 3713;
BA_ "SigType" SG_ 2566749438 DslPrtcltFltrActvRgnrtnInhbt3712 5;
BA_ "SPN" SG_ 2566749438 DslPrtcltFltrActvRgnrtnInhbt3712 3712;
BA_ "SigType" SG_ 2566749438 DslPrtcltFltrActvRgnrtnInhbtdDTL 4;
BA_ "SPN" SG_ 2566749438 DslPrtcltFltrActvRgnrtnInhbtdDTL 3711;
BA_ "SigType" SG_ 2566749438 DslPrtcltFltrActvRgnrtnInhbt3710 5;
BA_ "SPN" SG_ 2566749438 DslPrtcltFltrActvRgnrtnInhbt3710 3710;
BA_ "SigType" SG_ 2566749438 DslPrtcltFltrActvRgnrtnInhbtdDTV 5;
BA_ "SPN" SG_ 2566749438 DslPrtcltFltrActvRgnrtnInhbtdDTV 3709;
BA_ "SigType" SG_ 2566749438 DslPrtcltFltrActvRgnrtnInhbtdDTO 5;
BA_ "SPN" SG_ 2566749438 DslPrtcltFltrActvRgnrtnInhbtdDTO 3708;
BA_ "SigType" SG_ 2566749438 DslPrtcltFltrActvRgnrtnInhbtdDTA 5;
BA_ "SPN" SG_ 2566749438 DslPrtcltFltrActvRgnrtnInhbtdDTA 3707;
BA_ "SigType" SG_ 2566749438 DslPrtcltFltrActvRgnrtnInhbtdDTP 5;
BA_ "SPN" SG_ 2566749438 DslPrtcltFltrActvRgnrtnInhbtdDTP 3706;
BA_ "SigType" SG_ 2566749438 DslPrtcltFltrActvRgnrtnInhbtdDTS 5;
BA_ "SPN" SG_ 2566749438 DslPrtcltFltrActvRgnrtnInhbtdDTS 3705;
BA_ "SigType" SG_ 2566749438 DslPrtcltFltrActvRgnrtnInhbtdDTC 5;
BA_ "SPN" SG_ 2566749438 DslPrtcltFltrActvRgnrtnInhbtdDTC 3704;
BA_ "SigType" SG_ 2566749438 DslPrtcltFltrActvRgnrtnInhbtdDTI 5;
BA_ "SPN" SG_ 2566749438 DslPrtcltFltrActvRgnrtnInhbtdDTI 3703;
BA_ "SigType" SG_ 2566749438 DslPrtcltFltrActvRgnrtnInhbtdStt 5;
BA_ "SPN" SG_ 2566749438 DslPrtcltFltrActvRgnrtnInhbtdStt 3702;
BA_ "SPN" SG_ 2566749438 AFTDPFStatus 3701;
BA_ "SigType" SG_ 2566749438 AFTDPFActiveRegenStatus 5;
BA_ "SPN" SG_ 2566749438 AFTDPFActiveRegenStatus 3700;
BA_ "SigType" SG_ 2566749438 AFTDPFPassiveRegenStatus 5;
BA_ "SPN" SG_ 2566749438 AFTDPFPassiveRegenStatus 3699;
BA_ "SPN" SG_ 2566749438 DieselParticulateFilterLampCmd 3697;
BA_ "SigType" SG_ 2566715646 AFT2DPFSootSignalMin 1;
BA_ "SPN" SG_ 2566715646 AFT2DPFSootSignalMin 5271;
BA_ "SigType" SG_ 2566715646 AFT2DPFSootSignalMax 1;
BA_ "SPN" SG_ 2566715646 AFT2DPFSootSignalMax 5270;
BA_ "SigType" SG_ 2566715646 AFT2DPFSootSignalStdDeviation 1;
BA_ "SPN" SG_ 2566715646 AFT2DPFSootSignalStdDeviation 5269;
BA_ "SigType" SG_ 2566724606 DslPrtcltFltr2StSnsrECUIntrnlTmp 1;
BA_ "SPN" SG_ 2566724606 DslPrtcltFltr2StSnsrECUIntrnlTmp 5570;
BA_ "SPN" SG_ 2566724606 AFT2DPFSootSnsrPreliminaryFMI 4790;
BA_ "SigType" SG_ 2566724606 AFT2DPFMedianSootSignal 1;
BA_ "SPN" SG_ 2566724606 AFT2DPFMedianSootSignal 4789;
BA_ "SigType" SG_ 2566724606 AFT2DPFMeanSootSignal 1;
BA_ "SPN" SG_ 2566724606 AFT2DPFMeanSootSignal 4788;
BA_ "SigType" SG_ 2566724606 AFT2DPFSootDensity 1;
BA_ "SPN" SG_ 2566724606 AFT2DPFSootDensity 4787;
BA_ "SigType" SG_ 2566724606 AFT2DPFSootMass 1;
BA_ "SPN" SG_ 2566724606 AFT2DPFSootMass 4786;
BA_ "SigType" SG_ 2566715902 AFT1DPFSootSignalMin 1;
BA_ "SPN" SG_ 2566715902 AFT1DPFSootSignalMin 5268;
BA_ "SigType" SG_ 2566715902 AFT1DPFSootSignalMax 1;
BA_ "SPN" SG_ 2566715902 AFT1DPFSootSignalMax 5267;
BA_ "SigType" SG_ 2566715902 AFT1DPFSootSignalStdDeviation 1;
BA_ "SPN" SG_ 2566715902 AFT1DPFSootSignalStdDeviation 5266;
BA_ "SigType" SG_ 2566724862 DslPrtcltFltr1StSnsrECUIntrnlTmp 1;
BA_ "SPN" SG_ 2566724862 DslPrtcltFltr1StSnsrECUIntrnlTmp 5569;
BA_ "SPN" SG_ 2566724862 AFT1DPFSootSnsrPreliminaryFMI 4785;
BA_ "SigType" SG_ 2566724862 AFT1DPFMedianSootSignal 1;
BA_ "SPN" SG_ 2566724862 AFT1DPFMedianSootSignal 4784;
BA_ "SigType" SG_ 2566724862 AFT1DPFMeanSootSignal 1;
BA_ "SPN" SG_ 2566724862 AFT1DPFMeanSootSignal 4783;
BA_ "SigType" SG_ 2566724862 AFT1DPFSootDensity 1;
BA_ "SPN" SG_ 2566724862 AFT1DPFSootDensity 4782;
BA_ "SigType" SG_ 2566724862 AFT1DPFSootMass 1;
BA_ "SPN" SG_ 2566724862 AFT1DPFSootMass 4781;
BA_ "SigType" SG_ 2566718718 HillHolderLampData 5;
BA_ "SPN" SG_ 2566718718 HillHolderLampData 1848;
BA_ "SigType" SG_ 2566718718 VehicleBatteryChargingLampData 4;
BA_ "SPN" SG_ 2566718718 VehicleBatteryChargingLampData 5108;
BA_ "SigType" SG_ 2566718718 VehicleHVACRecirculationLampData 4;
BA_ "SPN" SG_ 2566718718 VehicleHVACRecirculationLampData 5107;
BA_ "SigType" SG_ 2566718718 VehicleAirPressLowLampData 4;
BA_ "SPN" SG_ 2566718718 VehicleAirPressLowLampData 5106;
BA_ "SigType" SG_ 2566718718 VehicleFuelLevelLowLampData 4;
BA_ "SPN" SG_ 2566718718 VehicleFuelLevelLowLampData 5105;
BA_ "SigType" SG_ 2566718718 VehicleBatteryVoltageLowLampData 4;
BA_ "SPN" SG_ 2566718718 VehicleBatteryVoltageLowLampData 5104;
BA_ "SigType" SG_ 2566718974 VhclAcclerationRateLimitLampData 4;
BA_ "SPN" SG_ 2566718974 VhclAcclerationRateLimitLampData 6900;
BA_ "SigType" SG_ 2566718974 EngSpeedVeryHighLampData 5;
BA_ "SPN" SG_ 2566718974 EngSpeedVeryHighLampData 6712;
BA_ "SigType" SG_ 2566718974 EngSpeedHighLampData 5;
BA_ "SPN" SG_ 2566718974 EngSpeedHighLampData 6711;
BA_ "SigType" SG_ 2566718974 EngCtrlMdule3ReadyForUseLampData 4;
BA_ "SPN" SG_ 2566718974 EngCtrlMdule3ReadyForUseLampData 6204;
BA_ "SigType" SG_ 2566718974 EngCtrlMdule2ReadyForUseLampData 4;
BA_ "SPN" SG_ 2566718974 EngCtrlMdule2ReadyForUseLampData 6203;
BA_ "SigType" SG_ 2566718974 EngCtrlMdule1ReadyForUseLampData 4;
BA_ "SPN" SG_ 2566718974 EngCtrlMdule1ReadyForUseLampData 6202;
BA_ "SigType" SG_ 2566718974 EngWaitToStartLampData 4;
BA_ "SPN" SG_ 2566718974 EngWaitToStartLampData 5416;
BA_ "SigType" SG_ 2566718974 EngFuelFilterRestrictedLampData 5;
BA_ "SPN" SG_ 2566718974 EngFuelFilterRestrictedLampData 5470;
BA_ "SigType" SG_ 2566718974 EngAirFilterRestrictionLampData 4;
BA_ "SPN" SG_ 2566718974 EngAirFilterRestrictionLampData 5103;
BA_ "SigType" SG_ 2566718974 EngIdleManagementActiveLampData 4;
BA_ "SPN" SG_ 2566718974 EngIdleManagementActiveLampData 5102;
BA_ "SigType" SG_ 2566718974 EngCoolantLevelLowLampData 4;
BA_ "SPN" SG_ 2566718974 EngCoolantLevelLowLampData 5101;
BA_ "SigType" SG_ 2566718974 EngCoolantTempHighLampData 4;
BA_ "SPN" SG_ 2566718974 EngCoolantTempHighLampData 5100;
BA_ "SigType" SG_ 2566718974 EngOilPressLowLampData 4;
BA_ "SPN" SG_ 2566718974 EngOilPressLowLampData 5099;
BA_ "SigType" SG_ 2566718974 CmprssnBrkEnblSwtchIndctrLmpData 4;
BA_ "SPN" SG_ 2566718974 CmprssnBrkEnblSwtchIndctrLmpData 5098;
BA_ "SigType" SG_ 2566718974 EngBrakeActiveLampData 4;
BA_ "SPN" SG_ 2566718974 EngBrakeActiveLampData 5097;
BA_ "SigType" SG_ 2566718974 OBDMalfunctionIndicatorLampData 4;
BA_ "SPN" SG_ 2566718974 OBDMalfunctionIndicatorLampData 5096;
BA_ "SigType" SG_ 2566718974 EngRedStopLampData 4;
BA_ "SPN" SG_ 2566718974 EngRedStopLampData 5095;
BA_ "SigType" SG_ 2566718974 EngAmberWarningLampData 4;
BA_ "SPN" SG_ 2566718974 EngAmberWarningLampData 5094;
BA_ "SigType" SG_ 2566718974 EngProtectLampData 4;
BA_ "SPN" SG_ 2566718974 EngProtectLampData 5093;
BA_ "SigType" SG_ 2566719230 HillHolderLampCmd 5;
BA_ "SPN" SG_ 2566719230 HillHolderLampCmd 1847;
BA_ "SigType" SG_ 2566719230 VehicleBatteryChargingLampCmd 5;
BA_ "SPN" SG_ 2566719230 VehicleBatteryChargingLampCmd 5091;
BA_ "SigType" SG_ 2566719230 VehicleHVACRecirculationLampCmd 5;
BA_ "SPN" SG_ 2566719230 VehicleHVACRecirculationLampCmd 5090;
BA_ "SigType" SG_ 2566719230 VehicleAirPressLowLampCmd 5;
BA_ "SPN" SG_ 2566719230 VehicleAirPressLowLampCmd 5089;
BA_ "SigType" SG_ 2566719230 VehicleFuelLevelLowLampCmd 5;
BA_ "SPN" SG_ 2566719230 VehicleFuelLevelLowLampCmd 5088;
BA_ "SigType" SG_ 2566719230 VehicleBatteryVoltageLowLampCmd 5;
BA_ "SPN" SG_ 2566719230 VehicleBatteryVoltageLowLampCmd 5087;
BA_ "SPN" SG_ 2560818942 SPN1 1214;
BA_ "SPN" SG_ 2560818942 FailureModeIdentifier1 1215;
BA_ "SigType" SG_ 2560818942 DTCTimeUntilDerate 1;
BA_ "SPN" SG_ 2560818942 DTCTimeUntilDerate 4123;
BA_ "SigType" SG_ 2560818942 DTCTotalPreviouslyActiveTime 1;
BA_ "SPN" SG_ 2560818942 DTCTotalPreviouslyActiveTime 4122;
BA_ "SigType" SG_ 2560818942 DTCTotalActiveTime 1;
BA_ "SPN" SG_ 2560818942 DTCTotalActiveTime 4121;
VAL_ 2566722302 GeneratorDutyCycleExceededStatus 3 "Not Avaiable" 2 "Error" 1 "Duty Cycle Exceed" 0 "Duty Cycle Not Exceed" ;
VAL_ 2566722302 VoltageMonitorActiveStatus 3 "Not Available" 2 "Error" 1 "Monitor is On" 0 "Monitor is Off" ;
VAL_ 2566722302 GensetEnableActiveStatus 3 "Not Avaialble" 2 "Error" 1 "Enabled" 0 "Not Enabled" ;
VAL_ 2566722302 ReverseCurrentRangeSetting 31 "Not Available" 30 "Error" 15 "16" 14 "15" 13 "14" 12 "13" 11 "12" 10 "11" 9 "10" 8 "9" 7 "8" 6 "7" 5 "6" 4 "5" 3 "4" 2 "3" 1 "2" 0 "1" ;
VAL_ 2566722302 GensetSoftstartActiveStatus 3 "Not Available" 2 "Error" 1 "On" 0 "Off" ;
VAL_ 2566722302 Grapple_MagnetSelectionSwitch 3 "Not Available" 2 "Error" 1 "Magnet Selected" 0 "Grapple Selected" ;
VAL_ 2566722302 GnstSystmOtputVoltageRangeStatus 3 "Not Available" 2 "Error" 1 "In Range" 0 "Out of Range " ;
VAL_ 2566722302 GeneratorOverheatStatus 3 "Not Available" 2 "Error" 1 "Overheat" 0 "Not Overheat" ;
VAL_ 2560032510 LwVltgDscnnctDsiredOperatingMode 15 "No change" 5 "Manual Connect" 4 "Manual Disconnect" 0 "Automatic" ;
VAL_ 2566717950 LwVltgeDisconnectVoutOutputState 15 "Not available or not installed" 14 "Output fault" 4 "Connect pending" 3 "Disconnect pending" 2 "Disconnect alarm expired" 1 "Output on or connected" 0 "Output off or disconnected" ;
VAL_ 2566717950 LowVoltageDisconnectOutput1State 15 "Not available or not installed" 14 "Output fault" 4 "Connect pending" 3 "Disconnect pending" 2 "Disconnect alarm expired" 1 "Output on or connected" 0 "Output off or disconnected" ;
VAL_ 2566717950 LowVoltageDisconnectOutput2State 14 "Output fault" 4 "Connect pending" 3 "Disconnect pending" 2 "Disconnect alarm expired" 1 "Output on or connected" 0 "Output off or disconnected" 15 "Not available or not installed" ;
VAL_ 2566717950 LowVoltageDisconnectOutput3State 15 "Not available or not installed" 14 "Output fault" 4 "Connect pending" 3 "Disconnect pending" 2 "Disconnect alarm expired" 1 "Output on or connected" 0 "Output off or disconnected" ;
VAL_ 2566717950 LwVltgDscnnctCrrentOperatingMode 15 "Not available" 9 "Manual Connect via hardwired input" 8 "Manual Disconnect via hardwired input" 5 "Manual Connect via J1939 request" 4 "Manual Disconnect via J1939 request" 0 "Automatic" ;
VAL_ 2566717950 LwVltgDscnnectManualConnectState 3 "Not installed" 2 "Error" 1 "Input on" 0 "Input off" ;
VAL_ 2566717950 LwVltgDscnnctMnalDisconnectState 3 "Not installed" 2 "Error" 1 "Input on" 0 "Input off" ;
VAL_ 2358902526 Joystick3Lamp10Cmd 3 "Don't care / Take no action" 2 "Blinking" 1 "On" 0 "Off" ;
VAL_ 2358902526 Joystick3Lamp9Cmd 3 "Don't care / Take no action" 2 "Blinking" 1 "On" 0 "Off" ;
VAL_ 2358902526 Joystick3Lamp8Cmd 3 "Don't care / Take no action" 2 "Blinking" 1 "On" 0 "Off" ;
VAL_ 2358902526 Joystick3Lamp7Cmd 3 "Don't care / Take no action" 2 "Blinking" 1 "On" 0 "Off" ;
VAL_ 2358902526 Joystick3Lamp6Cmd 3 "Don't care / Take no action" 2 "Blinking" 1 "On" 0 "Off" ;
VAL_ 2358902526 Joystick3Lamp5Cmd 3 "Don't care / Take no action" 2 "Blinking" 1 "On" 0 "Off" ;
VAL_ 2358902526 Joystick3Lamp4Cmd 3 "Don't care / Take no action" 2 "Blinking" 1 "On" 0 "Off" ;
VAL_ 2358902526 Joystick3Lamp3Cmd 3 "Don't care / Take no action" 2 "Blinking" 1 "On" 0 "Off" ;
VAL_ 2358902526 Joystick3Lamp2Cmd 3 "Don't care / Take no action" 2 "Blinking" 1 "On" 0 "Off" ;
VAL_ 2358902526 Joystick3Lamp1Cmd 3 "Don't care / Take no action" 2 "Blinking" 1 "On" 0 "Off" ;
VAL_ 2358902526 Joystick2Lamp10Cmd 3 "Don't care / Take no action" 2 "Blinking" 1 "On" 0 "Off" ;
VAL_ 2358902526 Joystick2Lamp9Cmd 3 "Don't care / Take no action" 2 "Blinking" 1 "On" 0 "Off" ;
VAL_ 2358902526 Joystick2Lamp8Cmd 3 "Don't care / Take no action" 2 "Blinking" 1 "On" 0 "Off" ;
VAL_ 2358902526 Joystick2Lamp7Cmd 3 "Don't care / Take no action" 2 "Blinking" 1 "On" 0 "Off" ;
VAL_ 2358902526 Joystick2Lamp6Cmd 3 "Don't care / Take no action" 2 "Blinking" 1 "On" 0 "Off" ;
VAL_ 2358902526 Joystick2Lamp5Cmd 3 "Don't care / Take no action" 2 "Blinking" 1 "On" 0 "Off" ;
VAL_ 2358902526 Joystick2Lamp4Cmd 0 "Off" 3 "Don't care / Take no action" 2 "Blinking" 1 "On" ;
VAL_ 2358902526 Joystick2Lamp3Cmd 3 "Don't care / Take no action" 2 "Blinking" 1 "On" 0 "Off" ;
VAL_ 2358902526 Joystick2Lamp2Cmd 3 "Don't care / Take no action" 2 "Blinking" 1 "On" 0 "Off" ;
VAL_ 2358902526 Joystick2Lamp1Cmd 3 "Don't care / Take no action" 2 "Blinking" 1 "On" 0 "Off" ;
VAL_ 2358902526 Joystick1Lamp10Cmd 3 "Don't care / Take no action" 2 "Blinking" 1 "On" 0 "Off" ;
VAL_ 2358902526 Joystick1Lamp9Cmd 3 "Don't care / Take no action" 2 "Blinking" 1 "On" 0 "Off" ;
VAL_ 2358902526 Joystick1Lamp8Cmd 3 "Don't care / Take no action" 2 "Blinking" 1 "On" 0 "Off" ;
VAL_ 2358902526 Joystick1Lamp7Cmd 3 "Don't care / Take no action" 2 "Blinking" 1 "On" 0 "Off" ;
VAL_ 2358902526 Joystick1Lamp6Cmd 3 "Don't care / Take no action" 2 "Blinking" 1 "On" 0 "Off" ;
VAL_ 2358902526 Joystick1Lamp5Cmd 3 "Don't care / Take no action" 2 "Blinking" 1 "On" 0 "Off" ;
VAL_ 2358902526 Joystick1Lamp4Cmd 3 "Don't care / Take no action" 2 "Blinking" 1 "On" 0 "Off" ;
VAL_ 2358902526 Joystick1Lamp3Cmd 3 "Don't care / Take no action" 2 "Blinking" 1 "On" 0 "Off" ;
VAL_ 2358902526 Joystick1Lamp2Cmd 3 "Don't care / Take no action" 2 "Blinking" 1 "On" 0 "Off" ;
VAL_ 2358902526 Joystick1Lamp1Cmd 3 "Don't care / Take no action" 2 "Blinking" 1 "On" 0 "Off" ;
VAL_ 2566711550 IntkVlvActtnSystmOlPrss2SlndCtrl 3 "not available" 2 "reserved for SAE assignment" 1 "on" 0 "off" ;
VAL_ 2566711550 IntkVlvActtnSystmOlPrss1SlndCtrl 3 "not available" 2 "reserved for SAE assignment" 1 "on" 0 "off" ;
VAL_ 2566713854 EngExhstBckPrssRgltrCtrlOprtnStt 15 "Not available" 14 "Error" 5 "Uncontrolled Shutdown Active" 4 "Controlled Shutdown Active" 3 "Derate Active" 2 "Alarm High Severity" 1 "Alarm" 0 "Normal" ;
VAL_ 2566713854 EngExhstBckPrssRglatorTempStatus 7 "Not available" 6 "Error" 5 "Not Defined" 4 "Low Most severe" 3 "Low Least severe" 2 "In Range" 1 "High Least severe" 0 "High most severe" ;
VAL_ 2566713854 EngTrbWstgtActtr2OperationStatus 14 "Error" 5 "Uncontrolled Shutdown Active" 4 "Controlled Shutdown Active" 3 "Derate Active" 2 "Alarm High Severity" 1 "Alarm" 0 "Normal" ;
VAL_ 2566713854 EngTrbWstgtActtr1OperationStatus 14 "Error" 6 "Calibration in Progress" 5 "Uncontrolled Shutdown Active" 4 "Controlled Shutdown Active" 3 "Derate Active" 2 "Alarm High Severity" 1 "Alarm" 0 "Normal" ;
VAL_ 2566713854 EngTrbWstgateActuator2TempStatus 7 "Not available" 6 "Error" 5 "Not Defined" 4 "Low Most severe" 3 "Low Least severe" 2 "In Range" 1 "High Least severe" 0 "High most severe" ;
VAL_ 2566714366 EngTrbCmprssrBypssActtr2OprtnStt 14 "Error" 5 "Uncontrolled Shutdown Active" 4 "Controlled Shutdown Active" 3 "Derate Active" 2 "Alarm High Severity" 1 "Alarm" 0 "Normal" ;
VAL_ 2566714366 EngTrbCmprssrBypssActtr1OprtnStt 14 "Error" 5 "Uncontrolled Shutdown Active" 4 "Controlled Shutdown Active" 3 "Derate Active" 2 "Alarm High Severity" 1 "Alarm" 0 "Normal" ;
VAL_ 2566714366 EngTrbCmprssrBypssActtr2TmpSttus 7 "Not available" 6 "Error" 5 "Not Defined" 4 "Low Most severe" 3 "Low Least severe" 2 "In Range" 1 "High Least severe" 0 "High most severe" ;
VAL_ 2566714110 EngFuelValve2OperationStatus 14 "Error" 6 "Test Mode Active" 5 "Uncontrolled Shutdown Active" 4 "Controlled Shutdown Active" 3 "Derate Active" 2 "Alarm High Severity" 1 "Alarm" 0 "Normal" ;
VAL_ 2566714110 EngFuelValve1OperationStatus 14 "Error" 6 "Test Mode Active" 5 "Uncontrolled Shutdown Active" 4 "Controlled Shutdown Active" 3 "Derate Active" 2 "Alarm High Severity" 1 "Alarm" 0 "Normal" ;
VAL_ 2566714110 EngThrottleValve2OperationStatus 14 "Error" 5 "Uncontrolled Shutdown Active" 4 "Controlled Shutdown Active" 3 "Derate Active" 2 "Alarm High Severity" 1 "Alarm" 0 "Normal" ;
VAL_ 2566714110 EngThrottleValve1OperationStatus 15 "Not available" 14 "Error" 6 "Calibration in Progress" 5 "Uncontrolled Shutdown Active" 4 "Controlled Shutdown Active" 3 "Derate Active" 2 "Alarm High Severity" 1 "Alarm" 0 "Normal" ;
VAL_ 2566714110 EngFuelValve2TempStatus 7 "Not available" 6 "Error" 5 "Not Defined" 4 "Low Most severe" 3 "Low Least severe" 2 "In Range" 1 "High Least severe" 0 "High most severe" ;
VAL_ 2566714110 EngFuelValve1TempStatus 7 "Not available" 6 "Error" 5 "Not Defined" 4 "Low Most severe" 3 "Low Least severe" 2 "In Range" 1 "High Least severe" 0 "High Most severe" ;
VAL_ 2566714110 EngThrottleValve2TempStatus 7 "Not available" 6 "Error" 5 "Not Defined" 4 "Low Most severe" 3 "Low Least severe" 2 "In Range" 1 "High Least severe" 0 "High Most severe" ;
VAL_ 2566714110 EngThrottleValve1TempStatus 7 "Not available" 6 "Error" 5 "Not Defined" 4 "Low Most severe" 3 "Low Least severe" 2 "In Range" 1 "High Least severe" 0 "High most severe" ;
VAL_ 2365400574 Joystick9Button13PressedStatus 3 "Not Available" 2 "Error Indicator" 1 "Button pressed" 0 "Button not pressed" ;
VAL_ 2365400574 Joystick9Button14PressedStatus 3 "Not Available" 2 "Error Indicator" 1 "Button pressed" 0 "Button not pressed" ;
VAL_ 2365400574 Joystick9Button15PressedStatus 3 "Not Available" 2 "Error Indicator" 1 "Button pressed" 0 "Button not pressed" ;
VAL_ 2365400574 Joystick9Button16PressedStatus 3 "Not Available" 2 "Error Indicator" 1 "Button pressed" 0 "Button not pressed" ;
VAL_ 2365400574 Jystick9GripXAxisDetentPosStatus 3 "Not Available" 2 "Error Indicator" 1 "In the Detent Position" 0 "Not in the Detent Position" ;
VAL_ 2365400574 Jystick9GripYAxisDetentPosStatus 3 "Not Available" 2 "Error Indicator" 1 "In the Detent Position" 0 "Not in the Detent Position" ;
VAL_ 2365400574 Jystick9ThetaAxisDetentPosStatus 3 "Not Available" 2 "Error Indicator" 1 "In the Detent Position" 0 "Not in the Detent Position" ;
VAL_ 2365400574 Jystck9ThtAxsClckwsPstvPosStatus 3 "Not Available" 2 "Error Indicator" 1 "On positive side of Neutral" 0 "Not on Positive side of Neutral" ;
VAL_ 2365400574 Jystck9ThtAxsCntrClckwsNgtvPsStt 3 "Not Available" 2 "Error Indicator" 1 "On negative side of Neutral" 0 "Not on negative side of Neutral" ;
VAL_ 2365400574 Jystck9ThetaAxisNeutralPosStatus 3 "Not Available" 2 "Error Indicator" 1 "In Neutral Position" 0 "Not in Neutral Position" ;
VAL_ 2365400574 Jystck9GrpYAxsLvrFrwrdPstvPsStts 3 "Not Available" 2 "Error Indicator" 1 "On positive side of Neutral" 0 "Not on Positive side of Neutral" ;
VAL_ 2365400574 Jystck9GrpYAxsLvrBckNgtvPsStatus 3 "Not Available" 2 "Error Indicator" 1 "On negative side of Neutral" 0 "Not on negative side of Neutral" ;
VAL_ 2365400574 Jystck9GripYAxisNeutralPosStatus 3 "Not Available" 2 "Error Indicator" 1 "In Neutral Position" 0 "Not in Neutral Position" ;
VAL_ 2365400574 Jystck9GrpXAxsLvrRghtPstvPsSttus 3 "Not Available" 2 "Error Indicator" 1 "On positive side of Neutral" 0 "Not on Positive side of Neutral" ;
VAL_ 2365400574 Jystck9GrpXAxsLvrLftNgtvPsStatus 3 "Not Available" 2 "Error Indicator" 1 "On negative side of Neutral" 0 "Not on negative side of Neutral" ;
VAL_ 2365400574 Jystck9GripXAxisNeutralPosStatus 3 "Not Available" 2 "Error Indicator" 1 "In Neutral Position" 0 "Not in Neutral Position" ;
VAL_ 2365401086 Joystick8Button13PressedStatus 3 "Not Available" 2 "Error Indicator" 1 "Button pressed" 0 "Button not pressed" ;
VAL_ 2365401086 Joystick8Button14PressedStatus 3 "Not Available" 2 "Error Indicator" 1 "Button pressed" 0 "Button not pressed" ;
VAL_ 2365401086 Joystick8Button15PressedStatus 3 "Not Available" 2 "Error Indicator" 1 "Button pressed" 0 "Button not pressed" ;
VAL_ 2365401086 Joystick8Button16PressedStatus 3 "Not Available" 2 "Error Indicator" 1 "Button pressed" 0 "Button not pressed" ;
VAL_ 2365401086 Jystick8GripXAxisDetentPosStatus 3 "Not Available" 2 "Error Indicator" 1 "In the Detent Position" 0 "Not in the Detent Position" ;
VAL_ 2365401086 Jystick8GripYAxisDetentPosStatus 3 "Not Available" 2 "Error Indicator" 1 "In the Detent Position" 0 "Not in the Detent Position" ;
VAL_ 2365401086 Jystick8ThetaAxisDetentPosStatus 3 "Not Available" 2 "Error Indicator" 1 "In the Detent Position" 0 "Not in the Detent Position" ;
VAL_ 2365401086 Jystck8ThtAxsClckwsPstvPosStatus 3 "Not Available" 2 "Error Indicator" 1 "On positive side of Neutral" 0 "Not on Positive side of Neutral" ;
VAL_ 2365401086 Jystck8ThtAxsCntrClckwsNgtvPsStt 3 "Not Available" 2 "Error Indicator" 1 "On negative side of Neutral" 0 "Not on negative side of Neutral" ;
VAL_ 2365401086 Jystck8ThetaAxisNeutralPosStatus 3 "Not Available" 2 "Error Indicator" 1 "In Neutral Position" 0 "Not in Neutral Position" ;
VAL_ 2365401086 Jystck8GrpYAxsLvrFrwrdPstvPsStts 3 "Not Available" 2 "Error Indicator" 1 "On positive side of Neutral" 0 "Not on Positive side of Neutral" ;
VAL_ 2365401086 Jystck8GrpYAxsLvrBckNgtvPsStatus 3 "Not Available" 2 "Error Indicator" 1 "On negative side of Neutral" 0 "Not on negative side of Neutral" ;
VAL_ 2365401086 Jystck8GripYAxisNeutralPosStatus 3 "Not Available" 2 "Error Indicator" 1 "In Neutral Position" 0 "Not in Neutral Position" ;
VAL_ 2365401086 Jystck8GrpXAxsLvrRghtPstvPsSttus 3 "Not Available" 2 "Error Indicator" 1 "On positive side of Neutral" 0 "Not on Positive side of Neutral" ;
VAL_ 2365401086 Jystck8GrpXAxsLvrLftNgtvPsStatus 3 "Not Available" 2 "Error Indicator" 1 "On negative side of Neutral" 0 "Not on negative side of Neutral" ;
VAL_ 2365401086 Jystck8GripXAxisNeutralPosStatus 3 "Not Available" 2 "Error Indicator" 1 "In Neutral Position" 0 "Not in Neutral Position" ;
VAL_ 2365401598 Joystick7Button13PressedStatus 3 "Not Available" 2 "Error Indicator" 1 "Button pressed" 0 "Button not pressed" ;
VAL_ 2365401598 Joystick7Button14PressedStatus 3 "Not Available" 2 "Error Indicator" 1 "Button pressed" 0 "Button not pressed" ;
VAL_ 2365401598 Joystick7Button15PressedStatus 3 "Not Available" 2 "Error Indicator" 1 "Button pressed" 0 "Button not pressed" ;
VAL_ 2365401598 Joystick7Button16PressedStatus 3 "Not Available" 2 "Error Indicator" 1 "Button pressed" 0 "Button not pressed" ;
VAL_ 2365401598 Jystick7GripXAxisDetentPosStatus 3 "Not Available" 2 "Error Indicator" 1 "In the Detent Position" 0 "Not in the Detent Position" ;
VAL_ 2365401598 Jystick7GripYAxisDetentPosStatus 3 "Not Available" 2 "Error Indicator" 1 "In the Detent Position" 0 "Not in the Detent Position" ;
VAL_ 2365401598 Jystick7ThetaAxisDetentPosStatus 3 "Not Available" 2 "Error Indicator" 1 "In the Detent Position" 0 "Not in the Detent Position" ;
VAL_ 2365401598 Jystck7ThtAxsClckwsPstvPosStatus 3 "Not Available" 2 "Error Indicator" 1 "On positive side of Neutral" 0 "Not on Positive side of Neutral" ;
VAL_ 2365401598 Jystck7ThtAxsCntrClckwsNgtvPsStt 3 "Not Available" 2 "Error Indicator" 1 "On negative side of Neutral" 0 "Not on negative side of Neutral" ;
VAL_ 2365401598 Jystck7ThetaAxisNeutralPosStatus 3 "Not Available" 2 "Error Indicator" 1 "In Neutral Position" 0 "Not in Neutral Position" ;
VAL_ 2365401598 Jystck7GrpYAxsLvrFrwrdPstvPsStts 3 "Not Available" 2 "Error Indicator" 1 "On positive side of Neutral" 0 "Not on Positive side of Neutral" ;
VAL_ 2365401598 Jystck7GrpYAxsLvrBckNgtvPsStatus 3 "Not Available" 2 "Error Indicator" 1 "On negative side of Neutral" 0 "Not on negative side of Neutral" ;
VAL_ 2365401598 Jystck7GripYAxisNeutralPosStatus 3 "Not Available" 2 "Error Indicator" 1 "In Neutral Position" 0 "Not in Neutral Position" ;
VAL_ 2365401598 Jystck7GrpXAxsLvrRghtPstvPsSttus 3 "Not Available" 2 "Error Indicator" 1 "On positive side of Neutral" 0 "Not on Positive side of Neutral" ;
VAL_ 2365401598 Jystck7GrpXAxsLvrLftNgtvPsStatus 3 "Not Available" 2 "Error Indicator" 1 "On negative side of Neutral" 0 "Not on negative side of Neutral" ;
VAL_ 2365401598 Jystck7GripXAxisNeutralPosStatus 3 "Not Available" 2 "Error Indicator" 1 "In Neutral Position" 0 "Not in Neutral Position" ;
VAL_ 2365402110 Joystick6Button13PressedStatus 3 "Not Available" 2 "Error Indicator" 1 "Button pressed" 0 "Button not pressed" ;
VAL_ 2365402110 Joystick6Button14PressedStatus 3 "Not Available" 2 "Error Indicator" 1 "Button pressed" 0 "Button not pressed" ;
VAL_ 2365402110 Joystick6Button15PressedStatus 3 "Not Available" 2 "Error Indicator" 1 "Button pressed" 0 "Button not pressed" ;
VAL_ 2365402110 Joystick6Button16PressedStatus 3 "Not Available" 2 "Error Indicator" 1 "Button pressed" 0 "Button not pressed" ;
VAL_ 2365402110 Jystick6GripXAxisDetentPosStatus 3 "Not Available" 2 "Error Indicator" 1 "In the Detent Position" 0 "Not in the Detent Position" ;
VAL_ 2365402110 Jystick6GripYAxisDetentPosStatus 3 "Not Available" 2 "Error Indicator" 1 "In the Detent Position" 0 "Not in the Detent Position" ;
VAL_ 2365402110 Jystick6ThetaAxisDetentPosStatus 3 "Not Available" 2 "Error Indicator" 1 "In the Detent Position" 0 "Not in the Detent Position" ;
VAL_ 2365402110 Jystck6ThtAxsClckwsPstvPosStatus 3 "Not Available" 2 "Error Indicator" 1 "On positive side of Neutral" 0 "Not on Positive side of Neutral" ;
VAL_ 2365402110 Jystck6ThtAxsCntrClckwsNgtvPsStt 3 "Not Available" 2 "Error Indicator" 1 "On negative side of Neutral" 0 "Not on negative side of Neutral" ;
VAL_ 2365402110 Jystck6ThetaAxisNeutralPosStatus 3 "Not Available" 2 "Error Indicator" 1 "In Neutral Position" 0 "Not in Neutral Position" ;
VAL_ 2365402110 Jystck6GrpYAxsLvrFrwrdPstvPsStts 3 "Not Available" 2 "Error Indicator" 1 "On positive side of Neutral" 0 "Not on Positive side of Neutral" ;
VAL_ 2365402110 Jystck6GrpYAxsLvrBckNgtvPsStatus 3 "Not Available" 2 "Error Indicator" 1 "On negative side of Neutral" 0 "Not on negative side of Neutral" ;
VAL_ 2365402110 Jystck6GripYAxisNeutralPosStatus 3 "Not Available" 2 "Error Indicator" 1 "In Neutral Position" 0 "Not in Neutral Position" ;
VAL_ 2365402110 Jystck6GrpXAxsLvrRghtPstvPsSttus 3 "Not Available" 2 "Error Indicator" 1 "On positive side of Neutral" 0 "Not on Positive side of Neutral" ;
VAL_ 2365402110 Jystck6GrpXAxsLvrLftNgtvPsStatus 3 "Not Available" 2 "Error Indicator" 1 "On negative side of Neutral" 0 "Not on negative side of Neutral" ;
VAL_ 2365402110 Jystck6GripXAxisNeutralPosStatus 3 "Not Available" 2 "Error Indicator" 1 "In Neutral Position" 0 "Not in Neutral Position" ;
VAL_ 2365402622 Joystick5Button13PressedStatus 3 "Not Available" 2 "Error Indicator" 1 "Button pressed" 0 "Button not pressed" ;
VAL_ 2365402622 Joystick5Button14PressedStatus 3 "Not Available" 2 "Error Indicator" 1 "Button pressed" 0 "Button not pressed" ;
VAL_ 2365402622 Joystick5Button15PressedStatus 3 "Not Available" 2 "Error Indicator" 1 "Button pressed" 0 "Button not pressed" ;
VAL_ 2365402622 Joystick5Button16PressedStatus 3 "Not Available" 2 "Error Indicator" 1 "Button pressed" 0 "Button not pressed" ;
VAL_ 2365402622 Jystick5GripXAxisDetentPosStatus 3 "Not Available" 2 "Error Indicator" 1 "In the Detent Position" 0 "Not in the Detent Position" ;
VAL_ 2365402622 Jystick5GripYAxisDetentPosStatus 3 "Not Available" 2 "Error Indicator" 1 "In the Detent Position" 0 "Not in the Detent Position" ;
VAL_ 2365402622 Jystick5ThetaAxisDetentPosStatus 3 "Not Available" 2 "Error Indicator" 1 "In the Detent Position" 0 "Not in the Detent Position" ;
VAL_ 2365402622 Jystck5ThtAxsClckwsPstvPosStatus 3 "Not Available" 2 "Error Indicator" 1 "On positive side of Neutral" 0 "Not on Positive side of Neutral" ;
VAL_ 2365402622 Jystck5ThtAxsCntrClckwsNgtvPsStt 3 "Not Available" 2 "Error Indicator" 1 "On negative side of Neutral" 0 "Not on negative side of Neutral" ;
VAL_ 2365402622 Jystck5ThetaAxisNeutralPosStatus 3 "Not Available" 2 "Error Indicator" 1 "In Neutral Position" 0 "Not in Neutral Position" ;
VAL_ 2365402622 Jystck5GrpYAxsLvrFrwrdPstvPsStts 3 "Not Available" 2 "Error Indicator" 1 "On positive side of Neutral" 0 "Not on Positive side of Neutral" ;
VAL_ 2365402622 Jystck5GrpYAxsLvrBckNgtvPsStatus 3 "Not Available" 2 "Error Indicator" 1 "On negative side of Neutral" 0 "Not on negative side of Neutral" ;
VAL_ 2365402622 Jystck5GripYAxisNeutralPosStatus 3 "Not Available" 2 "Error Indicator" 1 "In Neutral Position" 0 "Not in Neutral Position" ;
VAL_ 2365402622 Jystck5GrpXAxsLvrRghtPstvPsSttus 3 "Not Available" 2 "Error Indicator" 1 "On positive side of Neutral" 0 "Not on Positive side of Neutral" ;
VAL_ 2365402622 Jystck5GrpXAxsLvrLftNgtvPsStatus 3 "Not Available" 2 "Error Indicator" 1 "On negative side of Neutral" 0 "Not on negative side of Neutral" ;
VAL_ 2365402622 Jystck5GripXAxisNeutralPosStatus 3 "Not Available" 2 "Error Indicator" 1 "In Neutral Position" 0 "Not in Neutral Position" ;
VAL_ 2365403134 Joystick4Button13PressedStatus 3 "Not Available" 2 "Error Indicator" 1 "Button pressed" 0 "Button not pressed" ;
VAL_ 2365403134 Joystick4Button14PressedStatus 3 "Not Available" 2 "Error Indicator" 1 "Button pressed" 0 "Button not pressed" ;
VAL_ 2365403134 Joystick4Button15PressedStatus 3 "Not Available" 2 "Error Indicator" 1 "Button pressed" 0 "Button not pressed" ;
VAL_ 2365403134 Joystick4Button16PressedStatus 3 "Not Available" 2 "Error Indicator" 1 "Button pressed" 0 "Button not pressed" ;
VAL_ 2365403134 Jystick4GripXAxisDetentPosStatus 3 "Not Available" 2 "Error Indicator" 1 "In the Detent Position" 0 "Not in the Detent Position" ;
VAL_ 2365403134 Jystick4GripYAxisDetentPosStatus 3 "Not Available" 2 "Error Indicator" 1 "In the Detent Position" 0 "Not in the Detent Position" ;
VAL_ 2365403134 Jystick4ThetaAxisDetentPosStatus 3 "Not Available" 2 "Error Indicator" 1 "In the Detent Position" 0 "Not in the Detent Position" ;
VAL_ 2365403134 Jystck4ThtAxsClckwsPstvPosStatus 3 "Not Available" 2 "Error Indicator" 1 "On positive side of Neutral" 0 "Not on Positive side of Neutral" ;
VAL_ 2365403134 Jystck4ThtAxsCntrClckwsNgtvPsStt 3 "Not Available" 2 "Error Indicator" 1 "On negative side of Neutral" 0 "Not on negative side of Neutral" ;
VAL_ 2365403134 Jystck4ThetaAxisNeutralPosStatus 3 "Not Available" 2 "Error Indicator" 1 "In Neutral Position" 0 "Not in Neutral Position" ;
VAL_ 2365403134 Jystck4GrpYAxsLvrFrwrdPstvPsStts 3 "Not Available" 2 "Error Indicator" 1 "On positive side of Neutral" 0 "Not on Positive side of Neutral" ;
VAL_ 2365403134 Jystck4GrpYAxsLvrBckNgtvPsStatus 3 "Not Available" 2 "Error Indicator" 1 "On negative side of Neutral" 0 "Not on negative side of Neutral" ;
VAL_ 2365403134 Jystck4GripYAxisNeutralPosStatus 3 "Not Available" 2 "Error Indicator" 1 "In Neutral Position" 0 "Not in Neutral Position" ;
VAL_ 2365403134 Jystck4GrpXAxsLvrRghtPstvPsSttus 3 "Not Available" 2 "Error Indicator" 1 "On positive side of Neutral" 0 "Not on Positive side of Neutral" ;
VAL_ 2365403134 Jystck4GrpXAxsLvrLftNgtvPsStatus 3 "Not Available" 2 "Error Indicator" 1 "On negative side of Neutral" 0 "Not on negative side of Neutral" ;
VAL_ 2365403134 Jystck4GripXAxisNeutralPosStatus 3 "Not Available" 2 "Error Indicator" 1 "In Neutral Position" 0 "Not in Neutral Position" ;
VAL_ 2365400062 Joystick10Button13PressedStatus 3 "Not Available" 2 "Error Indicator" 1 "Button pressed" 0 "Button not pressed" ;
VAL_ 2365400062 Joystick10Button14PressedStatus 3 "Not Available" 2 "Error Indicator" 1 "Button pressed" 0 "Button not pressed" ;
VAL_ 2365400062 Joystick10Button15PressedStatus 3 "Not Available" 2 "Error Indicator" 1 "Button pressed" 0 "Button not pressed" ;
VAL_ 2365400062 Joystick10Button16PressedStatus 3 "Not Available" 2 "Error Indicator" 1 "Button pressed" 0 "Button not pressed" ;
VAL_ 2365400062 Jystck10GripXAxisDetentPosStatus 3 "Not Available" 2 "Error Indicator" 1 "In the Detent Position" 0 "Not in the Detent Position" ;
VAL_ 2365400062 Jystck10GripYAxisDetentPosStatus 3 "Not Available" 2 "Error Indicator" 1 "In the Detent Position" 0 "Not in the Detent Position" ;
VAL_ 2365400062 Jystck10ThetaAxisDetentPosStatus 3 "Not Available" 2 "Error Indicator" 1 "In the Detent Position" 0 "Not in the Detent Position" ;
VAL_ 2365400062 Jystck10ThtAxsClckwsPstvPsStatus 3 "Not Available" 2 "Error Indicator" 1 "On positive side of Neutral" 0 "Not on Positive side of Neutral" ;
VAL_ 2365400062 Jystck10ThtAxsCntrClckwsNgtvPsSt 3 "Not Available" 2 "Error Indicator" 1 "On negative side of Neutral" 0 "Not on negative side of Neutral" ;
VAL_ 2365400062 Jystck10ThtaAxisNeutralPosStatus 3 "Not Available" 2 "Error Indicator" 1 "In Neutral Position" 0 "Not in Neutral Position" ;
VAL_ 2365400062 Jystck10GrpYAxsLvrFrwrdPstvPsStt 3 "Not Available" 2 "Error Indicator" 1 "On positive side of Neutral" 0 "Not on Positive side of Neutral" ;
VAL_ 2365400062 Jystck10GrpYAxsLvrBckNgtvPsSttus 3 "Not Available" 2 "Error Indicator" 1 "On negative side of Neutral" 0 "Not on negative side of Neutral" ;
VAL_ 2365400062 Jystck10GrpYAxisNeutralPosStatus 3 "Not Available" 2 "Error Indicator" 1 "In Neutral Position" 0 "Not in Neutral Position" ;
VAL_ 2365400062 Jystck10GrpXAxsLvrRghtPstvPsStts 3 "Not Available" 2 "Error Indicator" 1 "On positive side of Neutral" 0 "Not on Positive side of Neutral" ;
VAL_ 2365400062 Jystck10GrpXAxsLvrLftNgtvPsSttus 3 "Not Available" 2 "Error Indicator" 1 "On negative side of Neutral" 0 "Not on negative side of Neutral" ;
VAL_ 2365400062 Jystck10GrpXAxisNeutralPosStatus 3 "Not Available" 2 "Error Indicator" 1 "In Neutral Position" 0 "Not in Neutral Position" ;
VAL_ 2566713598 FuelTankTransferPump 3 "Not available" 2 "Error" 1 "On" 0 "Off" ;
VAL_ 2566749438 DslPrtcltFltrActvRgnrtnInhbt5629 3 "not available" 2 "reserved for SAE assignment" 1 "inhibited" 0 "not inhibited" ;
VAL_ 2566749438 AFT1DPFCondNotMetForActiveRegen 3 "not available" 2 "reserved for SAE assignment" 1 "active DPF regeneration inhibited" 0 "active DPF regeneration not inhibited" ;
VAL_ 2566749438 HydrocarbonDoserPurgingEnable 3 "Not available" 2 "Purging enabled, urgent" 1 "Purging enabled, less urgent" 0 "Purging not enabled" ;
VAL_ 2566749438 DslPrtcltFltrActvRgnrtnFrcdSttus 3 "Reserved for SAE Assignment" 2 "Active, Forced by Service Tool " 1 "Active, Forced by Switch" 0 "Not Active" 7 "not available" 6 "Reserved for SAE Assignment" 5 "Reserved for SAE Assignment" 4 "Reserved for SAE Assignment" ;
VAL_ 2566749438 ExhaustSystemHighTempLampCmd 7 "not available" 6 "reserved for SAE assignment" 5 "reserved for SAE assignment" 4 "reserved for SAE assignment" 3 "reserved for SAE assignment" 2 "reserved for SAE assignment " 1 "On" 0 "Off" ;
VAL_ 2566749438 DslPrtcltFltrAtmtcActvRgnrtnIntt 3 "not available" 2 "reserved for SAE assignment" 1 "enabled" 0 "not enabled" ;
VAL_ 2566749438 DslPrtcltFltrActvRgnrtnInhbt3717 3 "not available" 2 "reserved for SAE assignment" 1 "inhibited" 0 "not inhibited" ;
VAL_ 2566749438 DslPrtcltFltrActvRgnrtnInhbtdDTE 3 "not available" 2 "reserved for SAE assignment" 1 "inhibited" 0 "not inhibited" ;
VAL_ 2566749438 DslPrtcltFltrActvRgnrtnInhbt3715 3 "not available" 2 "reserved for SAE assignment" 1 "inhibited" 0 "not inhibited" ;
VAL_ 2566749438 DslPrtcltFltrActvRgnrtnInhbtdDTT 3 "not available" 2 "reserved for SAE assignment" 1 "inhibited" 0 "not inhibited" ;
VAL_ 2566749438 DslPrtcltFltrActvRgnrtnInhbt3713 3 "not available" 2 "reserved for SAE assignment" 1 "inhibited" 0 "not inhibited" ;
VAL_ 2566749438 DslPrtcltFltrActvRgnrtnInhbt3712 3 "not available" 2 "reserved for SAE assignment" 1 "inhibited" 0 "not inhibited" ;
VAL_ 2566749438 DslPrtcltFltrActvRgnrtnInhbtdDTL 3 "not available" 2 "reserved for SAE assignment" 1 "inhibited" 0 "not inhibited" ;
VAL_ 2566749438 DslPrtcltFltrActvRgnrtnInhbt3710 3 "not available" 2 "reserved for SAE assignment" 1 "inhibited" 0 "not inhibited" ;
VAL_ 2566749438 DslPrtcltFltrActvRgnrtnInhbtdDTV 3 "not available" 2 "reserved for SAE assignment" 1 "inhibited" 0 "not inhibited" ;
VAL_ 2566749438 DslPrtcltFltrActvRgnrtnInhbtdDTO 3 "not available" 2 "reserved for SAE assignment" 1 "inhibited" 0 "not inhibited" ;
VAL_ 2566749438 DslPrtcltFltrActvRgnrtnInhbtdDTA 3 "not available" 2 "reserved for SAE assignment" 1 "inhibited" 0 "not inhibited" ;
VAL_ 2566749438 DslPrtcltFltrActvRgnrtnInhbtdDTP 3 "not available" 2 "reserved for SAE assignment" 1 "inhibited" 0 "not inhibited" ;
VAL_ 2566749438 DslPrtcltFltrActvRgnrtnInhbtdDTS 3 "not available" 2 "reserved for SAE assignment" 1 "inhibited" 0 "not inhibited" ;
VAL_ 2566749438 DslPrtcltFltrActvRgnrtnInhbtdDTC 3 "not available" 2 "reserved for SAE assignment" 1 "inhibited" 0 "not inhibited" ;
VAL_ 2566749438 DslPrtcltFltrActvRgnrtnInhbtdDTI 3 "not available" 2 "reserved for SAE assignment" 1 "inhibited" 0 "not inhibited" ;
VAL_ 2566749438 DslPrtcltFltrActvRgnrtnInhbtdStt 3 "not available" 2 "reserved for SAE assignment" 1 "inhibited" 0 "not inhibited" ;
VAL_ 2566749438 AFTDPFStatus 7 "not available" 6 "reserved for SAE assignment" 5 "reserved for SAE assignment" 4 "reserved for SAE assignment" 3 "Regeneration needed, highest level" 2 "Regeneration needed, moderate level" 1 "Regeneration needed, lowest level" 0 "Regeneration not needed" ;
VAL_ 2566749438 AFTDPFActiveRegenStatus 3 "not available" 2 "regeneration needed" 1 "active" 0 "not active" ;
VAL_ 2566749438 AFTDPFPassiveRegenStatus 3 "not available" 2 "reserved for SAE assignment" 1 "active" 0 "not active" ;
VAL_ 2566749438 DieselParticulateFilterLampCmd 7 "not available" 6 "reserved for SAE assignment" 5 "reserved for SAE assignment" 4 "On, fast blink" 3 "reserved for SAE assignment" 2 "reserved for SAE assignment " 1 "On, solid" 0 "Off" ;
VAL_ 2566718718 HillHolderLampData 3 "Not Available" 2 "Error" 1 "Lamp activated" 0 "Lamp deactivated" ;
VAL_ 2566718718 VehicleBatteryChargingLampData 3 "Not available" 2 "Error" 1 "Lamp activated" 0 "Lamp deactivated" ;
VAL_ 2566718718 VehicleHVACRecirculationLampData 3 "Not available" 2 "Error" 1 "Lamp activated" 0 "Lamp deactivated" ;
VAL_ 2566718718 VehicleAirPressLowLampData 3 "Not available" 2 "Error" 1 "Lamp activated" 0 "Lamp deactivated" ;
VAL_ 2566718718 VehicleFuelLevelLowLampData 3 "Not available" 2 "Error" 1 "Lamp activated" 0 "Lamp deactivated" ;
VAL_ 2566718718 VehicleBatteryVoltageLowLampData 3 "Not available" 2 "Error" 1 "Lamp activated" 0 "Lamp deactivated" ;
VAL_ 2566718974 VhclAcclerationRateLimitLampData 3 "Not available" 2 "Error" 1 "Lamp activated" 0 "Lamp deactivated" ;
VAL_ 2566718974 EngSpeedVeryHighLampData 3 "Not available" 2 "Error" 1 "Lamp Activated" 0 "Lamp Deactivated" ;
VAL_ 2566718974 EngSpeedHighLampData 0 "Lamp Deactivated" 3 "Not available" 2 "Error" 1 "Lamp Activated" ;
VAL_ 2566718974 EngCtrlMdule3ReadyForUseLampData 3 "Not Available" 2 "Error" 1 "Lamp activated" 0 "Lamp deactivated" ;
VAL_ 2566718974 EngCtrlMdule2ReadyForUseLampData 3 "Not Available" 2 "Error" 1 "Lamp activated" 0 "Lamp deactivated" ;
VAL_ 2566718974 EngCtrlMdule1ReadyForUseLampData 3 "Not Available" 2 "Error" 1 "Lamp activated" 0 "Lamp deactivated" ;
VAL_ 2566718974 EngWaitToStartLampData 3 "Not available" 2 "Error" 1 "Lamp actived" 0 "Lamp deactived" ;
VAL_ 2566718974 EngFuelFilterRestrictedLampData 3 "Not available" 2 "Error" 1 "Lamp activated" 0 "Lamp deactivated" ;
VAL_ 2566718974 EngAirFilterRestrictionLampData 3 "Not available" 2 "Error" 1 "Lamp activated" 0 "Lamp deactivated" ;
VAL_ 2566718974 EngIdleManagementActiveLampData 3 "Not available" 2 "Error" 1 "Lamp activated" 0 "Lamp deactivated" ;
VAL_ 2566718974 EngCoolantLevelLowLampData 3 "Not available" 2 "Error" 1 "Lamp activated" 0 "Lamp deactivated" ;
VAL_ 2566718974 EngCoolantTempHighLampData 3 "Not available" 2 "Error" 1 "Lamp activated" 0 "Lamp deactivated" ;
VAL_ 2566718974 EngOilPressLowLampData 3 "Not available" 2 "Error" 1 "Lamp activated" 0 "Lamp deactivated" ;
VAL_ 2566718974 CmprssnBrkEnblSwtchIndctrLmpData 3 "Not available" 2 "Error" 1 "Lamp activated" 0 "Lamp deactivated" ;
VAL_ 2566718974 EngBrakeActiveLampData 3 "Not available" 2 "Error" 1 "Lamp activated" 0 "Lamp deactivated" ;
VAL_ 2566718974 OBDMalfunctionIndicatorLampData 3 "Not available" 2 "Error" 1 "Lamp activated" 0 "Lamp deactivated" ;
VAL_ 2566718974 EngRedStopLampData 3 "Not available" 2 "Error" 1 "Lamp activated" 0 "Lamp deactivated" ;
VAL_ 2566718974 EngAmberWarningLampData 3 "Not available" 2 "Error" 1 "Lamp activated" 0 "Lamp deactivated" ;
VAL_ 2566718974 EngProtectLampData 3 "Not available" 2 "Error" 1 "Lamp activated" 0 "Lamp deactivated" ;
VAL_ 2566719230 HillHolderLampCmd 3 "Not available" 2 "Lamp Flash" 1 "Lamp On" 0 "Lamp Off" ;
VAL_ 2566719230 VehicleBatteryChargingLampCmd 3 "Not available" 2 "Reserved" 1 "Lamp On" 0 "Lamp Off" ;
VAL_ 2566719230 VehicleHVACRecirculationLampCmd 3 "Not available" 2 "Reserved" 1 "Lamp On" 0 "Lamp Off" ;
VAL_ 2566719230 VehicleAirPressLowLampCmd 3 "Not available" 2 "Reserved" 1 "Lamp On" 0 "Lamp Off" ;
VAL_ 2566719230 VehicleFuelLevelLowLampCmd 3 "Not available" 2 "Reserved" 1 "Lamp On" 0 "Lamp Off" ;
VAL_ 2566719230 VehicleBatteryVoltageLowLampCmd 3 "Not available" 2 "Reserved" 1 "Lamp On" 0 "Lamp Off" ;
VAL_ 2560818942 FailureModeIdentifier1 31 "Not available" 19 "Received network data in error" 18 "Below normal (moderately severe)" 17 "Below normal (least severe)" 16 "Above normal (moderately severe)" 15 "Above normal (least severe)" 14 "Special intstructions" 13 "Out of calibration" 12 "Bad intelligent device" 11 "Root cause not known" 10 "Abnormal rate of change" 9 "Abnormal update rate" 8 "Abnormal frequency" 7 "Mechanical system not responding" 6 "Current above normal" 5 "Current below normal" 4 "Voltage below normal" 3 "Voltage above normal" 2 "Data erratic" 1 "Below normal (most severe)" 0 "Above normal (most severe)" ;
